VERSION "dbc-export 1 2025.20.8"

NS_ :

BS_:

BU_: ADSP APSB BB BMS CMP CP DAS DI DIF DIR DPB EPASTP EPASTS GTW ICR IDB OCS1P PM PMF PMR PTC RCM RCU TCU UI UIS VCLEFT VCSEC

BO_ 1297 RCM_alertLog: 8 RCM
 SG_ RCM_alertID M : 0|10@1+ (1,0) [0|1023] "" Vector__XXX
 SG_ RCM_a104_eventDriverBrakeApply m104 : 46|2@1+ (1,0) [0|2] "" Vector__XXX
 SG_ RCM_a104_eventAccelPedalPos m104 : 56|8@1+ (0.4,0) [0|101.6] "%" Vector__XXX
 SG_ RCM_a105_eventArmStatus m105 : 11|1@1+ (1,0) [0|1] "" Vector__XXX
 SG_ RCM_a105_eventFactoryMode m105 : 12|1@1+ (1,0) [0|1] "" Vector__XXX
 SG_ RCM_a105_eventDiagEnabled m105 : 13|1@1+ (1,0) [0|1] "" Vector__XXX
 SG_ RCM_a105_eventDriveOrientation m105 : 14|1@1+ (1,0) [0|1] "" Vector__XXX
 SG_ RCM_a105_imuLongAOffCompPosLife m105 : 16|1@1+ (1,0) [0|1] "" Vector__XXX
 SG_ RCM_a105_imuLongAOffCompNegLife m105 : 17|1@1+ (1,0) [0|1] "" Vector__XXX
 SG_ RCM_a105_imuLongAOffCompPosFLDC m105 : 18|1@1+ (1,0) [0|1] "" Vector__XXX
 SG_ RCM_a105_imuLongAOffCompNegFLDC m105 : 19|1@1+ (1,0) [0|1] "" Vector__XXX
 SG_ RCM_a105_imuLongAOffCompPosSLDC m105 : 20|1@1+ (1,0) [0|1] "" Vector__XXX
 SG_ RCM_a105_imuLongAOffCompNegSLDC m105 : 21|1@1+ (1,0) [0|1] "" Vector__XXX
 SG_ RCM_a105_eventIDFsignal m105 : 25|1@1+ (1,0) [0|1] "" Vector__XXX
 SG_ RCM_a105_eventFrontLeftSeatbelt m105 : 26|1@1+ (1,0) [0|1] "" Vector__XXX
 SG_ RCM_a105_eventFrontRightSeatbelt m105 : 27|1@1+ (1,0) [0|1] "" Vector__XXX
 SG_ RCM_a105_eventVehicleSpeed m105 : 28|12@1+ (0.08,-40) [-40|287.6] "kph" Vector__XXX
 SG_ RCM_a105_eventSteeringAngle m105 : 45|14@0+ (0.1,-819.2) [-819.2|819.1] "deg" Vector__XXX
 SG_ RCM_a105_eventDriverBrakeApply m105 : 46|2@1+ (1,0) [0|2] "" Vector__XXX
 SG_ RCM_a105_eventAccelPedalPos m105 : 56|8@1+ (0.4,0) [0|101.6] "%" Vector__XXX
 SG_ RCM_a106_eventArmStatus m106 : 11|1@1+ (1,0) [0|1] "" Vector__XXX
 SG_ RCM_a106_eventFactoryMode m106 : 12|1@1+ (1,0) [0|1] "" Vector__XXX
 SG_ RCM_a106_eventDiagEnabled m106 : 13|1@1+ (1,0) [0|1] "" Vector__XXX
 SG_ RCM_a106_eventDriveOrientation m106 : 14|1@1+ (1,0) [0|1] "" Vector__XXX
 SG_ RCM_a106_imuLatAcOffCompPosLife m106 : 16|1@1+ (1,0) [0|1] "" Vector__XXX
 SG_ RCM_a106_imuLatAcOffCompNegLife m106 : 17|1@1+ (1,0) [0|1] "" Vector__XXX
 SG_ RCM_a106_imuLatAcOffCompPosFLDC m106 : 18|1@1+ (1,0) [0|1] "" Vector__XXX
 SG_ RCM_a106_imuLatAcOffCompNegFLDC m106 : 19|1@1+ (1,0) [0|1] "" Vector__XXX
 SG_ RCM_a106_imuLatAcOffCompPosSLDC m106 : 20|1@1+ (1,0) [0|1] "" Vector__XXX
 SG_ RCM_a106_imuLatAcOffCompNegSLDC m106 : 21|1@1+ (1,0) [0|1] "" Vector__XXX
 SG_ RCM_a106_eventIDFsignal m106 : 25|1@1+ (1,0) [0|1] "" Vector__XXX
 SG_ RCM_a106_eventFrontLeftSeatbelt m106 : 26|1@1+ (1,0) [0|1] "" Vector__XXX
 SG_ RCM_a106_eventFrontRightSeatbelt m106 : 27|1@1+ (1,0) [0|1] "" Vector__XXX
 SG_ RCM_a106_eventVehicleSpeed m106 : 28|12@1+ (0.08,-40) [-40|287.6] "kph" Vector__XXX
 SG_ RCM_a106_eventSteeringAngle m106 : 45|14@0+ (0.1,-819.2) [-819.2|819.1] "deg" Vector__XXX
 SG_ RCM_a106_eventDriverBrakeApply m106 : 46|2@1+ (1,0) [0|2] "" Vector__XXX
 SG_ RCM_a106_eventAccelPedalPos m106 : 56|8@1+ (0.4,0) [0|101.6] "%" Vector__XXX
 SG_ RCM_a107_eventArmStatus m107 : 11|1@1+ (1,0) [0|1] "" Vector__XXX
 SG_ RCM_a107_eventFactoryMode m107 : 12|1@1+ (1,0) [0|1] "" Vector__XXX
 SG_ RCM_a107_eventDiagEnabled m107 : 13|1@1+ (1,0) [0|1] "" Vector__XXX
 SG_ RCM_a107_eventDriveOrientation m107 : 14|1@1+ (1,0) [0|1] "" Vector__XXX
 SG_ RCM_a107_imuVertAOffCompPosLife m107 : 16|1@1+ (1,0) [0|1] "" Vector__XXX
 SG_ RCM_a107_imuVertAOffCompNegLife m107 : 17|1@1+ (1,0) [0|1] "" Vector__XXX
 SG_ RCM_a107_imuVertAOffCompPosFLDC m107 : 18|1@1+ (1,0) [0|1] "" Vector__XXX
 SG_ RCM_a107_imuVertAOffCompNegFLDC m107 : 19|1@1+ (1,0) [0|1] "" Vector__XXX
 SG_ RCM_a107_imuVertAOffCompPosSLDC m107 : 20|1@1+ (1,0) [0|1] "" Vector__XXX
 SG_ RCM_a107_imuVertAOffCompNegSLDC m107 : 21|1@1+ (1,0) [0|1] "" Vector__XXX
 SG_ RCM_a107_eventIDFsignal m107 : 25|1@1+ (1,0) [0|1] "" Vector__XXX
 SG_ RCM_a107_eventFrontLeftSeatbelt m107 : 26|1@1+ (1,0) [0|1] "" Vector__XXX
 SG_ RCM_a107_eventFrontRightSeatbelt m107 : 27|1@1+ (1,0) [0|1] "" Vector__XXX
 SG_ RCM_a107_eventVehicleSpeed m107 : 28|12@1+ (0.08,-40) [-40|287.6] "kph" Vector__XXX
 SG_ RCM_a107_eventSteeringAngle m107 : 45|14@0+ (0.1,-819.2) [-819.2|819.1] "deg" Vector__XXX
 SG_ RCM_a107_eventDriverBrakeApply m107 : 46|2@1+ (1,0) [0|2] "" Vector__XXX
 SG_ RCM_a107_eventAccelPedalPos m107 : 56|8@1+ (0.4,0) [0|101.6] "%" Vector__XXX
 SG_ RCM_a108_eventArmStatus m108 : 11|1@1+ (1,0) [0|1] "" Vector__XXX
 SG_ RCM_a108_eventFactoryMode m108 : 12|1@1+ (1,0) [0|1] "" Vector__XXX
 SG_ RCM_a108_eventDiagEnabled m108 : 13|1@1+ (1,0) [0|1] "" Vector__XXX
 SG_ RCM_a108_eventDriveOrientation m108 : 14|1@1+ (1,0) [0|1] "" Vector__XXX
 SG_ RCM_a108_crashAlgoWakeupSig m108 : 16|1@1+ (1,0) [0|1] "" Vector__XXX
 SG_ RCM_a108_eventIDFsignal m108 : 25|1@1+ (1,0) [0|1] "" Vector__XXX
 SG_ RCM_a108_eventFrontLeftSeatbelt m108 : 26|1@1+ (1,0) [0|1] "" Vector__XXX
 SG_ RCM_a108_eventFrontRightSeatbelt m108 : 27|1@1+ (1,0) [0|1] "" Vector__XXX
 SG_ RCM_a108_eventVehicleSpeed m108 : 28|12@1+ (0.08,-40) [-40|287.6] "kph" Vector__XXX
 SG_ RCM_a108_eventSteeringAngle m108 : 45|14@0+ (0.1,-819.2) [-819.2|819.1] "deg" Vector__XXX
 SG_ RCM_a108_eventDriverBrakeApply m108 : 46|2@1+ (1,0) [0|2] "" Vector__XXX
 SG_ RCM_a108_eventAccelPedalPos m108 : 56|8@1+ (0.4,0) [0|101.6] "%" Vector__XXX
 SG_ RCM_a109_eventArmStatus m109 : 11|1@1+ (1,0) [0|1] "" Vector__XXX
 SG_ RCM_a109_eventFactoryMode m109 : 12|1@1+ (1,0) [0|1] "" Vector__XXX
 SG_ RCM_a109_eventDiagEnabled m109 : 13|1@1+ (1,0) [0|1] "" Vector__XXX
 SG_ RCM_a109_eventDriveOrientation m109 : 14|1@1+ (1,0) [0|1] "" Vector__XXX
 SG_ RCM_a109_immunityThrsholdCrossed m109 : 16|1@1+ (1,0) [0|1] "" Vector__XXX
 SG_ RCM_a109_eventIDFsignal m109 : 25|1@1+ (1,0) [0|1] "" Vector__XXX
 SG_ RCM_a109_eventFrontLeftSeatbelt m109 : 26|1@1+ (1,0) [0|1] "" Vector__XXX
 SG_ RCM_a109_eventFrontRightSeatbelt m109 : 27|1@1+ (1,0) [0|1] "" Vector__XXX
 SG_ RCM_a109_eventVehicleSpeed m109 : 28|12@1+ (0.08,-40) [-40|287.6] "kph" Vector__XXX
 SG_ RCM_a109_eventSteeringAngle m109 : 45|14@0+ (0.1,-819.2) [-819.2|819.1] "deg" Vector__XXX
 SG_ RCM_a109_eventDriverBrakeApply m109 : 46|2@1+ (1,0) [0|2] "" Vector__XXX
 SG_ RCM_a109_eventAccelPedalPos m109 : 56|8@1+ (0.4,0) [0|101.6] "%" Vector__XXX
 SG_ RCM_a110_eventArmStatus m110 : 11|1@1+ (1,0) [0|1] "" Vector__XXX
 SG_ RCM_a110_eventFactoryMode m110 : 12|1@1+ (1,0) [0|1] "" Vector__XXX
 SG_ RCM_a110_eventDiagEnabled m110 : 13|1@1+ (1,0) [0|1] "" Vector__XXX
 SG_ RCM_a110_eventDriveOrientation m110 : 14|1@1+ (1,0) [0|1] "" Vector__XXX
 SG_ RCM_a110_inFactoryMode m110 : 16|1@1+ (1,0) [0|1] "" Vector__XXX
 SG_ RCM_a110_eventIDFsignal m110 : 25|1@1+ (1,0) [0|1] "" Vector__XXX
 SG_ RCM_a110_eventFrontLeftSeatbelt m110 : 26|1@1+ (1,0) [0|1] "" Vector__XXX
 SG_ RCM_a110_eventFrontRightSeatbelt m110 : 27|1@1+ (1,0) [0|1] "" Vector__XXX
 SG_ RCM_a110_eventVehicleSpeed m110 : 28|12@1+ (0.08,-40) [-40|287.6] "kph" Vector__XXX
 SG_ RCM_a110_eventSteeringAngle m110 : 45|14@0+ (0.1,-819.2) [-819.2|819.1] "deg" Vector__XXX
 SG_ RCM_a110_eventDriverBrakeApply m110 : 46|2@1+ (1,0) [0|2] "" Vector__XXX
 SG_ RCM_a110_eventAccelPedalPos m110 : 56|8@1+ (0.4,0) [0|101.6] "%" Vector__XXX
 SG_ RCM_a112_eventArmStatus m112 : 11|1@1+ (1,0) [0|1] "" Vector__XXX
 SG_ RCM_a112_eventFactoryMode m112 : 12|1@1+ (1,0) [0|1] "" Vector__XXX
 SG_ RCM_a112_eventDiagEnabled m112 : 13|1@1+ (1,0) [0|1] "" Vector__XXX
 SG_ RCM_a112_eventDriveOrientation m112 : 14|1@1+ (1,0) [0|1] "" Vector__XXX
 SG_ RCM_a112_imuYawR8SnsrMonitTmp m112 : 16|1@1+ (1,0) [0|1] "" Vector__XXX
 SG_ RCM_a112_imuYawR8SnsrMonitPerm m112 : 17|1@1+ (1,0) [0|1] "" Vector__XXX
 SG_ RCM_a112_imuYawR8ChnlMonitTmp m112 : 19|1@1+ (1,0) [0|1] "" Vector__XXX
 SG_ RCM_a112_imuYawR8ChnlMonitPerm m112 : 20|1@1+ (1,0) [0|1] "" Vector__XXX
 SG_ RCM_a112_eventIDFsignal m112 : 25|1@1+ (1,0) [0|1] "" Vector__XXX
 SG_ RCM_a112_eventFrontLeftSeatbelt m112 : 26|1@1+ (1,0) [0|1] "" Vector__XXX
 SG_ RCM_a112_eventFrontRightSeatbelt m112 : 27|1@1+ (1,0) [0|1] "" Vector__XXX
 SG_ RCM_a112_eventVehicleSpeed m112 : 28|12@1+ (0.08,-40) [-40|287.6] "kph" Vector__XXX
 SG_ RCM_a112_eventSteeringAngle m112 : 45|14@0+ (0.1,-819.2) [-819.2|819.1] "deg" Vector__XXX
 SG_ RCM_a112_eventDriverBrakeApply m112 : 46|2@1+ (1,0) [0|2] "" Vector__XXX
 SG_ RCM_a112_eventAccelPedalPos m112 : 56|8@1+ (0.4,0) [0|101.6] "%" Vector__XXX
 SG_ RCM_a113_eventArmStatus m113 : 11|1@1+ (1,0) [0|1] "" Vector__XXX
 SG_ RCM_a113_eventFactoryMode m113 : 12|1@1+ (1,0) [0|1] "" Vector__XXX
 SG_ RCM_a113_eventDiagEnabled m113 : 13|1@1+ (1,0) [0|1] "" Vector__XXX
 SG_ RCM_a113_eventDriveOrientation m113 : 14|1@1+ (1,0) [0|1] "" Vector__XXX
 SG_ RCM_a113_imuPitchR8SnsrMonitTmp m113 : 16|1@1+ (1,0) [0|1] "" Vector__XXX
 SG_ RCM_a113_imuPitchR8SnsrMonitPerm m113 : 17|1@1+ (1,0) [0|1] "" Vector__XXX
 SG_ RCM_a113_imuPitchR8ChnlMonitTmp m113 : 18|1@1+ (1,0) [0|1] "" Vector__XXX
 SG_ RCM_a113_imuPitchR8ChnlMonitPerm m113 : 19|1@1+ (1,0) [0|1] "" Vector__XXX
 SG_ RCM_a113_eventIDFsignal m113 : 25|1@1+ (1,0) [0|1] "" Vector__XXX
 SG_ RCM_a113_eventFrontLeftSeatbelt m113 : 26|1@1+ (1,0) [0|1] "" Vector__XXX
 SG_ RCM_a113_eventFrontRightSeatbelt m113 : 27|1@1+ (1,0) [0|1] "" Vector__XXX
 SG_ RCM_a113_eventVehicleSpeed m113 : 28|12@1+ (0.08,-40) [-40|287.6] "kph" Vector__XXX
 SG_ RCM_a113_eventSteeringAngle m113 : 45|14@0+ (0.1,-819.2) [-819.2|819.1] "deg" Vector__XXX
 SG_ RCM_a113_eventDriverBrakeApply m113 : 46|2@1+ (1,0) [0|2] "" Vector__XXX
 SG_ RCM_a113_eventAccelPedalPos m113 : 56|8@1+ (0.4,0) [0|101.6] "%" Vector__XXX
 SG_ RCM_a114_eventArmStatus m114 : 11|1@1+ (1,0) [0|1] "" Vector__XXX
 SG_ RCM_a114_eventFactoryMode m114 : 12|1@1+ (1,0) [0|1] "" Vector__XXX
 SG_ RCM_a114_eventDiagEnabled m114 : 13|1@1+ (1,0) [0|1] "" Vector__XXX
 SG_ RCM_a114_eventDriveOrientation m114 : 14|1@1+ (1,0) [0|1] "" Vector__XXX
 SG_ RCM_a114_imuRollR8SnsrMonitTmp m114 : 16|1@1+ (1,0) [0|1] "" Vector__XXX
 SG_ RCM_a114_imuRollR8SnsrMonitPerm m114 : 17|1@1+ (1,0) [0|1] "" Vector__XXX
 SG_ RCM_a114_imuRollR8ChnlMonitTmp m114 : 18|1@1+ (1,0) [0|1] "" Vector__XXX
 SG_ RCM_a114_imuRollR8ChnlMonitPerm m114 : 19|1@1+ (1,0) [0|1] "" Vector__XXX
 SG_ RCM_a114_eventIDFsignal m114 : 25|1@1+ (1,0) [0|1] "" Vector__XXX
 SG_ RCM_a114_eventFrontLeftSeatbelt m114 : 26|1@1+ (1,0) [0|1] "" Vector__XXX
 SG_ RCM_a114_eventFrontRightSeatbelt m114 : 27|1@1+ (1,0) [0|1] "" Vector__XXX
 SG_ RCM_a114_eventVehicleSpeed m114 : 28|12@1+ (0.08,-40) [-40|287.6] "kph" Vector__XXX
 SG_ RCM_a114_eventSteeringAngle m114 : 45|14@0+ (0.1,-819.2) [-819.2|819.1] "deg" Vector__XXX
 SG_ RCM_a114_eventDriverBrakeApply m114 : 46|2@1+ (1,0) [0|2] "" Vector__XXX
 SG_ RCM_a114_eventAccelPedalPos m114 : 56|8@1+ (0.4,0) [0|101.6] "%" Vector__XXX
 SG_ RCM_a115_eventArmStatus m115 : 11|1@1+ (1,0) [0|1] "" Vector__XXX
 SG_ RCM_a115_eventFactoryMode m115 : 12|1@1+ (1,0) [0|1] "" Vector__XXX
 SG_ RCM_a115_eventDiagEnabled m115 : 13|1@1+ (1,0) [0|1] "" Vector__XXX
 SG_ RCM_a115_eventDriveOrientation m115 : 14|1@1+ (1,0) [0|1] "" Vector__XXX
 SG_ RCM_a115_imuLinAccChnlMonitTmp m115 : 16|1@1+ (1,0) [0|1] "" Vector__XXX
 SG_ RCM_a115_imuLinAccChnlMonitPerm m115 : 17|1@1+ (1,0) [0|1] "" Vector__XXX
 SG_ RCM_a115_eventIDFsignal m115 : 25|1@1+ (1,0) [0|1] "" Vector__XXX
 SG_ RCM_a115_eventFrontLeftSeatbelt m115 : 26|1@1+ (1,0) [0|1] "" Vector__XXX
 SG_ RCM_a115_eventFrontRightSeatbelt m115 : 27|1@1+ (1,0) [0|1] "" Vector__XXX
 SG_ RCM_a115_eventVehicleSpeed m115 : 28|12@1+ (0.08,-40) [-40|287.6] "kph" Vector__XXX
 SG_ RCM_a115_eventSteeringAngle m115 : 45|14@0+ (0.1,-819.2) [-819.2|819.1] "deg" Vector__XXX
 SG_ RCM_a115_eventDriverBrakeApply m115 : 46|2@1+ (1,0) [0|2] "" Vector__XXX
 SG_ RCM_a115_eventAccelPedalPos m115 : 56|8@1+ (0.4,0) [0|101.6] "%" Vector__XXX
 SG_ RCM_a116_eventArmStatus m116 : 11|1@1+ (1,0) [0|1] "" Vector__XXX
 SG_ RCM_a116_eventFactoryMode m116 : 12|1@1+ (1,0) [0|1] "" Vector__XXX
 SG_ RCM_a116_eventDiagEnabled m116 : 13|1@1+ (1,0) [0|1] "" Vector__XXX
 SG_ RCM_a116_eventDriveOrientation m116 : 14|1@1+ (1,0) [0|1] "" Vector__XXX
 SG_ RCM_a116_imuLatAccChnlMonitTmp m116 : 16|1@1+ (1,0) [0|1] "" Vector__XXX
 SG_ RCM_a116_imuLatAccChnlMonitPerm m116 : 17|1@1+ (1,0) [0|1] "" Vector__XXX
 SG_ RCM_a116_eventIDFsignal m116 : 25|1@1+ (1,0) [0|1] "" Vector__XXX
 SG_ RCM_a116_eventFrontLeftSeatbelt m116 : 26|1@1+ (1,0) [0|1] "" Vector__XXX
 SG_ RCM_a116_eventFrontRightSeatbelt m116 : 27|1@1+ (1,0) [0|1] "" Vector__XXX
 SG_ RCM_a116_eventVehicleSpeed m116 : 28|12@1+ (0.08,-40) [-40|287.6] "kph" Vector__XXX
 SG_ RCM_a116_eventSteeringAngle m116 : 45|14@0+ (0.1,-819.2) [-819.2|819.1] "deg" Vector__XXX
 SG_ RCM_a116_eventDriverBrakeApply m116 : 46|2@1+ (1,0) [0|2] "" Vector__XXX
 SG_ RCM_a116_eventAccelPedalPos m116 : 56|8@1+ (0.4,0) [0|101.6] "%" Vector__XXX
 SG_ RCM_a117_eventArmStatus m117 : 11|1@1+ (1,0) [0|1] "" Vector__XXX
 SG_ RCM_a117_eventFactoryMode m117 : 12|1@1+ (1,0) [0|1] "" Vector__XXX
 SG_ RCM_a117_eventDiagEnabled m117 : 13|1@1+ (1,0) [0|1] "" Vector__XXX
 SG_ RCM_a117_eventDriveOrientation m117 : 14|1@1+ (1,0) [0|1] "" Vector__XXX
 SG_ RCM_a117_imuZaccelChnlMonitTmp m117 : 16|1@1+ (1,0) [0|1] "" Vector__XXX
 SG_ RCM_a117_imuZaccelChnlMonitPerm m117 : 17|1@1+ (1,0) [0|1] "" Vector__XXX
 SG_ RCM_a117_eventIDFsignal m117 : 25|1@1+ (1,0) [0|1] "" Vector__XXX
 SG_ RCM_a117_eventFrontLeftSeatbelt m117 : 26|1@1+ (1,0) [0|1] "" Vector__XXX
 SG_ RCM_a117_eventFrontRightSeatbelt m117 : 27|1@1+ (1,0) [0|1] "" Vector__XXX
 SG_ RCM_a117_eventVehicleSpeed m117 : 28|12@1+ (0.08,-40) [-40|287.6] "kph" Vector__XXX
 SG_ RCM_a117_eventSteeringAngle m117 : 45|14@0+ (0.1,-819.2) [-819.2|819.1] "deg" Vector__XXX
 SG_ RCM_a117_eventDriverBrakeApply m117 : 46|2@1+ (1,0) [0|2] "" Vector__XXX
 SG_ RCM_a117_eventAccelPedalPos m117 : 56|8@1+ (0.4,0) [0|101.6] "%" Vector__XXX
 SG_ RCM_a118_eventArmStatus m118 : 11|1@1+ (1,0) [0|1] "" Vector__XXX
 SG_ RCM_a118_eventFactoryMode m118 : 12|1@1+ (1,0) [0|1] "" Vector__XXX
 SG_ RCM_a118_eventDiagEnabled m118 : 13|1@1+ (1,0) [0|1] "" Vector__XXX
 SG_ RCM_a118_eventDriveOrientation m118 : 14|1@1+ (1,0) [0|1] "" Vector__XXX
 SG_ RCM_a118_imuInPlaneSnsrMonitTmp m118 : 16|1@1+ (1,0) [0|1] "" Vector__XXX
 SG_ RCM_a118_imuInPlaneSnsrMonitPerm m118 : 17|1@1+ (1,0) [0|1] "" Vector__XXX
 SG_ RCM_a118_eventIDFsignal m118 : 25|1@1+ (1,0) [0|1] "" Vector__XXX
 SG_ RCM_a118_eventFrontLeftSeatbelt m118 : 26|1@1+ (1,0) [0|1] "" Vector__XXX
 SG_ RCM_a118_eventFrontRightSeatbelt m118 : 27|1@1+ (1,0) [0|1] "" Vector__XXX
 SG_ RCM_a118_eventVehicleSpeed m118 : 28|12@1+ (0.08,-40) [-40|287.6] "kph" Vector__XXX
 SG_ RCM_a118_eventSteeringAngle m118 : 45|14@0+ (0.1,-819.2) [-819.2|819.1] "deg" Vector__XXX
 SG_ RCM_a118_eventDriverBrakeApply m118 : 46|2@1+ (1,0) [0|2] "" Vector__XXX
 SG_ RCM_a118_eventAccelPedalPos m118 : 56|8@1+ (0.4,0) [0|101.6] "%" Vector__XXX

BO_ 881 RCM_alertMatrix: 8 RCM
 SG_ RCM_matrixIndex M : 0|4@1+ (1,0) [0|15] "" Vector__XXX
 SG_ RCM_a000_crashDetected m0 : 4|1@1+ (1,0) [0|1] "" Vector__XXX
 SG_ RCM_a001_nearDeploy m0 : 5|1@1+ (1,0) [0|1] "" Vector__XXX
 SG_ RCM_a002_airbagsNotArmed m0 : 6|1@1+ (1,0) [0|1] "" Vector__XXX
 SG_ RCM_a003_warningIndicator m0 : 7|1@1+ (1,0) [0|1] "" Vector__XXX
 SG_ RCM_a004_internalFault m0 : 8|1@1+ (1,0) [0|1] "" Vector__XXX
 SG_ RCM_a005_crcError m0 : 9|1@1+ (1,0) [0|1] "" Vector__XXX
 SG_ RCM_a006_batteryVoltageRange m0 : 10|1@1+ (1,0) [0|1] "" Vector__XXX
 SG_ RCM_a007_powerSupplyExternal m0 : 11|1@1+ (1,0) [0|1] "" Vector__XXX
 SG_ RCM_a008_powerSupplyInternal m0 : 12|1@1+ (1,0) [0|1] "" Vector__XXX
 SG_ RCM_a009_reprogramLimit m0 : 13|1@1+ (1,0) [0|1] "" Vector__XXX
 SG_ RCM_a010_scmDisabled m0 : 14|1@1+ (1,0) [0|1] "" Vector__XXX
 SG_ RCM_a011_eepromDataLocked m0 : 15|1@1+ (1,0) [0|1] "" Vector__XXX
 SG_ RCM_a012_vinStorage m0 : 16|1@1+ (1,0) [0|1] "" Vector__XXX
 SG_ RCM_a013_driverOrientation m0 : 17|1@1+ (1,0) [0|1] "" Vector__XXX
 SG_ RCM_a014_driverABStage1 m0 : 18|1@1+ (1,0) [0|1] "" Vector__XXX
 SG_ RCM_a015_driverABStage2 m0 : 19|1@1+ (1,0) [0|1] "" Vector__XXX
 SG_ RCM_a016_passABStage1 m0 : 20|1@1+ (1,0) [0|1] "" Vector__XXX
 SG_ RCM_a017_passABStage2 m0 : 21|1@1+ (1,0) [0|1] "" Vector__XXX
 SG_ RCM_a018_passengerActiveVent m0 : 22|1@1+ (1,0) [0|1] "" Vector__XXX
 SG_ RCM_a019_pretenShldrFrontLeft m0 : 23|1@1+ (1,0) [0|1] "" Vector__XXX
 SG_ RCM_a020_pretenShldFrontRight m0 : 24|1@1+ (1,0) [0|1] "" Vector__XXX
 SG_ RCM_a021_pretenLapFrontLeft m0 : 25|1@1+ (1,0) [0|1] "" Vector__XXX
 SG_ RCM_a022_pretenLapFrontRight m0 : 26|1@1+ (1,0) [0|1] "" Vector__XXX
 SG_ RCM_a023_loadLimiterLeftSide m0 : 27|1@1+ (1,0) [0|1] "" Vector__XXX
 SG_ RCM_a024_loadLimiterRightSide m0 : 28|1@1+ (1,0) [0|1] "" Vector__XXX
 SG_ RCM_a025_kneeABDriver m0 : 29|1@1+ (1,0) [0|1] "" Vector__XXX
 SG_ RCM_a026_kneeABFrontPassenger m0 : 30|1@1+ (1,0) [0|1] "" Vector__XXX
 SG_ RCM_a027_sideAB1stRowLeft m0 : 31|1@1+ (1,0) [0|1] "" Vector__XXX
 SG_ RCM_a028_sideAB1stRowRight m0 : 32|1@1+ (1,0) [0|1] "" Vector__XXX
 SG_ RCM_a029_driverABActiveVent m0 : 33|1@1+ (1,0) [0|1] "" Vector__XXX
 SG_ RCM_a030_farSideInboardAirbag m0 : 34|1@1+ (1,0) [0|1] "" Vector__XXX
 SG_ RCM_a031_frontCenterAirbag m0 : 35|1@1+ (1,0) [0|1] "" Vector__XXX
 SG_ RCM_a032_curtainABLeft m0 : 36|1@1+ (1,0) [0|1] "" Vector__XXX
 SG_ RCM_a033_curtainABRight m0 : 37|1@1+ (1,0) [0|1] "" Vector__XXX
 SG_ RCM_a034_preten2ndRowLeft m0 : 38|1@1+ (1,0) [0|1] "" Vector__XXX
 SG_ RCM_a035_preten2ndRowRight m0 : 39|1@1+ (1,0) [0|1] "" Vector__XXX
 SG_ RCM_a036_curAB2ndRowLeft m0 : 40|1@1+ (1,0) [0|1] "" Vector__XXX
 SG_ RCM_a037_curAB2ndRowRight m0 : 41|1@1+ (1,0) [0|1] "" Vector__XXX
 SG_ RCM_a038_unusedA m0 : 42|1@1+ (1,0) [0|1] "" Vector__XXX
 SG_ RCM_a039_unusedB m0 : 43|1@1+ (1,0) [0|1] "" Vector__XXX
 SG_ RCM_a040_hoodActuatorRight m0 : 44|1@1+ (1,0) [0|1] "" Vector__XXX
 SG_ RCM_a041_hoodActuatorLeft m0 : 45|1@1+ (1,0) [0|1] "" Vector__XXX
 SG_ RCM_a042_ens1Line m0 : 46|1@1+ (1,0) [0|1] "" Vector__XXX
 SG_ RCM_a043_ens2Line m0 : 47|1@1+ (1,0) [0|1] "" Vector__XXX
 SG_ RCM_a044_upFrontSensorLeft m0 : 48|1@1+ (1,0) [0|1] "" Vector__XXX
 SG_ RCM_a045_upFrontSensorRight m0 : 49|1@1+ (1,0) [0|1] "" Vector__XXX
 SG_ RCM_a046_sideAccelBPillarLeft m0 : 50|1@1+ (1,0) [0|1] "" Vector__XXX
 SG_ RCM_a047_sideAccelBPillarRight m0 : 51|1@1+ (1,0) [0|1] "" Vector__XXX
 SG_ RCM_a048_sideAccelCPillarLeft m0 : 52|1@1+ (1,0) [0|1] "" Vector__XXX
 SG_ RCM_a049_sideAccelCPillarRight m0 : 53|1@1+ (1,0) [0|1] "" Vector__XXX
 SG_ RCM_a050_upFrontSensorCenter m0 : 54|1@1+ (1,0) [0|1] "" Vector__XXX
 SG_ RCM_a051_pressureFrontLftDoor m0 : 55|1@1+ (1,0) [0|1] "" Vector__XXX
 SG_ RCM_a052_pressureFrontRtDoor m0 : 56|1@1+ (1,0) [0|1] "" Vector__XXX
 SG_ RCM_a053_pressurePedProLeft m0 : 57|1@1+ (1,0) [0|1] "" Vector__XXX
 SG_ RCM_a054_pressurePedProRight m0 : 58|1@1+ (1,0) [0|1] "" Vector__XXX
 SG_ RCM_a055_inertialMeasurement m0 : 59|1@1+ (1,0) [0|1] "" Vector__XXX
 SG_ RCM_a056_passengerFrontOCS m0 : 60|1@1+ (1,0) [0|1] "" Vector__XXX
 SG_ RCM_a057_driverOCS m0 : 61|1@1+ (1,0) [0|1] "" Vector__XXX
 SG_ RCM_a058_buckle1stRowLeft m0 : 62|1@1+ (1,0) [0|1] "" Vector__XXX
 SG_ RCM_a059_buckle1stRowRight m0 : 63|1@1+ (1,0) [0|1] "" Vector__XXX
 SG_ RCM_a060_stpsLeft m1 : 4|1@1+ (1,0) [0|1] "" Vector__XXX
 SG_ RCM_a061_stpsRight m1 : 5|1@1+ (1,0) [0|1] "" Vector__XXX
 SG_ RCM_a062_alrSwitch m1 : 6|1@1+ (1,0) [0|1] "" Vector__XXX
 SG_ RCM_a063_sbsw2ndRowRight m1 : 7|1@1+ (1,0) [0|1] "" Vector__XXX
 SG_ RCM_a064_hardwareCodingPin1 m1 : 8|1@1+ (1,0) [0|1] "" Vector__XXX
 SG_ RCM_a065_driverOrientConfigPin m1 : 9|1@1+ (1,0) [0|1] "" Vector__XXX
 SG_ RCM_a066_seatBackSw2ndRowLeft m1 : 10|1@1+ (1,0) [0|1] "" Vector__XXX
 SG_ RCM_a067_comCANInitFailure m1 : 11|1@1+ (1,0) [0|1] "" Vector__XXX
 SG_ RCM_a068_comChassisBusOff m1 : 12|1@1+ (1,0) [0|1] "" Vector__XXX
 SG_ RCM_a069_comCHCANPH7 m1 : 13|1@1+ (1,0) [0|1] "" Vector__XXX
 SG_ RCM_a070_comCHCANPH8 m1 : 14|1@1+ (1,0) [0|1] "" Vector__XXX
 SG_ RCM_a071_comCHCANPH9 m1 : 15|1@1+ (1,0) [0|1] "" Vector__XXX
 SG_ RCM_a072_comUnused m1 : 16|1@1+ (1,0) [0|1] "" Vector__XXX
 SG_ RCM_a073_comCHCANPH4 m1 : 17|1@1+ (1,0) [0|1] "" Vector__XXX
 SG_ RCM_a074_comCHCANPH5 m1 : 18|1@1+ (1,0) [0|1] "" Vector__XXX
 SG_ RCM_a075_comCHCANPH6 m1 : 19|1@1+ (1,0) [0|1] "" Vector__XXX
 SG_ RCM_a076_comEPBLStatus m1 : 20|1@1+ (1,0) [0|1] "" Vector__XXX
 SG_ RCM_a077_comEPBRStatus m1 : 21|1@1+ (1,0) [0|1] "" Vector__XXX
 SG_ RCM_a078_comOCS1PStatus m1 : 22|1@1+ (1,0) [0|1] "" Vector__XXX
 SG_ RCM_a079_comOCS1DStatus m1 : 23|1@1+ (1,0) [0|1] "" Vector__XXX
 SG_ RCM_a080_comGTWACS m1 : 24|1@1+ (1,0) [0|1] "" Vector__XXX
 SG_ RCM_a081_comVCFRONTLVPwr m1 : 25|1@1+ (1,0) [0|1] "" Vector__XXX
 SG_ RCM_a082_comUIodo m1 : 26|1@1+ (1,0) [0|1] "" Vector__XXX
 SG_ RCM_a083_comGTWCarState m1 : 27|1@1+ (1,0) [0|1] "" Vector__XXX
 SG_ RCM_a084_comTPMSStatus m1 : 28|1@1+ (1,0) [0|1] "" Vector__XXX
 SG_ RCM_a085_comGTWCarConfig m1 : 29|1@1+ (1,0) [0|1] "" Vector__XXX
 SG_ RCM_a086_comVINMIA m1 : 30|1@1+ (1,0) [0|1] "" Vector__XXX
 SG_ RCM_a087_comCANSilent m1 : 31|1@1+ (1,0) [0|1] "" Vector__XXX
 SG_ RCM_a088_comCHCANPH2 m1 : 32|1@1+ (1,0) [0|1] "" Vector__XXX
 SG_ RCM_a089_comCHCANPH3 m1 : 33|1@1+ (1,0) [0|1] "" Vector__XXX
 SG_ RCM_a090_comPartyBusOff m1 : 34|1@1+ (1,0) [0|1] "" Vector__XXX
 SG_ RCM_a091_comEPAS3PsysStatus m1 : 35|1@1+ (1,0) [0|1] "" Vector__XXX
 SG_ RCM_a092_comDASISF m1 : 36|1@1+ (1,0) [0|1] "" Vector__XXX
 SG_ RCM_a093_comVCLEFTStatus m1 : 37|1@1+ (1,0) [0|1] "" Vector__XXX
 SG_ RCM_a094_comVCRIGHTStatus m1 : 38|1@1+ (1,0) [0|1] "" Vector__XXX
 SG_ RCM_a095_comESPstatus m1 : 39|1@1+ (1,0) [0|1] "" Vector__XXX
 SG_ RCM_a096_comESPwheelSpeeds m1 : 40|1@1+ (1,0) [0|1] "" Vector__XXX
 SG_ RCM_a097_comDIspeed m1 : 41|1@1+ (1,0) [0|1] "" Vector__XXX
 SG_ RCM_a098_comDIchassisControl m1 : 42|1@1+ (1,0) [0|1] "" Vector__XXX
 SG_ RCM_a099_comDItorque m1 : 43|1@1+ (1,0) [0|1] "" Vector__XXX
 SG_ RCM_a100_comDIsystemStatus m1 : 44|1@1+ (1,0) [0|1] "" Vector__XXX
 SG_ RCM_a101_idfSystem m1 : 45|1@1+ (1,0) [0|1] "" Vector__XXX
 SG_ RCM_a102_imuYawR8OffstCompLim m1 : 46|1@1+ (1,0) [0|1] "" Vector__XXX
 SG_ RCM_a103_imuPtchR8OffstCompLim m1 : 47|1@1+ (1,0) [0|1] "" Vector__XXX
 SG_ RCM_a104_imuRollR8OffstCompLim m1 : 48|1@1+ (1,0) [0|1] "" Vector__XXX
 SG_ RCM_a105_imuLongAccOffstCompLim m1 : 49|1@1+ (1,0) [0|1] "" Vector__XXX
 SG_ RCM_a106_imuLatAccOffstCompLim m1 : 50|1@1+ (1,0) [0|1] "" Vector__XXX
 SG_ RCM_a107_imuVertAccOffstCompLim m1 : 51|1@1+ (1,0) [0|1] "" Vector__XXX
 SG_ RCM_a108_crashAlgoWakeup m1 : 52|1@1+ (1,0) [0|1] "" Vector__XXX
 SG_ RCM_a109_abuseImmunity m1 : 53|1@1+ (1,0) [0|1] "" Vector__XXX
 SG_ RCM_a110_factoryMode m1 : 54|1@1+ (1,0) [0|1] "" Vector__XXX
 SG_ RCM_a111_diagnosticsEnabled m1 : 55|1@1+ (1,0) [0|1] "" Vector__XXX
 SG_ RCM_a112_imuYawRate m1 : 56|1@1+ (1,0) [0|1] "" Vector__XXX
 SG_ RCM_a113_imuPitchRate m1 : 57|1@1+ (1,0) [0|1] "" Vector__XXX
 SG_ RCM_a114_imuRollRate m1 : 58|1@1+ (1,0) [0|1] "" Vector__XXX
 SG_ RCM_a115_imuLinearAcceleration m1 : 59|1@1+ (1,0) [0|1] "" Vector__XXX
 SG_ RCM_a116_imuLateralAcceleration m1 : 60|1@1+ (1,0) [0|1] "" Vector__XXX
 SG_ RCM_a117_imuVerticalAcceleration m1 : 61|1@1+ (1,0) [0|1] "" Vector__XXX
 SG_ RCM_a118_imuInPlaneAcceleration m1 : 62|1@1+ (1,0) [0|1] "" Vector__XXX

BO_ 1471 RCU_alertLog: 8 RCU
 SG_ RCU_alertID M : 0|6@1+ (1,0) [0|63] "" Vector__XXX
 SG_ RCU_alertState : 15|1@1+ (1,0) [0|1] "" Vector__XXX
 SG_ RCU_a010_sensorPowerSupply m10 : 16|1@1+ (1,0) [0|1] "" Vector__XXX
 SG_ RCU_a010_sensorHardware m10 : 17|1@1+ (1,0) [0|1] "" Vector__XXX
 SG_ RCU_a010_sensorSignal m10 : 18|1@1+ (1,0) [0|1] "" Vector__XXX
 SG_ RCU_a023_validityOnChassisBus m23 : 16|1@1+ (1,0) [0|1] "" Vector__XXX
 SG_ RCU_a023_validityOnPartyBus m23 : 17|1@1+ (1,0) [0|1] "" Vector__XXX
 SG_ RCU_a024_validityOnChassisBus m24 : 16|1@1+ (1,0) [0|1] "" Vector__XXX
 SG_ RCU_a024_validityOnPartyBus m24 : 17|1@1+ (1,0) [0|1] "" Vector__XXX
 SG_ RCU_a025_validityOnChassisBus m25 : 16|1@1+ (1,0) [0|1] "" Vector__XXX
 SG_ RCU_a025_validityOnPartyBus m25 : 17|1@1+ (1,0) [0|1] "" Vector__XXX
 SG_ RCU_a035_validityOnChassisBus m35 : 16|1@1+ (1,0) [0|1] "" Vector__XXX
 SG_ RCU_a035_validityOnPartyBus m35 : 17|1@1+ (1,0) [0|1] "" Vector__XXX
 SG_ RCU_a036_validityOnChassisBus m36 : 16|1@1+ (1,0) [0|1] "" Vector__XXX
 SG_ RCU_a036_validityOnPartyBus m36 : 17|1@1+ (1,0) [0|1] "" Vector__XXX

BO_ 998 RCU_alertMatrix: 8 RCU
 SG_ RCU_matrixIndex M : 0|4@1+ (1,0) [0|15] "" Vector__XXX
 SG_ RCU_a001_valveDriverFault m0 : 4|1@1+ (1,0) [0|1] "" Vector__XXX
 SG_ RCU_a002_solenoidValveFault m0 : 5|1@1+ (1,0) [0|1] "" Vector__XXX
 SG_ RCU_a003_pumpMotorFault m0 : 6|1@1+ (1,0) [0|1] "" Vector__XXX
 SG_ RCU_a004_supplyOvervoltage m0 : 7|1@1+ (1,0) [0|1] "" Vector__XXX
 SG_ RCU_a005_supplyUndervoltage m0 : 8|1@1+ (1,0) [0|1] "" Vector__XXX
 SG_ RCU_a006_wakeLineOpen m0 : 9|1@1+ (1,0) [0|1] "" Vector__XXX
 SG_ RCU_a007_pressureSensorFault m0 : 10|1@1+ (1,0) [0|1] "" Vector__XXX
 SG_ RCU_a008_pressureNotCalibrated m0 : 11|1@1+ (1,0) [0|1] "" Vector__XXX
 SG_ RCU_a009_brakeFluidLow m0 : 12|1@1+ (1,0) [0|1] "" Vector__XXX
 SG_ RCU_a010_pedalSensorFault m0 : 13|1@1+ (1,0) [0|1] "" Vector__XXX
 SG_ RCU_a011_idbPedalTravelMismatch m0 : 14|1@1+ (1,0) [0|1] "" Vector__XXX
 SG_ RCU_a012_pedalSensorNotCal m0 : 15|1@1+ (1,0) [0|1] "" Vector__XXX
 SG_ RCU_a013_mcuGenericFault m0 : 16|1@1+ (1,0) [0|1] "" Vector__XXX
 SG_ RCU_a014_asicTempHigh m0 : 17|1@1+ (1,0) [0|1] "" Vector__XXX
 SG_ RCU_a015_fluidLeakDetected m0 : 18|1@1+ (1,0) [0|1] "" Vector__XXX
 SG_ RCU_a016_partyBusOff m0 : 19|1@1+ (1,0) [0|1] "" Vector__XXX
 SG_ RCU_a017_chassisBusOff m0 : 20|1@1+ (1,0) [0|1] "" Vector__XXX
 SG_ RCU_a018_DItorquePathFaulted m0 : 21|1@1+ (1,0) [0|1] "" Vector__XXX
 SG_ RCU_a019_DItorquePathActive m0 : 22|1@1+ (1,0) [0|1] "" Vector__XXX
 SG_ RCU_a020_BBstatusDLC m0 : 23|1@1+ (1,0) [0|1] "" Vector__XXX
 SG_ RCU_a021_BBstatusChecksum m0 : 24|1@1+ (1,0) [0|1] "" Vector__XXX
 SG_ RCU_a022_BBstatusCounter m0 : 25|1@1+ (1,0) [0|1] "" Vector__XXX
 SG_ RCU_a023_IDBstatusDLC m0 : 26|1@1+ (1,0) [0|1] "" Vector__XXX
 SG_ RCU_a024_IDBstatusChecksum m0 : 27|1@1+ (1,0) [0|1] "" Vector__XXX
 SG_ RCU_a025_IDBstatusCounter m0 : 28|1@1+ (1,0) [0|1] "" Vector__XXX
 SG_ RCU_a026_DIchassisControlDLC m0 : 29|1@1+ (1,0) [0|1] "" Vector__XXX
 SG_ RCU_a027_DIchassisCtrlChecksum m0 : 30|1@1+ (1,0) [0|1] "" Vector__XXX
 SG_ RCU_a028_DIchassisControlCounter m0 : 31|1@1+ (1,0) [0|1] "" Vector__XXX
 SG_ RCU_a029_PMstate2DLC m0 : 32|1@1+ (1,0) [0|1] "" Vector__XXX
 SG_ RCU_a030_PMstate2Checksum m0 : 33|1@1+ (1,0) [0|1] "" Vector__XXX
 SG_ RCU_a031_PMstate2Counter m0 : 34|1@1+ (1,0) [0|1] "" Vector__XXX
 SG_ RCU_a032_VCFRONTLVPowerStateDLC m0 : 35|1@1+ (1,0) [0|1] "" Vector__XXX
 SG_ RCU_a033_VCFRONTLVPowerStateChec m0 : 36|1@1+ (1,0) [0|1] "" Vector__XXX
 SG_ RCU_a034_VCFRONTLVPowerStateCoun m0 : 37|1@1+ (1,0) [0|1] "" Vector__XXX
 SG_ RCU_a035_IDBpcpInvalid m0 : 38|1@1+ (1,0) [0|1] "" Vector__XXX
 SG_ RCU_a036_IDBpspInvalid m0 : 39|1@1+ (1,0) [0|1] "" Vector__XXX
 SG_ RCU_a037_IDBinputRodStrokeInvali m0 : 40|1@1+ (1,0) [0|1] "" Vector__XXX
 SG_ RCU_a038_DIsystemStatusDLC m0 : 41|1@1+ (1,0) [0|1] "" Vector__XXX
 SG_ RCU_a039_DIaccelPosInvalid m0 : 42|1@1+ (1,0) [0|1] "" Vector__XXX
 SG_ RCU_a040_DIgearInvalid m0 : 43|1@1+ (1,0) [0|1] "" Vector__XXX
 SG_ RCU_a041_DIsystemStatusCounter m0 : 44|1@1+ (1,0) [0|1] "" Vector__XXX
 SG_ RCU_a042_DIsystemStatusChecksum m0 : 45|1@1+ (1,0) [0|1] "" Vector__XXX
 SG_ RCU_a043_VCFRONTiBoosterLvStateI m0 : 46|1@1+ (1,0) [0|1] "" Vector__XXX
 SG_ RCU_a044_VCFRONTsensorsMIA m0 : 47|1@1+ (1,0) [0|1] "" Vector__XXX
 SG_ RCU_a045_VCFRONTtempInvalid m0 : 48|1@1+ (1,0) [0|1] "" Vector__XXX
 SG_ RCU_a046_brakeFluidLevelSNA m0 : 49|1@1+ (1,0) [0|1] "" Vector__XXX
 SG_ RCU_a047_ESPwheelSpeedsDLC m0 : 50|1@1+ (1,0) [0|1] "" Vector__XXX
 SG_ RCU_a048_ESPFrLWSSLInvalid m0 : 51|1@1+ (1,0) [0|1] "" Vector__XXX
 SG_ RCU_a049_ESPFrRWSSLInvalid m0 : 52|1@1+ (1,0) [0|1] "" Vector__XXX
 SG_ RCU_a050_ESPReLWSSLInvalid m0 : 53|1@1+ (1,0) [0|1] "" Vector__XXX
 SG_ RCU_a051_ESPReRWSSLInvalid m0 : 54|1@1+ (1,0) [0|1] "" Vector__XXX
 SG_ RCU_a052_ESPwheelSpeedsCounter m0 : 55|1@1+ (1,0) [0|1] "" Vector__XXX
 SG_ RCU_a053_ESPwheelSpeedsChecksum m0 : 56|1@1+ (1,0) [0|1] "" Vector__XXX
 SG_ RCU_a054_IDBcircuitPressFaulted m0 : 57|1@1+ (1,0) [0|1] "" Vector__XXX
 SG_ RCU_a055_IDBsimulatorPressFaulte m0 : 58|1@1+ (1,0) [0|1] "" Vector__XXX
 SG_ RCU_a056_redundantControllerIsMa m0 : 59|1@1+ (1,0) [0|1] "" Vector__XXX
 SG_ RCU_a057_PMebrCmdStateInvalid m0 : 60|1@1+ (1,0) [0|1] "" Vector__XXX
 SG_ RCU_a058_DIbrakeTorqueCommandAnd m0 : 61|1@1+ (1,0) [0|1] "" Vector__XXX

BO_ 831 RCU_info: 8 RCU
 SG_ RCU_infoIndex M : 0|8@1+ (1,0) [0|255] "" Vector__XXX
 SG_ RCU_infoPcbaID m11 : 16|8@1+ (1,0) [0|255] "" Vector__XXX
 SG_ RCU_infoAssemblyID m11 : 24|8@1+ (1,0) [0|255] "" Vector__XXX
 SG_ RCU_infoUsageID m11 : 32|16@1+ (1,0) [0|65535] "" Vector__XXX
 SG_ RCU_infoSubUsageID m11 : 48|16@1+ (1,0) [0|65535] "" Vector__XXX

BO_ 1410 TCU_alertLog: 8 TCU
 SG_ TCU_alertID M : 0|3@1+ (1,0) [0|7] "" Vector__XXX
 SG_ TCU_alertState : 15|1@1+ (1,0) [0|1] "" Vector__XXX
 SG_ TCU_w001_FailCode m1 : 16|32@1+ (1,0) [0|4294967295] "" Vector__XXX
 SG_ TCU_w002_RejCause m2 : 16|32@1+ (1,0) [0|4294967295] "" Vector__XXX
 SG_ TCU_w003_CallFailCode m3 : 16|32@1+ (1,0) [0|4294967295] "" Vector__XXX
 SG_ TCU_w004_MSDFailCode m4 : 16|32@1+ (1,0) [0|4294967295] "" Vector__XXX
 SG_ TCU_w006_Count m6 : 16|32@1+ (1,0) [0|4294967295] "" Vector__XXX

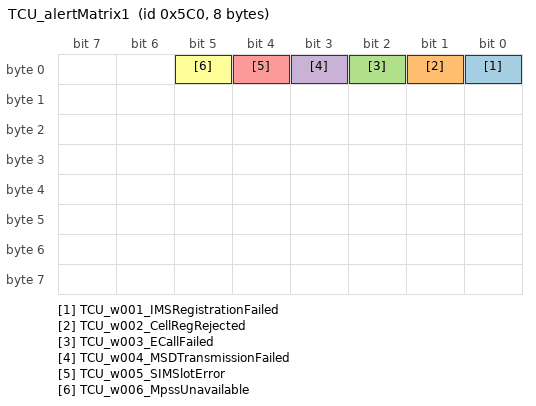
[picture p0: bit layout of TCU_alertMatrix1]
BO_ 1472 TCU_alertMatrix1: 8 TCU
 SG_ TCU_w001_IMSRegistrationFailed : 0|1@1+ (1,0) [0|1] "" Vector__XXX
 SG_ TCU_w002_CellRegRejected : 1|1@1+ (1,0) [0|1] "" Vector__XXX
 SG_ TCU_w003_ECallFailed : 2|1@1+ (1,0) [0|1] "" Vector__XXX
 SG_ TCU_w004_MSDTransmissionFailed : 3|1@1+ (1,0) [0|1] "" Vector__XXX
 SG_ TCU_w005_SIMSlotError : 4|1@1+ (1,0) [0|1] "" Vector__XXX
 SG_ TCU_w006_MpssUnavailable : 5|1@1+ (1,0) [0|1] "" Vector__XXX

BO_ 1409 TCU_log: 8 TCU
 SG_ TCU_logMux M : 0|32@1+ (1,0) [0|4294967295] "" Vector__XXX
 SG_ TCU_cpuTemp m0 : 32|32@1+ (1,0) [0|4294967295] "C" Vector__XXX
 SG_ TCU_cpuUsage m1 : 32|32@1+ (1,0) [0|4294967295] "%" Vector__XXX
 SG_ TCU_mdmCoreTemperature m2 : 32|32@1+ (1,0) [0|4294967295] "C" Vector__XXX
 SG_ TCU_availableMemory m3 : 32|32@1+ (1,0) [0|4294967295] "KB" Vector__XXX
 SG_ TCU_pwm m4 : 32|32@1+ (1,0) [0|4294967295] "" Vector__XXX
 SG_ TCU_pwmcap m5 : 32|32@1+ (1,0) [0|4294967295] "" Vector__XXX
 SG_ TCU_totalResumes m6 : 32|32@1+ (1,0) [0|4294967295] "" Vector__XXX
 SG_ TCU_mdmUplinkQueueSize m7 : 32|32@1+ (1,0) [0|4294967295] "bytes" Vector__XXX
 SG_ TCU_mdmRSRP m8 : 32|32@1- (1,0) [-2147483648|2147483647] "dBm" Vector__XXX
 SG_ TCU_mdmSINR m9 : 32|32@1- (1,0) [-2147483648|2147483647] "dBm" Vector__XXX
 SG_ TCU_mdmUplinkAllowedRate m10 : 32|32@1+ (1,0) [0|4294967295] "Kbps" Vector__XXX
 SG_ TCU_mdmUplinkAvgRage m11 : 32|32@1+ (1,0) [0|4294967295] "" Vector__XXX
 SG_ TCU_mdmServiceState m12 : 32|32@1+ (1,0) [0|4294967295] "" Vector__XXX
 SG_ TCU_mdmIMSStatus m13 : 32|32@1+ (1,0) [0|4294967295] "" Vector__XXX
 SG_ TCU_mdmSIMStatus m14 : 32|32@1+ (1,0) [0|4294967295] "" Vector__XXX
 SG_ TCU_mdmBusyActive m15 : 32|32@1+ (1,0) [0|4294967294] "" Vector__XXX

BO_ 1408 TCU_status: 8 TCU
 SG_ TCU_statusMux M : 0|32@1+ (1,0) [0|4294967295] "" Vector__XXX
 SG_ TCU_wakeUpReason m0 : 32|32@1+ (1,0) [0|4294967294] "" Vector__XXX
 SG_ TCU_tcuCmdId m1 : 32|1@1+ (1,0) [0|1] "" Vector__XXX
 SG_ TCU_goingToSleep m2 : 32|32@1+ (1,0) [0|4294967294] "" Vector__XXX

BO_ 1056 UIS_log: 8 UIS
 SG_ UIS_logMux M : 0|32@1+ (1,0) [0|4294967295] "" Vector__XXX
 SG_ UIS_zramWriteTicks m0 : 32|32@1+ (1,0) [0|4294967295] "" Vector__XXX
 SG_ UIS_zramWriteIO m1 : 32|32@1+ (1,0) [0|4294967295] "" Vector__XXX
 SG_ UIS_zramReadTicks m2 : 32|32@1+ (1,0) [0|4294967295] "" Vector__XXX
 SG_ UIS_zramReadIO m3 : 32|32@1+ (1,0) [0|4294967295] "" Vector__XXX
 SG_ UIS_zramOriginalSize m4 : 32|32@1+ (1,0) [0|4294967295] "" Vector__XXX
 SG_ UIS_zramNotifyFree m5 : 32|32@1+ (1,0) [0|4294967295] "" Vector__XXX
 SG_ UIS_zramInvalidIO m6 : 32|32@1+ (1,0) [0|4294967295] "" Vector__XXX
 SG_ UIS_zramFailedWrites m7 : 32|32@1+ (1,0) [0|4294967295] "" Vector__XXX
 SG_ UIS_zramFailedReads m8 : 32|32@1+ (1,0) [0|4294967295] "" Vector__XXX
 SG_ UIS_zramCompressionRatio m9 : 32|32@1+ (1,0) [0|4294967295] "" Vector__XXX
 SG_ UIS_zramCompressedSize m10 : 32|32@1+ (1,0) [0|4294967295] "" Vector__XXX
 SG_ UIS_wifiTemperature m11 : 32|32@1+ (1,0) [0|4294967295] "" Vector__XXX
 SG_ UIS_wifiStackState m12 : 32|32@1+ (1,0) [0|4294967295] "" Vector__XXX
 SG_ UIS_wifiStackReady m13 : 32|32@1+ (1,0) [0|4294967295] "" Vector__XXX
 SG_ UIS_wifiBars m14 : 32|32@1+ (1,0) [0|4294967295] "" Vector__XXX
 SG_ UIS_wifiAutoJoinLowRSSI m15 : 32|32@1+ (1,0) [0|1] "" Vector__XXX
 SG_ UIS_webbrowserMemUsage m16 : 32|32@1+ (1,0) [0|4294967295] "" Vector__XXX
 SG_ UIS_webbrowserCPUUsage m17 : 32|32@1+ (1,0) [0|4294967295] "" Vector__XXX
 SG_ UIS_vmtouchMemUsage m18 : 32|32@1+ (1,0) [0|4294967295] "" Vector__XXX
 SG_ UIS_vmtouchCPUUsage m19 : 32|32@1+ (1,0) [0|4294967295] "" Vector__XXX
 SG_ UIS_videodMemUsage m20 : 32|32@1+ (1,0) [0|4294967295] "" Vector__XXX
 SG_ UIS_videodCPUUsage m21 : 32|32@1+ (1,0) [0|4294967295] "" Vector__XXX
 SG_ UIS_vehicleMemUsage m22 : 32|32@1+ (1,0) [0|4294967295] "" Vector__XXX
 SG_ UIS_vehicleCPUUsage m23 : 32|32@1+ (1,0) [0|4294967295] "" Vector__XXX
 SG_ UIS_valhallaserverMemUsage m24 : 32|32@1+ (1,0) [0|4294967295] "" Vector__XXX
 SG_ UIS_valhallaserverCPUUsage m25 : 32|32@1+ (1,0) [0|4294967295] "" Vector__XXX
 SG_ UIS_valetMode m26 : 32|32@1+ (1,0) [0|1] "" Vector__XXX
 SG_ UIS_uiQtCarUptime m27 : 32|32@1+ (1,0) [0|4294967295] "" Vector__XXX
 SG_ UIS_uiQtCarSwapUsage m28 : 32|32@1+ (1,0) [0|4294967295] "" Vector__XXX
 SG_ UIS_uiMeanFPS m29 : 32|32@1+ (1,0) [0|4294967295] "" Vector__XXX
 SG_ UIS_uiMaxFrametime m30 : 32|32@1+ (1,0) [0|4294967295] "" Vector__XXX
 SG_ UIS_uiFramesOver200Ms m31 : 32|32@1+ (1,0) [0|4294967295] "" Vector__XXX
 SG_ UIS_uiFramesOver100Ms m32 : 32|32@1+ (1,0) [0|4294967295] "" Vector__XXX
 SG_ UIS_tunerVoltageUBatt m33 : 32|32@1+ (1,0) [0|4294967295] "" Vector__XXX
 SG_ UIS_tunerVoltageOperation m34 : 32|32@1+ (1,0) [0|4294967295] "" Vector__XXX
 SG_ UIS_tunerVoltageMQS m35 : 32|32@1+ (1,0) [0|4294967295] "" Vector__XXX
 SG_ UIS_tunerVoltageAntenna2 m36 : 32|32@1+ (1,0) [0|4294967295] "" Vector__XXX
 SG_ UIS_tunerVoltageAntenna1 m37 : 32|32@1+ (1,0) [0|4294967295] "" Vector__XXX
 SG_ UIS_tunerVoltage3V3 m38 : 32|32@1+ (1,0) [0|4294967295] "" Vector__XXX
 SG_ UIS_tunerVoltage1V8 m39 : 32|32@1+ (1,0) [0|4294967295] "" Vector__XXX
 SG_ UIS_tunerTemperatureFahrenheit m40 : 32|32@1+ (1,0) [0|4294967295] "" Vector__XXX
 SG_ UIS_tunerTemperatureCelsius m41 : 32|32@1+ (1,0) [0|4294967295] "" Vector__XXX
 SG_ UIS_tunerCurrentAntenna2 m42 : 32|32@1+ (1,0) [0|4294967295] "" Vector__XXX
 SG_ UIS_tunerCurrentAntenna1 m43 : 32|32@1+ (1,0) [0|4294967295] "" Vector__XXX
 SG_ UIS_touchEventsAggCount m44 : 32|32@1+ (1,0) [0|4294967295] "" Vector__XXX
 SG_ UIS_tmserverMemUsage m45 : 32|32@1+ (1,0) [0|4294967295] "" Vector__XXX
 SG_ UIS_tmserverCPUUsage m46 : 32|32@1+ (1,0) [0|4294967295] "" Vector__XXX
 SG_ UIS_testDriveMode m47 : 32|32@1+ (1,0) [0|4294967295] "" Vector__XXX
 SG_ UIS_teslachromiumMemUsage m48 : 32|32@1+ (1,0) [0|4294967295] "" Vector__XXX
 SG_ UIS_teslachromiumCPUUsage m49 : 32|32@1+ (1,0) [0|4294967295] "" Vector__XXX
 SG_ UIS_teslacefzygotMemUsage m50 : 32|32@1+ (1,0) [0|4294967295] "" Vector__XXX
 SG_ UIS_teslacefzygotCPUUsage m51 : 32|32@1+ (1,0) [0|4294967295] "" Vector__XXX
 SG_ UIS_teslacefgpuMemUsage m52 : 32|32@1+ (1,0) [0|4294967295] "" Vector__XXX
 SG_ UIS_teslacefgpuCPUUsage m53 : 32|32@1+ (1,0) [0|4294967295] "" Vector__XXX
 SG_ UIS_teslaMediaCacheSize m54 : 32|32@1+ (1,0) [0|4294967295] "" Vector__XXX
 SG_ UIS_teslaMediaCacheCost m55 : 32|32@1+ (1,0) [0|4294967295] "" Vector__XXX
 SG_ UIS_tegraModemManState m56 : 32|32@1+ (1,0) [0|4294967295] "" Vector__XXX
 SG_ UIS_systemWakeTime m57 : 32|32@1+ (1,0) [0|4294967295] "" Vector__XXX
 SG_ UIS_systemUptime m58 : 32|32@1+ (1,0) [0|4294967295] "" Vector__XXX
 SG_ UIS_systemMemSwapUsage m59 : 32|32@1+ (1,0) [0|4294967295] "" Vector__XXX
 SG_ UIS_suspensionGeofence m60 : 32|32@1+ (1,0) [0|1] "" Vector__XXX
 SG_ UIS_superchargePaymentNeeded m61 : 32|32@1+ (1,0) [0|4294967295] "" Vector__XXX
 SG_ UIS_sudokuMemUsage m62 : 32|32@1+ (1,0) [0|4294967295] "" Vector__XXX
 SG_ UIS_sudokuCPUUsage m63 : 32|32@1+ (1,0) [0|4294967295] "" Vector__XXX
 SG_ UIS_spotifyserverMemUsage m64 : 32|32@1+ (1,0) [0|4294967295] "" Vector__XXX
 SG_ UIS_spotifyserverCPUUsage m65 : 32|32@1+ (1,0) [0|4294967295] "" Vector__XXX
 SG_ UIS_speechrecoMemUsage m66 : 32|32@1+ (1,0) [0|4294967295] "" Vector__XXX
 SG_ UIS_speechrecoCPUUsage m67 : 32|32@1+ (1,0) [0|4294967295] "" Vector__XXX
 SG_ UIS_solitaireMemUsage m68 : 32|32@1+ (1,0) [0|4294967295] "" Vector__XXX
 SG_ UIS_solitaireCPUUsage m69 : 32|32@1+ (1,0) [0|4294967295] "" Vector__XXX
 SG_ UIS_sleepType m70 : 32|32@1+ (1,0) [0|4294967295] "" Vector__XXX
 SG_ UIS_sleepTime m71 : 32|32@1+ (1,0) [0|4294967295] "" Vector__XXX
 SG_ UIS_sleepState m72 : 32|32@1+ (1,0) [0|4294967295] "" Vector__XXX
 SG_ UIS_sleepCount m73 : 32|32@1+ (1,0) [0|4294967295] "" Vector__XXX
 SG_ UIS_slackerLoginResult m74 : 32|32@1+ (1,0) [0|4294967295] "" Vector__XXX
 SG_ UIS_settingsAutoTurnSignal m75 : 32|32@1+ (1,0) [0|4294967295] "" Vector__XXX
 SG_ UIS_serviceModePlus m76 : 32|32@1+ (1,0) [0|4294967295] "" Vector__XXX
 SG_ UIS_serviceMode m77 : 32|32@1+ (1,0) [0|4294967295] "" Vector__XXX
 SG_ UIS_serverMemUsage m78 : 32|32@1+ (1,0) [0|4294967295] "" Vector__XXX
 SG_ UIS_serverCPUUsage m79 : 32|32@1+ (1,0) [0|4294967295] "" Vector__XXX
 SG_ UIS_sentryState m80 : 32|32@1+ (1,0) [0|4294967295] "" Vector__XXX
 SG_ UIS_sentryNeedsNap m81 : 32|32@1+ (1,0) [0|4294967295] "" Vector__XXX
 SG_ UIS_sentryIncidentCount m82 : 32|32@1+ (1,0) [0|4294967295] "" Vector__XXX
 SG_ UIS_scheduledChargingMode m83 : 32|32@1+ (1,0) [0|4294967295] "" Vector__XXX
 SG_ UIS_scheduleChargeStartTime m84 : 32|32@1+ (1,0) [0|4294967295] "" Vector__XXX
 SG_ UIS_scheduleChargeEndTime m85 : 32|32@1+ (1,0) [0|4294967295] "" Vector__XXX
 SG_ UIS_remoteRequestType m86 : 32|32@1+ (1,0) [0|4294967295] "" Vector__XXX
 SG_ UIS_releasenotesMemUsage m87 : 32|32@1+ (1,0) [0|4294967295] "" Vector__XXX
 SG_ UIS_releasenotesCPUUsage m88 : 32|32@1+ (1,0) [0|4294967295] "" Vector__XXX
 SG_ UIS_rearDisplayUserPresent m89 : 32|32@1+ (1,0) [0|1] "" Vector__XXX
 SG_ UIS_rearDisplayState m90 : 32|32@1+ (1,0) [0|4294967295] "" Vector__XXX
 SG_ UIS_radioserveMemUsage m91 : 32|32@1+ (1,0) [0|4294967295] "" Vector__XXX
 SG_ UIS_radioserveCPUUsage m92 : 32|32@1+ (1,0) [0|4294967295] "" Vector__XXX
 SG_ UIS_qtcarMemUsage m93 : 32|32@1+ (1,0) [0|4294967295] "" Vector__XXX
 SG_ UIS_qtcarCPUUsage m94 : 32|32@1+ (1,0) [0|4294967295] "" Vector__XXX
 SG_ UIS_psiMemSome m95 : 32|32@1+ (1,0) [0|4294967295] "" Vector__XXX
 SG_ UIS_psiMemFull m96 : 32|32@1+ (1,0) [0|4294967295] "" Vector__XXX
 SG_ UIS_psiIOSome m97 : 32|32@1+ (1,0) [0|4294967295] "" Vector__XXX
 SG_ UIS_psiIOFull m98 : 32|32@1+ (1,0) [0|4294967295] "" Vector__XXX
 SG_ UIS_psiCpuSome m99 : 32|32@1+ (1,0) [0|4294967295] "" Vector__XXX
 SG_ UIS_powerManagerState m100 : 32|5@1+ (1,0) [0|31] "" Vector__XXX
 SG_ UIS_polytopiax8664MemUsage m101 : 32|32@1+ (1,0) [0|4294967295] "" Vector__XXX
 SG_ UIS_polytopiax8664CPUUsage m102 : 32|32@1+ (1,0) [0|4294967295] "" Vector__XXX
 SG_ UIS_odincefMemUsage m103 : 32|32@1+ (1,0) [0|4294967295] "" Vector__XXX
 SG_ UIS_odincefCPUUsage m104 : 32|32@1+ (1,0) [0|4294967295] "" Vector__XXX
 SG_ UIS_odinStatusCmdResult m105 : 32|32@1+ (1,0) [0|4294967295] "" Vector__XXX
 SG_ UIS_odinStatusCmdDurationMs m106 : 32|32@1+ (1,0) [0|4294967295] "" Vector__XXX
 SG_ UIS_odinProcessState m107 : 32|32@1+ (1,0) [0|4294967295] "" Vector__XXX
 SG_ UIS_odinOrchestratorStartCount m108 : 32|32@1+ (1,0) [0|4294967295] "" Vector__XXX
 SG_ UIS_odinOrchestratorFailCount m109 : 32|32@1+ (1,0) [0|4294967295] "" Vector__XXX
 SG_ UIS_odinNetworkStartCount m110 : 32|32@1+ (1,0) [0|4294967295] "" Vector__XXX
 SG_ UIS_odinNetworkFailCount m111 : 32|32@1+ (1,0) [0|4294967295] "" Vector__XXX
 SG_ UIS_odinMemUsage m112 : 32|32@1+ (1,0) [0|4294967295] "" Vector__XXX
 SG_ UIS_odinListTasksCmdResult m113 : 32|32@1+ (1,0) [0|4294967295] "" Vector__XXX
 SG_ UIS_odinListTasksCmdDurationMs m114 : 32|32@1+ (1,0) [0|4294967295] "" Vector__XXX
 SG_ UIS_odinHrlUploadLimits m115 : 32|32@1+ (1,0) [0|4294967295] "" Vector__XXX
 SG_ UIS_odinHrlLogUploadState m116 : 32|32@1+ (1,0) [0|4294967295] "" Vector__XXX
 SG_ UIS_odinHermesConnectionState m117 : 32|32@1+ (1,0) [0|4294967295] "" Vector__XXX
 SG_ UIS_odinGatewayConnectionState m118 : 32|32@1+ (1,0) [0|4294967295] "" Vector__XXX
 SG_ UIS_odinFileSystemState m119 : 32|32@1+ (1,0) [0|4294967295] "" Vector__XXX
 SG_ UIS_odinEcuLogUploadState m120 : 32|32@1+ (1,0) [0|4294967295] "" Vector__XXX
 SG_ UIS_odinEcuLogForceTriggerUpload m121 : 32|32@1+ (1,0) [0|4294967295] "" Vector__XXX
 SG_ UIS_odinCPUUsage m122 : 32|32@1+ (1,0) [0|4294967295] "" Vector__XXX
 SG_ UIS_odinAuthFailCount m123 : 32|32@1+ (1,0) [0|4294967295] "" Vector__XXX
 SG_ UIS_odinAuthCount m124 : 32|32@1+ (1,0) [0|4294967295] "" Vector__XXX
 SG_ UIS_nvmeTemperature m125 : 32|32@1+ (1,0) [0|4294967295] "" Vector__XXX
 SG_ UIS_nvmePercentLifetimeUsed m126 : 32|32@1+ (1,0) [0|4294967295] "" Vector__XXX
 SG_ UIS_nvmeDataUnitsWritten100mb m127 : 32|32@1+ (1,0) [0|4294967295] "" Vector__XXX
 SG_ UIS_numUncorrMemErrorsECC m128 : 32|32@1+ (1,0) [0|4294967295] "" Vector__XXX
 SG_ UIS_numCorrMemErrorsECC m129 : 32|32@1+ (1,0) [0|4294967295] "" Vector__XXX
 SG_ UIS_nuanceserverMemUsage m130 : 32|32@1+ (1,0) [0|4294967295] "" Vector__XXX
 SG_ UIS_nuanceserverCPUUsage m131 : 32|32@1+ (1,0) [0|4294967295] "" Vector__XXX
 SG_ UIS_navAudioVolume m132 : 32|32@1+ (1,0) [0|4294967295] "" Vector__XXX
 SG_ UIS_muteNavVolume m133 : 32|32@1+ (1,0) [0|4294967295] "" Vector__XXX
 SG_ UIS_mounterdState m134 : 32|32@1+ (1,0) [0|4294967295] "" Vector__XXX
 SG_ UIS_mounterdMountCountTotal m135 : 32|32@1+ (1,0) [0|4294967295] "" Vector__XXX
 SG_ UIS_mounterdFrontHubDisconnected m136 : 32|32@1+ (1,0) [0|4294967295] "" Vector__XXX
 SG_ UIS_mounterdFrontHubConnected m137 : 32|32@1+ (1,0) [0|4294967295] "" Vector__XXX
 SG_ UIS_mounterdFilesystemCountFat32 m138 : 32|32@1+ (1,0) [0|4294967295] "" Vector__XXX
 SG_ UIS_mounterdFilesystemCountExt4 m139 : 32|32@1+ (1,0) [0|4294967295] "" Vector__XXX
 SG_ UIS_mounterdFilesystemCountExt3 m140 : 32|32@1+ (1,0) [0|4294967295] "" Vector__XXX
 SG_ UIS_mounterdFilesystemCountExfat m141 : 32|32@1+ (1,0) [0|4294967295] "" Vector__XXX
 SG_ UIS_mounterdEncryptionCapacityGB m142 : 32|32@1+ (1,0) [0|4294967295] "" Vector__XXX
 SG_ UIS_mounterdDeviceCount m143 : 32|32@1+ (1,0) [0|4294967295] "" Vector__XXX
 SG_ UIS_mounterdDashcamCapacityGB m144 : 32|32@1+ (1,0) [0|4294967295] "" Vector__XXX
 SG_ UIS_modemECallppAvail m145 : 32|32@1+ (1,0) [0|1] "" Vector__XXX
 SG_ UIS_modemBusyActive m146 : 32|32@1+ (1,0) [0|1] "" Vector__XXX
 SG_ UIS_mirrorGeofenceActive m147 : 32|32@1+ (1,0) [0|1] "" Vector__XXX
 SG_ UIS_mediaserveMemUsage m148 : 32|32@1+ (1,0) [0|4294967295] "" Vector__XXX
 SG_ UIS_mediaserveCPUUsage m149 : 32|32@1+ (1,0) [0|4294967295] "" Vector__XXX
 SG_ UIS_mediaPlaybackStatus m150 : 32|32@1+ (1,0) [0|4294967295] "" Vector__XXX
 SG_ UIS_mediaNeedAuthToken m151 : 32|32@1+ (1,0) [0|1] "" Vector__XXX
 SG_ UIS_mediaImageCacheSize m152 : 32|32@1+ (1,0) [0|4294967295] "" Vector__XXX
 SG_ UIS_mediaImageCacheCost m153 : 32|32@1+ (1,0) [0|4294967295] "" Vector__XXX
 SG_ UIS_limex8664MemUsage m154 : 32|32@1+ (1,0) [0|4294967295] "" Vector__XXX
 SG_ UIS_limex8664CPUUsage m155 : 32|32@1+ (1,0) [0|4294967295] "" Vector__XXX
 SG_ UIS_inSuperchargerGeofence m156 : 32|32@1+ (1,0) [0|1] "" Vector__XXX
 SG_ UIS_igpuTemperature m157 : 32|32@1+ (1,0) [0|4294967295] "" Vector__XXX
 SG_ UIS_homelinkState m158 : 32|32@1+ (1,0) [0|4294967295] "" Vector__XXX
 SG_ UIS_hermesdynamicMemUsage m159 : 32|32@1+ (1,0) [0|4294967295] "" Vector__XXX
 SG_ UIS_hermesdynamicCPUUsage m160 : 32|32@1+ (1,0) [0|4294967295] "" Vector__XXX
 SG_ UIS_hermesclientMemUsage m161 : 32|32@1+ (1,0) [0|4294967295] "" Vector__XXX
 SG_ UIS_hermesclientCPUUsage m162 : 32|32@1+ (1,0) [0|4294967295] "" Vector__XXX
 SG_ UIS_headsetPairResult m163 : 32|32@1+ (1,0) [0|4294967295] "" Vector__XXX
 SG_ UIS_headsetConnectionState m164 : 32|32@1+ (1,0) [0|4294967295] "" Vector__XXX
 SG_ UIS_gtwSocUartTxStatTimeouts m165 : 32|32@1+ (1,0) [0|4294967295] "" Vector__XXX
 SG_ UIS_gtwSocUartTxStatPackets m166 : 32|32@1+ (1,0) [0|4294967295] "" Vector__XXX
 SG_ UIS_gtwSocUartTxStatNacks m167 : 32|32@1+ (1,0) [0|4294967295] "" Vector__XXX
 SG_ UIS_gtwSocUartTxStatBadTooBig m168 : 32|32@1+ (1,0) [0|4294967295] "" Vector__XXX
 SG_ UIS_gtwSocUartTxStatAnsMismatch m169 : 32|32@1+ (1,0) [0|4294967295] "" Vector__XXX
 SG_ UIS_gtwSocUartRxStatValidPackets m170 : 32|32@1+ (1,0) [0|4294967295] "" Vector__XXX
 SG_ UIS_gtwSocUartRxStatUnhandled m171 : 32|32@1+ (1,0) [0|4294967295] "" Vector__XXX
 SG_ UIS_gtwSocUartRxStatMsgErr m172 : 32|32@1+ (1,0) [0|4294967295] "" Vector__XXX
 SG_ UIS_gtwSocUartRxStatHeartbeats m173 : 32|32@1+ (1,0) [0|4294967295] "" Vector__XXX
 SG_ UIS_gtwSocUartRxStatHandleErr m174 : 32|32@1+ (1,0) [0|4294967295] "" Vector__XXX
 SG_ UIS_gtwSocUartRxStatBadTooSmall m175 : 32|32@1+ (1,0) [0|4294967295] "" Vector__XXX
 SG_ UIS_gtwSocUartRxStatBadTooBig m176 : 32|32@1+ (1,0) [0|4294967295] "" Vector__XXX
 SG_ UIS_gtwSocUartRxStatBadChecksum m177 : 32|32@1+ (1,0) [0|4294967295] "" Vector__XXX
 SG_ UIS_gpsmanagerMemUsage m178 : 32|32@1+ (1,0) [0|4294967295] "" Vector__XXX
 SG_ UIS_gpsmanagerCPUUsage m179 : 32|32@1+ (1,0) [0|4294967295] "" Vector__XXX
 SG_ UIS_godot_TIME_PROCESS m180 : 32|32@1+ (1,0) [0|4294967295] "" Vector__XXX
 SG_ UIS_godot_TIME_FPS m181 : 32|32@1+ (1,0) [0|4294967295] "" Vector__XXX
 SG_ UIS_godot_MEMORY_STATIC m182 : 32|32@1+ (1,0) [0|4294967295] "" Vector__XXX
 SG_ UIS_godot_MEMORY_DYNAMIC m183 : 32|32@1+ (1,0) [0|4294967295] "" Vector__XXX
 SG_ UIS_godotMemUsage m184 : 32|32@1+ (1,0) [0|4294967295] "" Vector__XXX
 SG_ UIS_godotCPUUsage m185 : 32|32@1+ (1,0) [0|4294967295] "" Vector__XXX
 SG_ UIS_firmwareReleaseScope m186 : 32|32@1+ (1,0) [0|4294967295] "" Vector__XXX
 SG_ UIS_featureSuperchargingEnabled m187 : 32|32@1+ (1,0) [0|4294967295] "" Vector__XXX
 SG_ UIS_estimatedOccupancyCount m188 : 32|32@1+ (1,0) [0|4294967295] "" Vector__XXX
 SG_ UIS_embeddedGameState m189 : 32|32@1+ (1,0) [0|4294967295] "" Vector__XXX
 SG_ UIS_embeddedGameName m190 : 32|32@1+ (1,0) [0|4294967295] "" Vector__XXX
 SG_ UIS_dumTclipUploadState m191 : 32|32@1+ (1,0) [0|4294967295] "" Vector__XXX
 SG_ UIS_dumTclipUploadActive m192 : 32|32@1+ (1,0) [0|4294967295] "" Vector__XXX
 SG_ UIS_dumTclipTransferCount m193 : 32|32@1+ (1,0) [0|4294967295] "" Vector__XXX
 SG_ UIS_dumTclipSuccessfulUploadCoun m194 : 32|32@1+ (1,0) [0|4294967295] "" Vector__XXX
 SG_ UIS_dumTclipClipCount m195 : 32|32@1+ (1,0) [0|4294967295] "" Vector__XXX
 SG_ UIS_dmRearTouchDeviceExists m196 : 32|32@1+ (1,0) [0|4294967295] "" Vector__XXX
 SG_ UIS_dmRearPowerState m197 : 32|32@1+ (1,0) [0|1] "" Vector__XXX
 SG_ UIS_dmRearLinkCheckOk m198 : 32|32@1+ (1,0) [0|1] "" Vector__XXX
 SG_ UIS_dmRearEnabled m199 : 32|32@1+ (1,0) [0|4294967295] "" Vector__XXX
 SG_ UIS_dmRearConnected m200 : 32|32@1+ (1,0) [0|4294967295] "" Vector__XXX
 SG_ UIS_dmRearBacklightPowerLevel m201 : 32|32@1+ (1,0) [0|4294967295] "" Vector__XXX
 SG_ UIS_dmRearBacklightNits m202 : 32|32@1+ (1,0) [0|4294967295] "" Vector__XXX
 SG_ UIS_dmRearBacklightFault m203 : 32|32@1+ (1,0) [0|4294967295] "" Vector__XXX
 SG_ UIS_dmRearBacklightDutyCycle m204 : 32|32@1+ (1,0) [0|4294967295] "" Vector__XXX
 SG_ UIS_dmRearBacklightDevExists m205 : 32|32@1+ (1,0) [0|1] "" Vector__XXX
 SG_ UIS_dmRearAsilStatusMsb m206 : 32|32@1+ (1,0) [0|4294967295] "" Vector__XXX
 SG_ UIS_dmRearAsilStatusLsb m207 : 32|32@1+ (1,0) [0|4294967295] "" Vector__XXX
 SG_ UIS_dmIcuTouchIrqCount m208 : 32|32@1+ (1,0) [0|4294967295] "" Vector__XXX
 SG_ UIS_dmIcuPowerState m209 : 32|32@1+ (1,0) [0|1] "" Vector__XXX
 SG_ UIS_dmIcuLinkCheckOk m210 : 32|32@1+ (1,0) [0|1] "" Vector__XXX
 SG_ UIS_dmIcuEnabled m211 : 32|32@1+ (1,0) [0|4294967295] "" Vector__XXX
 SG_ UIS_dmIcuConnected m212 : 32|32@1+ (1,0) [0|4294967295] "" Vector__XXX
 SG_ UIS_dmIcuBacklightPowerLevel m213 : 32|32@1+ (1,0) [0|4294967295] "" Vector__XXX
 SG_ UIS_dmIcuBacklightNits m214 : 32|32@1+ (1,0) [0|4294967295] "" Vector__XXX
 SG_ UIS_dmIcuBacklightFault m215 : 32|32@1+ (1,0) [0|4294967295] "" Vector__XXX
 SG_ UIS_dmIcuBacklightDutyCycle m216 : 32|32@1+ (1,0) [0|4294967295] "" Vector__XXX
 SG_ UIS_dmIcuBacklightDevExists m217 : 32|32@1+ (1,0) [0|1] "" Vector__XXX
 SG_ UIS_dmIcuAsilShortFlag m218 : 32|32@1+ (1,0) [0|4294967295] "" Vector__XXX
 SG_ UIS_dmIcuAsilResumeFlag m219 : 32|32@1+ (1,0) [0|4294967295] "" Vector__XXX
 SG_ UIS_dmIcuAsilOpenFlag m220 : 32|32@1+ (1,0) [0|4294967295] "" Vector__XXX
 SG_ UIS_dmIcuAsilFirmwareStatus m221 : 32|32@1+ (1,0) [0|4294967295] "" Vector__XXX
 SG_ UIS_dmGatewayLinkWedged m222 : 32|32@1+ (1,0) [0|4294967295] "" Vector__XXX
 SG_ UIS_dmCenterTouchIrqCount m223 : 32|32@1+ (1,0) [0|4294967295] "" Vector__XXX
 SG_ UIS_dmCenterTouchDeviceExists m224 : 32|32@1+ (1,0) [0|4294967295] "" Vector__XXX
 SG_ UIS_dmCenterSOsdVideoCrcData m225 : 32|32@1+ (1,0) [0|4294967295] "" Vector__XXX
 SG_ UIS_dmCenterSOsdExactCrcCheck m226 : 32|32@1+ (1,0) [0|4294967295] "" Vector__XXX
 SG_ UIS_dmCenterPowerState m227 : 32|32@1+ (1,0) [0|1] "" Vector__XXX
 SG_ UIS_dmCenterOsdDisplayedState m228 : 32|32@1+ (1,0) [0|1] "" Vector__XXX
 SG_ UIS_dmCenterOsdDayNightState m229 : 32|32@1+ (1,0) [0|4294967295] "" Vector__XXX
 SG_ UIS_dmCenterModeSettingStatus m230 : 32|32@1+ (1,0) [0|4294967295] "" Vector__XXX
 SG_ UIS_dmCenterMOsdVideoCrcData m231 : 32|32@1+ (1,0) [0|4294967295] "" Vector__XXX
 SG_ UIS_dmCenterMOsdExactCrcCheck m232 : 32|32@1+ (1,0) [0|4294967295] "" Vector__XXX
 SG_ UIS_dmCenterLinkCheckOk m233 : 32|32@1+ (1,0) [0|1] "" Vector__XXX
 SG_ UIS_dmCenterEnabled m234 : 32|32@1+ (1,0) [0|4294967295] "" Vector__XXX
 SG_ UIS_dmCenterConnected m235 : 32|32@1+ (1,0) [0|4294967295] "" Vector__XXX
 SG_ UIS_dmCenterBacklightPowerLevel m236 : 32|32@1+ (1,0) [0|4294967295] "" Vector__XXX
 SG_ UIS_dmCenterBacklightNits m237 : 32|32@1+ (1,0) [0|4294967295] "" Vector__XXX
 SG_ UIS_dmCenterBacklightFault m238 : 32|32@1+ (1,0) [0|4294967295] "" Vector__XXX
 SG_ UIS_dmCenterBacklightDutyCycle m239 : 32|32@1+ (1,0) [0|4294967295] "" Vector__XXX
 SG_ UIS_dmCenterBacklightDevExists m240 : 32|32@1+ (1,0) [0|1] "" Vector__XXX
 SG_ UIS_dmCenterAsilShortFlag m241 : 32|32@1+ (1,0) [0|4294967295] "" Vector__XXX
 SG_ UIS_dmCenterAsilResumeFlag m242 : 32|32@1+ (1,0) [0|4294967295] "" Vector__XXX
 SG_ UIS_dmCenterAsilOpenFlag m243 : 32|32@1+ (1,0) [0|4294967295] "" Vector__XXX
 SG_ UIS_dmCenterAsilFirmwareStatus m244 : 32|32@1+ (1,0) [0|4294967295] "" Vector__XXX
 SG_ UIS_dgpuTemperature m245 : 32|32@1+ (1,0) [0|4294967295] "" Vector__XXX
 SG_ UIS_developerMode m246 : 32|32@1+ (1,0) [0|4294967295] "" Vector__XXX
 SG_ UIS_dashcamviewerMemUsage m247 : 32|32@1+ (1,0) [0|4294967295] "" Vector__XXX
 SG_ UIS_dashcamviewerCPUUsage m248 : 32|32@1+ (1,0) [0|4294967295] "" Vector__XXX
 SG_ UIS_dashcamTransferTimeMs m249 : 32|32@1+ (1,0) [0|4294967295] "" Vector__XXX
 SG_ UIS_dashcamTransferSizeMB m250 : 32|32@1+ (1,0) [0|4294967295] "" Vector__XXX
 SG_ UIS_dashcamTransferRateMBps m251 : 32|32@1+ (1,0) [0|4294967295] "" Vector__XXX
 SG_ UIS_dashcamTransferFileCount m252 : 32|32@1+ (1,0) [0|4294967295] "" Vector__XXX
 SG_ UIS_dashcamTransferCount m253 : 32|32@1+ (1,0) [0|4294967295] "" Vector__XXX
 SG_ UIS_dashcamStorageState m254 : 32|32@1+ (1,0) [0|4294967295] "" Vector__XXX
 SG_ UIS_dashcamStorageSentryMB m255 : 32|32@1+ (1,0) [0|4294967295] "" Vector__XXX
 SG_ UIS_dashcamStorageSavedMB m256 : 32|32@1+ (1,0) [0|4294967295] "" Vector__XXX
 SG_ UIS_dashcamStorageRecentMB m257 : 32|32@1+ (1,0) [0|4294967295] "" Vector__XXX
 SG_ UIS_dashcamStorageAvailableMB m258 : 32|32@1+ (1,0) [0|4294967295] "" Vector__XXX
 SG_ UIS_dashcamState m259 : 32|32@1+ (1,0) [0|4294967295] "" Vector__XXX
 SG_ UIS_dashcamSavedToSentryCount m260 : 32|32@1+ (1,0) [0|4294967295] "" Vector__XXX
 SG_ UIS_dashcamSavedToSavedCount m261 : 32|32@1+ (1,0) [0|4294967295] "" Vector__XXX
 SG_ UIS_dashcamSavedToOnboardCount m262 : 32|32@1+ (1,0) [0|4294967295] "" Vector__XXX
 SG_ UIS_dashcamOnboardTransferCount m263 : 32|32@1+ (1,0) [0|4294967295] "" Vector__XXX
 SG_ UIS_dashcamOnboardSavePressCount m264 : 32|32@1+ (1,0) [0|4294967295] "" Vector__XXX
 SG_ UIS_dashcamOnboardMB m265 : 32|32@1+ (1,0) [0|4294967295] "" Vector__XXX
 SG_ UIS_dashcamOnboardAvailableMB m266 : 32|32@1+ (1,0) [0|4294967295] "" Vector__XXX
 SG_ UIS_cpuTemperature m267 : 32|32@1+ (1,0) [0|4294967295] "" Vector__XXX
 SG_ UIS_compositorRenderMinRenderTim m268 : 32|32@1+ (1,0) [0|4294967295] "" Vector__XXX
 SG_ UIS_compositorRenderMinFrameTime m269 : 32|32@1+ (1,0) [0|4294967295] "" Vector__XXX
 SG_ UIS_compositorRenderMaxRenderTim m270 : 32|32@1+ (1,0) [0|4294967295] "" Vector__XXX
 SG_ UIS_compositorRenderMaxFrameTime m271 : 32|32@1+ (1,0) [0|4294967295] "" Vector__XXX
 SG_ UIS_compositorRenderGpuPercentag m272 : 32|32@1+ (1,0) [0|4294967295] "" Vector__XXX
 SG_ UIS_compositorRenderFrameRate m273 : 32|32@1+ (1,0) [0|4294967295] "" Vector__XXX
 SG_ UIS_compositorRenderFrameCount m274 : 32|32@1+ (1,0) [0|4294967295] "" Vector__XXX
 SG_ UIS_compositorRenderAvgRenderTim m275 : 32|32@1+ (1,0) [0|4294967295] "" Vector__XXX
 SG_ UIS_compositorFrameMonitorState m276 : 32|32@1+ (1,0) [0|4294967295] "" Vector__XXX
 SG_ UIS_cobaltlinuxMemUsage m277 : 32|32@1+ (1,0) [0|4294967295] "" Vector__XXX
 SG_ UIS_cobaltlinuxCPUUsage m278 : 32|32@1+ (1,0) [0|4294967295] "" Vector__XXX
 SG_ UIS_clusterMemUsage m279 : 32|32@1+ (1,0) [0|4294967295] "" Vector__XXX
 SG_ UIS_clusterMeanFPS m280 : 32|32@1+ (1,0) [0|4294967295] "" Vector__XXX
 SG_ UIS_clusterMaxFrametime m281 : 32|32@1+ (1,0) [0|4294967295] "" Vector__XXX
 SG_ UIS_clusterFramesOver200Ms m282 : 32|32@1+ (1,0) [0|4294967295] "" Vector__XXX
 SG_ UIS_clusterFramesOver100Ms m283 : 32|32@1+ (1,0) [0|4294967295] "" Vector__XXX
 SG_ UIS_clusterDisplayState m284 : 32|32@1+ (1,0) [0|4294967295] "" Vector__XXX
 SG_ UIS_clusterCPUUsage m285 : 32|32@1+ (1,0) [0|4294967295] "" Vector__XXX
 SG_ UIS_chromiumadapterMemUsage m286 : 32|32@1+ (1,0) [0|4294967295] "" Vector__XXX
 SG_ UIS_chromiumadapterCPUUsage m287 : 32|32@1+ (1,0) [0|4294967295] "" Vector__XXX
 SG_ UIS_chargeOnSolarNoChargeReason m288 : 32|32@1+ (1,0) [0|4294967295] "" Vector__XXX
 SG_ UIS_ceruleanx8664MemUsage m289 : 32|32@1+ (1,0) [0|4294967295] "" Vector__XXX
 SG_ UIS_ceruleanx8664CPUUsage m290 : 32|32@1+ (1,0) [0|4294967295] "" Vector__XXX
 SG_ UIS_centerDisplayState m291 : 32|32@1+ (1,0) [0|4294967295] "" Vector__XXX
 SG_ UIS_centerDisplayEvent m292 : 32|32@1+ (1,0) [0|4294967295] "" Vector__XXX
 SG_ UIS_centerDispAsilB_msb m293 : 32|32@1+ (1,0) [0|4294967295] "" Vector__XXX
 SG_ UIS_centerDispAsilB_lsb m294 : 32|32@1+ (1,0) [0|4294967295] "" Vector__XXX
 SG_ UIS_centerDispAsilA_msb m295 : 32|32@1+ (1,0) [0|4294967295] "" Vector__XXX
 SG_ UIS_centerDispAsilA_lsb m296 : 32|32@1+ (1,0) [0|4294967295] "" Vector__XXX
 SG_ UIS_cellularLinkManagerState m297 : 32|32@1+ (1,0) [0|4294967295] "" Vector__XXX
 SG_ UIS_carAssistState m298 : 32|32@1+ (1,0) [0|4294967295] "" Vector__XXX
 SG_ UIS_carAssistSessionCount m299 : 32|32@1+ (1,0) [0|4294967295] "" Vector__XXX
 SG_ UIS_carAssistErrorCode m300 : 32|32@1+ (1,0) [0|4294967295] "" Vector__XXX
 SG_ UIS_cameraRRepeaterStreamMissing m301 : 32|32@1+ (1,0) [0|1] "" Vector__XXX
 SG_ UIS_cameraRRepeaterStream m302 : 32|32@1+ (1,0) [0|4294967295] "" Vector__XXX
 SG_ UIS_cameraRRepeaterPopup m303 : 32|32@1+ (1,0) [0|1] "" Vector__XXX
 SG_ UIS_cameraRRepeaterPipeline m304 : 32|32@1+ (1,0) [0|4294967295] "" Vector__XXX
 SG_ UIS_cameraRRepeaterMaxFrametime m305 : 32|32@1+ (1,0) [0|4294967295] "" Vector__XXX
 SG_ UIS_cameraRRepeaterLateFrames m306 : 32|32@1+ (1,0) [0|4294967295] "" Vector__XXX
 SG_ UIS_cameraRRepeaterFramerate m307 : 32|32@1+ (1,0) [0|4294967295] "" Vector__XXX
 SG_ UIS_cameraLRepeaterStreamMissing m308 : 32|32@1+ (1,0) [0|1] "" Vector__XXX
 SG_ UIS_cameraLRepeaterStream m309 : 32|32@1+ (1,0) [0|4294967295] "" Vector__XXX
 SG_ UIS_cameraLRepeaterPopup m310 : 32|32@1+ (1,0) [0|1] "" Vector__XXX
 SG_ UIS_cameraLRepeaterPipeline m311 : 32|32@1+ (1,0) [0|4294967295] "" Vector__XXX
 SG_ UIS_cameraLRepeaterMaxFrametime m312 : 32|32@1+ (1,0) [0|4294967295] "" Vector__XXX
 SG_ UIS_cameraLRepeaterLateFrames m313 : 32|32@1+ (1,0) [0|4294967295] "" Vector__XXX
 SG_ UIS_cameraLRepeaterFramerate m314 : 32|32@1+ (1,0) [0|4294967295] "" Vector__XXX
 SG_ UIS_cameraFrontStreamMissing m315 : 32|32@1+ (1,0) [0|4294967295] "" Vector__XXX
 SG_ UIS_cameraFrontStream m316 : 32|32@1+ (1,0) [0|4294967295] "" Vector__XXX
 SG_ UIS_cameraFrontPopup m317 : 32|32@1+ (1,0) [0|4294967295] "" Vector__XXX
 SG_ UIS_cameraFrontPipeline m318 : 32|32@1+ (1,0) [0|4294967295] "" Vector__XXX
 SG_ UIS_cameraBackupStreamQuality m319 : 32|32@1+ (1,0) [0|4294967295] "" Vector__XXX
 SG_ UIS_cameraBackupStreamMissing m320 : 32|32@1+ (1,0) [0|1] "" Vector__XXX
 SG_ UIS_cameraBackupStream m321 : 32|32@1+ (1,0) [0|4294967295] "" Vector__XXX
 SG_ UIS_cameraBackupPopup m322 : 32|32@1+ (1,0) [0|1] "" Vector__XXX
 SG_ UIS_cameraBackupPipeline m323 : 32|32@1+ (1,0) [0|4294967295] "" Vector__XXX
 SG_ UIS_cameraBackupMaxFrametime m324 : 32|32@1+ (1,0) [0|4294967295] "" Vector__XXX
 SG_ UIS_cameraBackupLateFrames m325 : 32|32@1+ (1,0) [0|4294967295] "" Vector__XXX
 SG_ UIS_cameraBackupFramerate m326 : 32|32@1+ (1,0) [0|4294967295] "" Vector__XXX
 SG_ UIS_camBackupDecodeMinFrametime m327 : 32|32@1+ (1,0) [0|4294967295] "" Vector__XXX
 SG_ UIS_camBackupDecodeMaxFrametime m328 : 32|32@1+ (1,0) [0|4294967295] "" Vector__XXX
 SG_ UIS_camBackupDecodeFramecount m329 : 32|32@1+ (1,0) [0|4294967295] "" Vector__XXX
 SG_ UIS_camBackupDecodeAvgFrametime m330 : 32|32@1+ (1,0) [0|4294967295] "" Vector__XXX
 SG_ UIS_bootCount m331 : 32|32@1+ (1,0) [0|4294967295] "" Vector__XXX
 SG_ UIS_boardTemperature m332 : 32|32@1+ (1,0) [0|4294967295] "" Vector__XXX
 SG_ UIS_bluetoothStackState m333 : 32|32@1+ (1,0) [0|4294967295] "" Vector__XXX
 SG_ UIS_bluetoothStackRearState m334 : 32|32@1+ (1,0) [0|4294967295] "" Vector__XXX
 SG_ UIS_bluetoothPairResult m335 : 32|32@1+ (1,0) [0|4294967295] "" Vector__XXX
 SG_ UIS_bluetoothMemUsage m336 : 32|32@1+ (1,0) [0|4294967295] "" Vector__XXX
 SG_ UIS_bluetoothConnectionState m337 : 32|32@1+ (1,0) [0|4294967295] "" Vector__XXX
 SG_ UIS_bluetoothCPUUsage m338 : 32|32@1+ (1,0) [0|4294967295] "" Vector__XXX
 SG_ UIS_bluetoothAutoConnectionState m339 : 32|32@1+ (1,0) [0|4294967295] "" Vector__XXX
 SG_ UIS_bifrostOdinEngineUp m340 : 32|32@1+ (1,0) [0|4294967295] "" Vector__XXX
 SG_ UIS_bifrostOdinEngineRequests m341 : 32|32@1+ (1,0) [0|4294967295] "" Vector__XXX
 SG_ UIS_bifrostMemUsage m342 : 32|32@1+ (1,0) [0|4294967295] "" Vector__XXX
 SG_ UIS_bifrostCPUUsage m343 : 32|32@1+ (1,0) [0|4294967295] "" Vector__XXX
 SG_ UIS_backlightUserRequest m344 : 32|32@1+ (1,0) [0|4294967295] "" Vector__XXX
 SG_ UIS_audioVolumeLevel m345 : 32|32@1+ (1,0) [0|4294967295] "" Vector__XXX
 SG_ UIS_audioType m346 : 32|32@1+ (1,0) [0|4294967295] "" Vector__XXX
 SG_ UIS_audioState m347 : 32|32@1+ (1,0) [0|4294967295] "" Vector__XXX
 SG_ UIS_audioSource m348 : 32|32@1+ (1,0) [0|4294967295] "" Vector__XXX
 SG_ UIS_audioPWSGain m349 : 32|32@1+ (1,0) [0|4294967295] "" Vector__XXX
 SG_ UIS_audioMediaPlaying m350 : 32|32@1+ (1,0) [0|4294967295] "" Vector__XXX
 SG_ UIS_audioMediaBrowsing m351 : 32|32@1+ (1,0) [0|4294967295] "" Vector__XXX
 SG_ UIS_audioA2BRediscoveryCount m352 : 32|32@1+ (1,0) [0|4294967295] "" Vector__XXX
 SG_ UIS_amdSocPkgPower m353 : 32|32@1+ (1,0) [0|4294967295] "" Vector__XXX
 SG_ UIS_activeAppView m354 : 32|32@1+ (1,0) [0|4294967295] "" Vector__XXX

BO_TX_BU_ 881 : RCM;
BO_TX_BU_ 1471 : RCU;
BO_TX_BU_ 998 : RCU;
BO_TX_BU_ 831 : RCU;
BO_TX_BU_ 1410 : TCU;
BO_TX_BU_ 1472 : TCU;
BO_TX_BU_ 1409 : TCU;
BO_TX_BU_ 1408 : TCU;
BO_TX_BU_ 1056 : UIS;
CM_ SG_ 1297 RCM_a104_eventDriverBrakeApply "Restraint control module: a104 event driver brake apply; raw 3 = signal not available (SNA)";
CM_ SG_ 1297 RCM_a104_eventAccelPedalPos "Restraint control module: a104 event accel pedal pos; raw 255 = signal not available (SNA)";
CM_ SG_ 1297 RCM_a105_eventArmStatus "Restraint control module: a105 event arm status";
CM_ SG_ 1297 RCM_a105_eventFactoryMode "Restraint control module: a105 event factory mode";
CM_ SG_ 1297 RCM_a105_eventDiagEnabled "Restraint control module: a105 event diag enabled";
CM_ SG_ 1297 RCM_a105_eventDriveOrientation "Restraint control module: a105 event drive orientation";
CM_ SG_ 1297 RCM_a105_imuLongAOffCompPosLife "Restraint control module: a105 imu long a off comp pos life";
CM_ SG_ 1297 RCM_a105_imuLongAOffCompNegLife "Restraint control module: a105 imu long a off comp neg life";
CM_ SG_ 1297 RCM_a105_imuLongAOffCompPosFLDC "Restraint control module: a105 imu long a off comp pos FLDC";
CM_ SG_ 1297 RCM_a105_imuLongAOffCompNegFLDC "Restraint control module: a105 imu long a off comp neg FLDC";
CM_ SG_ 1297 RCM_a105_imuLongAOffCompPosSLDC "Restraint control module: a105 imu long a off comp pos SLDC";
CM_ SG_ 1297 RCM_a105_imuLongAOffCompNegSLDC "Restraint control module: a105 imu long a off comp neg SLDC";
CM_ SG_ 1297 RCM_a105_eventIDFsignal "Restraint control module: a105 event ID fsignal";
CM_ SG_ 1297 RCM_a105_eventFrontLeftSeatbelt "Restraint control module: a105 event front left seatbelt";
CM_ SG_ 1297 RCM_a105_eventFrontRightSeatbelt "Restraint control module: a105 event front right seatbelt";
CM_ SG_ 1297 RCM_a105_eventVehicleSpeed "Restraint control module: a105 event vehicle speed";
CM_ SG_ 1297 RCM_a105_eventSteeringAngle "Restraint control module: a105 event steering angle";
CM_ SG_ 1297 RCM_a105_eventDriverBrakeApply "Restraint control module: a105 event driver brake apply; raw 3 = signal not available (SNA)";
CM_ SG_ 1297 RCM_a105_eventAccelPedalPos "Restraint control module: a105 event accel pedal pos; raw 255 = signal not available (SNA)";
CM_ SG_ 1297 RCM_a106_eventArmStatus "Restraint control module: a106 event arm status";
CM_ SG_ 1297 RCM_a106_eventFactoryMode "Restraint control module: a106 event factory mode";
CM_ SG_ 1297 RCM_a106_eventDiagEnabled "Restraint control module: a106 event diag enabled";
CM_ SG_ 1297 RCM_a106_eventDriveOrientation "Restraint control module: a106 event drive orientation";
CM_ SG_ 1297 RCM_a106_imuLatAcOffCompPosLife "Restraint control module: a106 imu lat ac off comp pos life";
CM_ SG_ 1297 RCM_a106_imuLatAcOffCompNegLife "Restraint control module: a106 imu lat ac off comp neg life";
CM_ SG_ 1297 RCM_a106_imuLatAcOffCompPosFLDC "Restraint control module: a106 imu lat ac off comp pos FLDC";
CM_ SG_ 1297 RCM_a106_imuLatAcOffCompNegFLDC "Restraint control module: a106 imu lat ac off comp neg FLDC";
CM_ SG_ 1297 RCM_a106_imuLatAcOffCompPosSLDC "Restraint control module: a106 imu lat ac off comp pos SLDC";
CM_ SG_ 1297 RCM_a106_imuLatAcOffCompNegSLDC "Restraint control module: a106 imu lat ac off comp neg SLDC";
CM_ SG_ 1297 RCM_a106_eventIDFsignal "Restraint control module: a106 event ID fsignal";
CM_ SG_ 1297 RCM_a106_eventFrontLeftSeatbelt "Restraint control module: a106 event front left seatbelt";
CM_ SG_ 1297 RCM_a106_eventFrontRightSeatbelt "Restraint control module: a106 event front right seatbelt";
CM_ SG_ 1297 RCM_a106_eventVehicleSpeed "Restraint control module: a106 event vehicle speed";
CM_ SG_ 1297 RCM_a106_eventSteeringAngle "Restraint control module: a106 event steering angle";
CM_ SG_ 1297 RCM_a106_eventDriverBrakeApply "Restraint control module: a106 event driver brake apply; raw 3 = signal not available (SNA)";
CM_ SG_ 1297 RCM_a106_eventAccelPedalPos "Restraint control module: a106 event accel pedal pos; raw 255 = signal not available (SNA)";
CM_ SG_ 1297 RCM_a107_eventArmStatus "Restraint control module: a107 event arm status";
CM_ SG_ 1297 RCM_a107_eventFactoryMode "Restraint control module: a107 event factory mode";
CM_ SG_ 1297 RCM_a107_eventDiagEnabled "Restraint control module: a107 event diag enabled";
CM_ SG_ 1297 RCM_a107_eventDriveOrientation "Restraint control module: a107 event drive orientation";
CM_ SG_ 1297 RCM_a107_imuVertAOffCompPosLife "Restraint control module: a107 imu vert a off comp pos life";
CM_ SG_ 1297 RCM_a107_imuVertAOffCompNegLife "Restraint control module: a107 imu vert a off comp neg life";
CM_ SG_ 1297 RCM_a107_imuVertAOffCompPosFLDC "Restraint control module: a107 imu vert a off comp pos FLDC";
CM_ SG_ 1297 RCM_a107_imuVertAOffCompNegFLDC "Restraint control module: a107 imu vert a off comp neg FLDC";
CM_ SG_ 1297 RCM_a107_imuVertAOffCompPosSLDC "Restraint control module: a107 imu vert a off comp pos SLDC";
CM_ SG_ 1297 RCM_a107_imuVertAOffCompNegSLDC "Restraint control module: a107 imu vert a off comp neg SLDC";
CM_ SG_ 1297 RCM_a107_eventIDFsignal "Restraint control module: a107 event ID fsignal";
CM_ SG_ 1297 RCM_a107_eventFrontLeftSeatbelt "Restraint control module: a107 event front left seatbelt";
CM_ SG_ 1297 RCM_a107_eventFrontRightSeatbelt "Restraint control module: a107 event front right seatbelt";
CM_ SG_ 1297 RCM_a107_eventVehicleSpeed "Restraint control module: a107 event vehicle speed";
CM_ SG_ 1297 RCM_a107_eventSteeringAngle "Restraint control module: a107 event steering angle";
CM_ SG_ 1297 RCM_a107_eventDriverBrakeApply "Restraint control module: a107 event driver brake apply; raw 3 = signal not available (SNA)";
CM_ SG_ 1297 RCM_a107_eventAccelPedalPos "Restraint control module: a107 event accel pedal pos; raw 255 = signal not available (SNA)";
CM_ SG_ 1297 RCM_a108_eventArmStatus "Restraint control module: a108 event arm status";
CM_ SG_ 1297 RCM_a108_eventFactoryMode "Restraint control module: a108 event factory mode";
CM_ SG_ 1297 RCM_a108_eventDiagEnabled "Restraint control module: a108 event diag enabled";
CM_ SG_ 1297 RCM_a108_eventDriveOrientation "Restraint control module: a108 event drive orientation";
CM_ SG_ 1297 RCM_a108_crashAlgoWakeupSig "Restraint control module: a108 crash algo wakeup sig";
CM_ SG_ 1297 RCM_a108_eventIDFsignal "Restraint control module: a108 event ID fsignal";
CM_ SG_ 1297 RCM_a108_eventFrontLeftSeatbelt "Restraint control module: a108 event front left seatbelt";
CM_ SG_ 1297 RCM_a108_eventFrontRightSeatbelt "Restraint control module: a108 event front right seatbelt";
CM_ SG_ 1297 RCM_a108_eventVehicleSpeed "Restraint control module: a108 event vehicle speed";
CM_ SG_ 1297 RCM_a108_eventSteeringAngle "Restraint control module: a108 event steering angle";
CM_ SG_ 1297 RCM_a108_eventDriverBrakeApply "Restraint control module: a108 event driver brake apply; raw 3 = signal not available (SNA)";
CM_ SG_ 1297 RCM_a108_eventAccelPedalPos "Restraint control module: a108 event accel pedal pos; raw 255 = signal not available (SNA)";
CM_ SG_ 1297 RCM_a109_eventArmStatus "Restraint control module: a109 event arm status";
CM_ SG_ 1297 RCM_a109_eventFactoryMode "Restraint control module: a109 event factory mode";
CM_ SG_ 1297 RCM_a109_eventDiagEnabled "Restraint control module: a109 event diag enabled";
CM_ SG_ 1297 RCM_a109_eventDriveOrientation "Restraint control module: a109 event drive orientation";
CM_ SG_ 1297 RCM_a109_immunityThrsholdCrossed "Restraint control module: a109 immunity thrshold crossed";
CM_ SG_ 1297 RCM_a109_eventIDFsignal "Restraint control module: a109 event ID fsignal";
CM_ SG_ 1297 RCM_a109_eventFrontLeftSeatbelt "Restraint control module: a109 event front left seatbelt";
CM_ SG_ 1297 RCM_a109_eventFrontRightSeatbelt "Restraint control module: a109 event front right seatbelt";
CM_ SG_ 1297 RCM_a109_eventVehicleSpeed "Restraint control module: a109 event vehicle speed";
CM_ SG_ 1297 RCM_a109_eventSteeringAngle "Restraint control module: a109 event steering angle";
CM_ SG_ 1297 RCM_a109_eventDriverBrakeApply "Restraint control module: a109 event driver brake apply; raw 3 = signal not available (SNA)";
CM_ SG_ 1297 RCM_a109_eventAccelPedalPos "Restraint control module: a109 event accel pedal pos; raw 255 = signal not available (SNA)";
CM_ SG_ 1297 RCM_a110_eventArmStatus "Restraint control module: a110 event arm status";
CM_ SG_ 1297 RCM_a110_eventFactoryMode "Restraint control module: a110 event factory mode";
CM_ SG_ 1297 RCM_a110_eventDiagEnabled "Restraint control module: a110 event diag enabled";
CM_ SG_ 1297 RCM_a110_eventDriveOrientation "Restraint control module: a110 event drive orientation";
CM_ SG_ 1297 RCM_a110_inFactoryMode "Restraint control module: a110 in factory mode";
CM_ SG_ 1297 RCM_a110_eventIDFsignal "Restraint control module: a110 event ID fsignal";
CM_ SG_ 1297 RCM_a110_eventFrontLeftSeatbelt "Restraint control module: a110 event front left seatbelt";
CM_ SG_ 1297 RCM_a110_eventFrontRightSeatbelt "Restraint control module: a110 event front right seatbelt";
CM_ SG_ 1297 RCM_a110_eventVehicleSpeed "Restraint control module: a110 event vehicle speed";
CM_ SG_ 1297 RCM_a110_eventSteeringAngle "Restraint control module: a110 event steering angle";
CM_ SG_ 1297 RCM_a110_eventDriverBrakeApply "Restraint control module: a110 event driver brake apply; raw 3 = signal not available (SNA)";
CM_ SG_ 1297 RCM_a110_eventAccelPedalPos "Restraint control module: a110 event accel pedal pos; raw 255 = signal not available (SNA)";
CM_ SG_ 1297 RCM_a112_eventArmStatus "Restraint control module: a112 event arm status";
CM_ SG_ 1297 RCM_a112_eventFactoryMode "Restraint control module: a112 event factory mode";
CM_ SG_ 1297 RCM_a112_eventDiagEnabled "Restraint control module: a112 event diag enabled";
CM_ SG_ 1297 RCM_a112_eventDriveOrientation "Restraint control module: a112 event drive orientation";
CM_ SG_ 1297 RCM_a112_imuYawR8SnsrMonitTmp "Restraint control module: a112 imu yaw R8 snsr monit tmp";
CM_ SG_ 1297 RCM_a112_imuYawR8SnsrMonitPerm "Restraint control module: a112 imu yaw R8 snsr monit perm";
CM_ SG_ 1297 RCM_a112_imuYawR8ChnlMonitTmp "Restraint control module: a112 imu yaw R8 chnl monit tmp";
CM_ SG_ 1297 RCM_a112_imuYawR8ChnlMonitPerm "Restraint control module: a112 imu yaw R8 chnl monit perm";
CM_ SG_ 1297 RCM_a112_eventIDFsignal "Restraint control module: a112 event ID fsignal";
CM_ SG_ 1297 RCM_a112_eventFrontLeftSeatbelt "Restraint control module: a112 event front left seatbelt";
CM_ SG_ 1297 RCM_a112_eventFrontRightSeatbelt "Restraint control module: a112 event front right seatbelt";
CM_ SG_ 1297 RCM_a112_eventVehicleSpeed "Restraint control module: a112 event vehicle speed";
CM_ SG_ 1297 RCM_a112_eventSteeringAngle "Restraint control module: a112 event steering angle";
CM_ SG_ 1297 RCM_a112_eventDriverBrakeApply "Restraint control module: a112 event driver brake apply; raw 3 = signal not available (SNA)";
CM_ SG_ 1297 RCM_a112_eventAccelPedalPos "Restraint control module: a112 event accel pedal pos; raw 255 = signal not available (SNA)";
CM_ SG_ 1297 RCM_a113_eventArmStatus "Restraint control module: a113 event arm status";
CM_ SG_ 1297 RCM_a113_eventFactoryMode "Restraint control module: a113 event factory mode";
CM_ SG_ 1297 RCM_a113_eventDiagEnabled "Restraint control module: a113 event diag enabled";
CM_ SG_ 1297 RCM_a113_eventDriveOrientation "Restraint control module: a113 event drive orientation";
CM_ SG_ 1297 RCM_a113_imuPitchR8SnsrMonitTmp "Restraint control module: a113 imu pitch R8 snsr monit tmp";
CM_ SG_ 1297 RCM_a113_imuPitchR8SnsrMonitPerm "Restraint control module: a113 imu pitch R8 snsr monit perm";
CM_ SG_ 1297 RCM_a113_imuPitchR8ChnlMonitTmp "Restraint control module: a113 imu pitch R8 chnl monit tmp";
CM_ SG_ 1297 RCM_a113_imuPitchR8ChnlMonitPerm "Restraint control module: a113 imu pitch R8 chnl monit perm";
CM_ SG_ 1297 RCM_a113_eventIDFsignal "Restraint control module: a113 event ID fsignal";
CM_ SG_ 1297 RCM_a113_eventFrontLeftSeatbelt "Restraint control module: a113 event front left seatbelt";
CM_ SG_ 1297 RCM_a113_eventFrontRightSeatbelt "Restraint control module: a113 event front right seatbelt";
CM_ SG_ 1297 RCM_a113_eventVehicleSpeed "Restraint control module: a113 event vehicle speed";
CM_ SG_ 1297 RCM_a113_eventSteeringAngle "Restraint control module: a113 event steering angle";
CM_ SG_ 1297 RCM_a113_eventDriverBrakeApply "Restraint control module: a113 event driver brake apply; raw 3 = signal not available (SNA)";
CM_ SG_ 1297 RCM_a113_eventAccelPedalPos "Restraint control module: a113 event accel pedal pos; raw 255 = signal not available (SNA)";
CM_ SG_ 1297 RCM_a114_eventArmStatus "Restraint control module: a114 event arm status";
CM_ SG_ 1297 RCM_a114_eventFactoryMode "Restraint control module: a114 event factory mode";
CM_ SG_ 1297 RCM_a114_eventDiagEnabled "Restraint control module: a114 event diag enabled";
CM_ SG_ 1297 RCM_a114_eventDriveOrientation "Restraint control module: a114 event drive orientation";
CM_ SG_ 1297 RCM_a114_imuRollR8SnsrMonitTmp "Restraint control module: a114 imu roll R8 snsr monit tmp";
CM_ SG_ 1297 RCM_a114_imuRollR8SnsrMonitPerm "Restraint control module: a114 imu roll R8 snsr monit perm";
CM_ SG_ 1297 RCM_a114_imuRollR8ChnlMonitTmp "Restraint control module: a114 imu roll R8 chnl monit tmp";
CM_ SG_ 1297 RCM_a114_imuRollR8ChnlMonitPerm "Restraint control module: a114 imu roll R8 chnl monit perm";
CM_ SG_ 1297 RCM_a114_eventIDFsignal "Restraint control module: a114 event ID fsignal";
CM_ SG_ 1297 RCM_a114_eventFrontLeftSeatbelt "Restraint control module: a114 event front left seatbelt";
CM_ SG_ 1297 RCM_a114_eventFrontRightSeatbelt "Restraint control module: a114 event front right seatbelt";
CM_ SG_ 1297 RCM_a114_eventVehicleSpeed "Restraint control module: a114 event vehicle speed";
CM_ SG_ 1297 RCM_a114_eventSteeringAngle "Restraint control module: a114 event steering angle";
CM_ SG_ 1297 RCM_a114_eventDriverBrakeApply "Restraint control module: a114 event driver brake apply; raw 3 = signal not available (SNA)";
CM_ SG_ 1297 RCM_a114_eventAccelPedalPos "Restraint control module: a114 event accel pedal pos; raw 255 = signal not available (SNA)";
CM_ SG_ 1297 RCM_a115_eventArmStatus "Restraint control module: a115 event arm status";
CM_ SG_ 1297 RCM_a115_eventFactoryMode "Restraint control module: a115 event factory mode";
CM_ SG_ 1297 RCM_a115_eventDiagEnabled "Restraint control module: a115 event diag enabled";
CM_ SG_ 1297 RCM_a115_eventDriveOrientation "Restraint control module: a115 event drive orientation";
CM_ SG_ 1297 RCM_a115_imuLinAccChnlMonitTmp "Restraint control module: a115 imu lin acc chnl monit tmp";
CM_ SG_ 1297 RCM_a115_imuLinAccChnlMonitPerm "Restraint control module: a115 imu lin acc chnl monit perm";
CM_ SG_ 1297 RCM_a115_eventIDFsignal "Restraint control module: a115 event ID fsignal";
CM_ SG_ 1297 RCM_a115_eventFrontLeftSeatbelt "Restraint control module: a115 event front left seatbelt";
CM_ SG_ 1297 RCM_a115_eventFrontRightSeatbelt "Restraint control module: a115 event front right seatbelt";
CM_ SG_ 1297 RCM_a115_eventVehicleSpeed "Restraint control module: a115 event vehicle speed";
CM_ SG_ 1297 RCM_a115_eventSteeringAngle "Restraint control module: a115 event steering angle";
CM_ SG_ 1297 RCM_a115_eventDriverBrakeApply "Restraint control module: a115 event driver brake apply; raw 3 = signal not available (SNA)";
CM_ SG_ 1297 RCM_a115_eventAccelPedalPos "Restraint control module: a115 event accel pedal pos; raw 255 = signal not available (SNA)";
CM_ SG_ 1297 RCM_a116_eventArmStatus "Restraint control module: a116 event arm status";
CM_ SG_ 1297 RCM_a116_eventFactoryMode "Restraint control module: a116 event factory mode";
CM_ SG_ 1297 RCM_a116_eventDiagEnabled "Restraint control module: a116 event diag enabled";
CM_ SG_ 1297 RCM_a116_eventDriveOrientation "Restraint control module: a116 event drive orientation";
CM_ SG_ 1297 RCM_a116_imuLatAccChnlMonitTmp "Restraint control module: a116 imu lat acc chnl monit tmp";
CM_ SG_ 1297 RCM_a116_imuLatAccChnlMonitPerm "Restraint control module: a116 imu lat acc chnl monit perm";
CM_ SG_ 1297 RCM_a116_eventIDFsignal "Restraint control module: a116 event ID fsignal";
CM_ SG_ 1297 RCM_a116_eventFrontLeftSeatbelt "Restraint control module: a116 event front left seatbelt";
CM_ SG_ 1297 RCM_a116_eventFrontRightSeatbelt "Restraint control module: a116 event front right seatbelt";
CM_ SG_ 1297 RCM_a116_eventVehicleSpeed "Restraint control module: a116 event vehicle speed";
CM_ SG_ 1297 RCM_a116_eventSteeringAngle "Restraint control module: a116 event steering angle";
CM_ SG_ 1297 RCM_a116_eventDriverBrakeApply "Restraint control module: a116 event driver brake apply; raw 3 = signal not available (SNA)";
CM_ SG_ 1297 RCM_a116_eventAccelPedalPos "Restraint control module: a116 event accel pedal pos; raw 255 = signal not available (SNA)";
CM_ SG_ 1297 RCM_a117_eventArmStatus "Restraint control module: a117 event arm status";
CM_ SG_ 1297 RCM_a117_eventFactoryMode "Restraint control module: a117 event factory mode";
CM_ SG_ 1297 RCM_a117_eventDiagEnabled "Restraint control module: a117 event diag enabled";
CM_ SG_ 1297 RCM_a117_eventDriveOrientation "Restraint control module: a117 event drive orientation";
CM_ SG_ 1297 RCM_a117_imuZaccelChnlMonitTmp "Restraint control module: a117 imu zaccel chnl monit tmp";
CM_ SG_ 1297 RCM_a117_imuZaccelChnlMonitPerm "Restraint control module: a117 imu zaccel chnl monit perm";
CM_ SG_ 1297 RCM_a117_eventIDFsignal "Restraint control module: a117 event ID fsignal";
CM_ SG_ 1297 RCM_a117_eventFrontLeftSeatbelt "Restraint control module: a117 event front left seatbelt";
CM_ SG_ 1297 RCM_a117_eventFrontRightSeatbelt "Restraint control module: a117 event front right seatbelt";
CM_ SG_ 1297 RCM_a117_eventVehicleSpeed "Restraint control module: a117 event vehicle speed";
CM_ SG_ 1297 RCM_a117_eventSteeringAngle "Restraint control module: a117 event steering angle";
CM_ SG_ 1297 RCM_a117_eventDriverBrakeApply "Restraint control module: a117 event driver brake apply; raw 3 = signal not available (SNA)";
CM_ SG_ 1297 RCM_a117_eventAccelPedalPos "Restraint control module: a117 event accel pedal pos; raw 255 = signal not available (SNA)";
CM_ SG_ 1297 RCM_a118_eventArmStatus "Restraint control module: a118 event arm status";
CM_ SG_ 1297 RCM_a118_eventFactoryMode "Restraint control module: a118 event factory mode";
CM_ SG_ 1297 RCM_a118_eventDiagEnabled "Restraint control module: a118 event diag enabled";
CM_ SG_ 1297 RCM_a118_eventDriveOrientation "Restraint control module: a118 event drive orientation";
CM_ SG_ 1297 RCM_a118_imuInPlaneSnsrMonitTmp "Restraint control module: a118 imu in plane snsr monit tmp";
CM_ SG_ 1297 RCM_a118_imuInPlaneSnsrMonitPerm "Restraint control module: a118 imu in plane snsr monit perm";
CM_ SG_ 1297 RCM_a118_eventIDFsignal "Restraint control module: a118 event ID fsignal";
CM_ SG_ 1297 RCM_a118_eventFrontLeftSeatbelt "Restraint control module: a118 event front left seatbelt";
CM_ SG_ 1297 RCM_a118_eventFrontRightSeatbelt "Restraint control module: a118 event front right seatbelt";
CM_ SG_ 1297 RCM_a118_eventVehicleSpeed "Restraint control module: a118 event vehicle speed";
CM_ SG_ 1297 RCM_a118_eventSteeringAngle "Restraint control module: a118 event steering angle";
CM_ SG_ 1297 RCM_a118_eventDriverBrakeApply "Restraint control module: a118 event driver brake apply; raw 3 = signal not available (SNA)";
CM_ SG_ 1297 RCM_a118_eventAccelPedalPos "Restraint control module: a118 event accel pedal pos; raw 255 = signal not available (SNA)";
CM_ BO_ 881 "Restraint control module message: alert matrix";
CM_ SG_ 881 RCM_matrixIndex "Restraint control module: matrix index";
CM_ SG_ 881 RCM_a000_crashDetected "Restraint control module: a000 crash detected";
CM_ SG_ 881 RCM_a001_nearDeploy "Restraint control module: a001 near deploy";
CM_ SG_ 881 RCM_a002_airbagsNotArmed "Restraint control module: a002 airbags not armed";
CM_ SG_ 881 RCM_a003_warningIndicator "Restraint control module: a003 warning indicator";
CM_ SG_ 881 RCM_a004_internalFault "Restraint control module: a004 internal fault";
CM_ SG_ 881 RCM_a005_crcError "Restraint control module: a005 crc error";
CM_ SG_ 881 RCM_a006_batteryVoltageRange "Restraint control module: a006 battery voltage range";
CM_ SG_ 881 RCM_a007_powerSupplyExternal "Restraint control module: a007 power supply external";
CM_ SG_ 881 RCM_a008_powerSupplyInternal "Restraint control module: a008 power supply internal";
CM_ SG_ 881 RCM_a009_reprogramLimit "Restraint control module: a009 reprogram limit";
CM_ SG_ 881 RCM_a010_scmDisabled "Restraint control module: a010 scm disabled";
CM_ SG_ 881 RCM_a011_eepromDataLocked "Restraint control module: a011 eeprom data locked";
CM_ SG_ 881 RCM_a012_vinStorage "Restraint control module: a012 vin storage";
CM_ SG_ 881 RCM_a013_driverOrientation "Restraint control module: a013 driver orientation";
CM_ SG_ 881 RCM_a014_driverABStage1 "Restraint control module: a014 driver AB stage1";
CM_ SG_ 881 RCM_a015_driverABStage2 "Restraint control module: a015 driver AB stage2";
CM_ SG_ 881 RCM_a016_passABStage1 "Restraint control module: a016 pass AB stage1";
CM_ SG_ 881 RCM_a017_passABStage2 "Restraint control module: a017 pass AB stage2";
CM_ SG_ 881 RCM_a018_passengerActiveVent "Restraint control module: a018 passenger active vent";
CM_ SG_ 881 RCM_a019_pretenShldrFrontLeft "Restraint control module: a019 preten shldr front left";
CM_ SG_ 881 RCM_a020_pretenShldFrontRight "Restraint control module: a020 preten shld front right";
CM_ SG_ 881 RCM_a021_pretenLapFrontLeft "Restraint control module: a021 preten lap front left";
CM_ SG_ 881 RCM_a022_pretenLapFrontRight "Restraint control module: a022 preten lap front right";
CM_ SG_ 881 RCM_a023_loadLimiterLeftSide "Restraint control module: a023 load limiter left side";
CM_ SG_ 881 RCM_a024_loadLimiterRightSide "Restraint control module: a024 load limiter right side";
CM_ SG_ 881 RCM_a025_kneeABDriver "Restraint control module: a025 knee AB driver";
CM_ SG_ 881 RCM_a026_kneeABFrontPassenger "Restraint control module: a026 knee AB front passenger";
CM_ SG_ 881 RCM_a027_sideAB1stRowLeft "Restraint control module: a027 side ab1st row left";
CM_ SG_ 881 RCM_a028_sideAB1stRowRight "Restraint control module: a028 side ab1st row right";
CM_ SG_ 881 RCM_a029_driverABActiveVent "Restraint control module: a029 driver AB active vent";
CM_ SG_ 881 RCM_a030_farSideInboardAirbag "Restraint control module: a030 far side inboard airbag";
CM_ SG_ 881 RCM_a031_frontCenterAirbag "Restraint control module: a031 front center airbag";
CM_ SG_ 881 RCM_a032_curtainABLeft "Restraint control module: a032 curtain AB left";
CM_ SG_ 881 RCM_a033_curtainABRight "Restraint control module: a033 curtain AB right";
CM_ SG_ 881 RCM_a034_preten2ndRowLeft "Restraint control module: a034 preten2nd row left";
CM_ SG_ 881 RCM_a035_preten2ndRowRight "Restraint control module: a035 preten2nd row right";
CM_ SG_ 881 RCM_a036_curAB2ndRowLeft "Restraint control module: a036 cur ab2nd row left";
CM_ SG_ 881 RCM_a037_curAB2ndRowRight "Restraint control module: a037 cur ab2nd row right";
CM_ SG_ 881 RCM_a038_unusedA "Restraint control module: a038 unused a";
CM_ SG_ 881 RCM_a039_unusedB "Restraint control module: a039 unused b";
CM_ SG_ 881 RCM_a040_hoodActuatorRight "Restraint control module: a040 hood actuator right";
CM_ SG_ 881 RCM_a041_hoodActuatorLeft "Restraint control module: a041 hood actuator left";
CM_ SG_ 881 RCM_a042_ens1Line "Restraint control module: a042 ens1 line";
CM_ SG_ 881 RCM_a043_ens2Line "Restraint control module: a043 ens2 line";
CM_ SG_ 881 RCM_a044_upFrontSensorLeft "Restraint control module: a044 up front sensor left";
CM_ SG_ 881 RCM_a045_upFrontSensorRight "Restraint control module: a045 up front sensor right";
CM_ SG_ 881 RCM_a046_sideAccelBPillarLeft "Restraint control module: a046 side accel b pillar left";
CM_ SG_ 881 RCM_a047_sideAccelBPillarRight "Restraint control module: a047 side accel b pillar right";
CM_ SG_ 881 RCM_a048_sideAccelCPillarLeft "Restraint control module: a048 side accel c pillar left";
CM_ SG_ 881 RCM_a049_sideAccelCPillarRight "Restraint control module: a049 side accel c pillar right";
CM_ SG_ 881 RCM_a050_upFrontSensorCenter "Restraint control module: a050 up front sensor center";
CM_ SG_ 881 RCM_a051_pressureFrontLftDoor "Restraint control module: a051 pressure front lft door";
CM_ SG_ 881 RCM_a052_pressureFrontRtDoor "Restraint control module: a052 pressure front rt door";
CM_ SG_ 881 RCM_a053_pressurePedProLeft "Restraint control module: a053 pressure ped pro left";
CM_ SG_ 881 RCM_a054_pressurePedProRight "Restraint control module: a054 pressure ped pro right";
CM_ SG_ 881 RCM_a055_inertialMeasurement "Restraint control module: a055 inertial measurement";
CM_ SG_ 881 RCM_a056_passengerFrontOCS "Restraint control module: a056 passenger front OCS";
CM_ SG_ 881 RCM_a057_driverOCS "Restraint control module: a057 driver OCS";
CM_ SG_ 881 RCM_a058_buckle1stRowLeft "Restraint control module: a058 buckle1st row left";
CM_ SG_ 881 RCM_a059_buckle1stRowRight "Restraint control module: a059 buckle1st row right";
CM_ SG_ 881 RCM_a060_stpsLeft "Restraint control module: a060 stps left";
CM_ SG_ 881 RCM_a061_stpsRight "Restraint control module: a061 stps right";
CM_ SG_ 881 RCM_a062_alrSwitch "Restraint control module: a062 alr switch";
CM_ SG_ 881 RCM_a063_sbsw2ndRowRight "Restraint control module: a063 sbsw2nd row right";
CM_ SG_ 881 RCM_a064_hardwareCodingPin1 "Restraint control module: a064 hardware coding pin1";
CM_ SG_ 881 RCM_a065_driverOrientConfigPin "Restraint control module: a065 driver orient config pin";
CM_ SG_ 881 RCM_a066_seatBackSw2ndRowLeft "Restraint control module: a066 seat back sw2nd row left";
CM_ SG_ 881 RCM_a067_comCANInitFailure "Restraint control module: a067 com CAN init failure";
CM_ SG_ 881 RCM_a068_comChassisBusOff "Restraint control module: a068 com chassis bus off";
CM_ SG_ 881 RCM_a069_comCHCANPH7 "Restraint control module: a069 com CHCANPH7";
CM_ SG_ 881 RCM_a070_comCHCANPH8 "Restraint control module: a070 com CHCANPH8";
CM_ SG_ 881 RCM_a071_comCHCANPH9 "Restraint control module: a071 com CHCANPH9";
CM_ SG_ 881 RCM_a072_comUnused "Restraint control module: a072 com unused";
CM_ SG_ 881 RCM_a073_comCHCANPH4 "Restraint control module: a073 com CHCANPH4";
CM_ SG_ 881 RCM_a074_comCHCANPH5 "Restraint control module: a074 com CHCANPH5";
CM_ SG_ 881 RCM_a075_comCHCANPH6 "Restraint control module: a075 com CHCANPH6";
CM_ SG_ 881 RCM_a076_comEPBLStatus "Restraint control module: a076 com EPBL status";
CM_ SG_ 881 RCM_a077_comEPBRStatus "Restraint control module: a077 com EPBR status";
CM_ SG_ 881 RCM_a078_comOCS1PStatus "Restraint control module: a078 com OCS1 p status";
CM_ SG_ 881 RCM_a079_comOCS1DStatus "Restraint control module: a079 com OCS1 d status";
CM_ SG_ 881 RCM_a080_comGTWACS "Restraint control module: a080 com GTWACS";
CM_ SG_ 881 RCM_a081_comVCFRONTLVPwr "Restraint control module: a081 com VCFRONTLV pwr";
CM_ SG_ 881 RCM_a082_comUIodo "Restraint control module: a082 com u iodo";
CM_ SG_ 881 RCM_a083_comGTWCarState "Restraint control module: a083 com GTW car state";
CM_ SG_ 881 RCM_a084_comTPMSStatus "Restraint control module: a084 com TPMS status";
CM_ SG_ 881 RCM_a085_comGTWCarConfig "Restraint control module: a085 com GTW car config";
CM_ SG_ 881 RCM_a086_comVINMIA "Restraint control module: a086 com VINMIA";
CM_ SG_ 881 RCM_a087_comCANSilent "Restraint control module: a087 com CAN silent";
CM_ SG_ 881 RCM_a088_comCHCANPH2 "Restraint control module: a088 com CHCANPH2";
CM_ SG_ 881 RCM_a089_comCHCANPH3 "Restraint control module: a089 com CHCANPH3";
CM_ SG_ 881 RCM_a090_comPartyBusOff "Restraint control module: a090 com party bus off";
CM_ SG_ 881 RCM_a091_comEPAS3PsysStatus "Restraint control module: a091 com EPAS3 psys status";
CM_ SG_ 881 RCM_a092_comDASISF "Restraint control module: a092 com DASISF";
CM_ SG_ 881 RCM_a093_comVCLEFTStatus "Restraint control module: a093 com VCLEFT status";
CM_ SG_ 881 RCM_a094_comVCRIGHTStatus "Restraint control module: a094 com VCRIGHT status";
CM_ SG_ 881 RCM_a095_comESPstatus "Restraint control module: a095 com ES pstatus";
CM_ SG_ 881 RCM_a096_comESPwheelSpeeds "Restraint control module: a096 com ES pwheel speeds";
CM_ SG_ 881 RCM_a097_comDIspeed "Restraint control module: a097 com d ispeed";
CM_ SG_ 881 RCM_a098_comDIchassisControl "Restraint control module: a098 com d ichassis control";
CM_ SG_ 881 RCM_a099_comDItorque "Restraint control module: a099 com d itorque";
CM_ SG_ 881 RCM_a100_comDIsystemStatus "Restraint control module: a100 com d isystem status";
CM_ SG_ 881 RCM_a101_idfSystem "Restraint control module: a101 idf system";
CM_ SG_ 881 RCM_a102_imuYawR8OffstCompLim "Restraint control module: a102 imu yaw R8 offst comp lim";
CM_ SG_ 881 RCM_a103_imuPtchR8OffstCompLim "Restraint control module: a103 imu ptch R8 offst comp lim";
CM_ SG_ 881 RCM_a104_imuRollR8OffstCompLim "Restraint control module: a104 imu roll R8 offst comp lim";
CM_ SG_ 881 RCM_a105_imuLongAccOffstCompLim "Restraint control module: a105 imu long acc offst comp lim";
CM_ SG_ 881 RCM_a106_imuLatAccOffstCompLim "Restraint control module: a106 imu lat acc offst comp lim";
CM_ SG_ 881 RCM_a107_imuVertAccOffstCompLim "Restraint control module: a107 imu vert acc offst comp lim";
CM_ SG_ 881 RCM_a108_crashAlgoWakeup "Restraint control module: a108 crash algo wakeup";
CM_ SG_ 881 RCM_a109_abuseImmunity "Restraint control module: a109 abuse immunity";
CM_ SG_ 881 RCM_a110_factoryMode "Restraint control module: a110 factory mode";
CM_ SG_ 881 RCM_a111_diagnosticsEnabled "Restraint control module: a111 diagnostics enabled";
CM_ SG_ 881 RCM_a112_imuYawRate "Restraint control module: a112 imu yaw rate";
CM_ SG_ 881 RCM_a113_imuPitchRate "Restraint control module: a113 imu pitch rate";
CM_ SG_ 881 RCM_a114_imuRollRate "Restraint control module: a114 imu roll rate";
CM_ SG_ 881 RCM_a115_imuLinearAcceleration "Restraint control module: a115 imu linear acceleration";
CM_ SG_ 881 RCM_a116_imuLateralAcceleration "Restraint control module: a116 imu lateral acceleration";
CM_ SG_ 881 RCM_a117_imuVerticalAcceleration "Restraint control module: a117 imu vertical acceleration";
CM_ SG_ 881 RCM_a118_imuInPlaneAcceleration "Restraint control module: a118 imu in plane acceleration";
CM_ BO_ 1471 "RCU ECU message: alert log";
CM_ SG_ 1471 RCU_alertID "RCU ECU: alert ID";
CM_ SG_ 1471 RCU_alertState "RCU ECU: alert state";
CM_ SG_ 1471 RCU_a010_sensorPowerSupply "RCU ECU: a010 sensor power supply";
CM_ SG_ 1471 RCU_a010_sensorHardware "RCU ECU: a010 sensor hardware";
CM_ SG_ 1471 RCU_a010_sensorSignal "RCU ECU: a010 sensor signal";
CM_ SG_ 1471 RCU_a023_validityOnChassisBus "RCU ECU: a023 validity on chassis bus";
CM_ SG_ 1471 RCU_a023_validityOnPartyBus "RCU ECU: a023 validity on party bus";
CM_ SG_ 1471 RCU_a024_validityOnChassisBus "RCU ECU: a024 validity on chassis bus";
CM_ SG_ 1471 RCU_a024_validityOnPartyBus "RCU ECU: a024 validity on party bus";
CM_ SG_ 1471 RCU_a025_validityOnChassisBus "RCU ECU: a025 validity on chassis bus";
CM_ SG_ 1471 RCU_a025_validityOnPartyBus "RCU ECU: a025 validity on party bus";
CM_ SG_ 1471 RCU_a035_validityOnChassisBus "RCU ECU: a035 validity on chassis bus";
CM_ SG_ 1471 RCU_a035_validityOnPartyBus "RCU ECU: a035 validity on party bus";
CM_ SG_ 1471 RCU_a036_validityOnChassisBus "RCU ECU: a036 validity on chassis bus";
CM_ SG_ 1471 RCU_a036_validityOnPartyBus "RCU ECU: a036 validity on party bus";
CM_ BO_ 998 "RCU ECU message: alert matrix";
CM_ SG_ 998 RCU_matrixIndex "RCU ECU: matrix index";
CM_ SG_ 998 RCU_a001_valveDriverFault "RCU ECU: a001 valve driver fault";
CM_ SG_ 998 RCU_a002_solenoidValveFault "RCU ECU: a002 solenoid valve fault";
CM_ SG_ 998 RCU_a003_pumpMotorFault "RCU ECU: a003 pump motor fault";
CM_ SG_ 998 RCU_a004_supplyOvervoltage "RCU ECU: a004 supply overvoltage";
CM_ SG_ 998 RCU_a005_supplyUndervoltage "RCU ECU: a005 supply undervoltage";
CM_ SG_ 998 RCU_a006_wakeLineOpen "RCU ECU: a006 wake line open";
CM_ SG_ 998 RCU_a007_pressureSensorFault "RCU ECU: a007 pressure sensor fault";
CM_ SG_ 998 RCU_a008_pressureNotCalibrated "RCU ECU: a008 pressure not calibrated";
CM_ SG_ 998 RCU_a009_brakeFluidLow "RCU ECU: a009 brake fluid low";
CM_ SG_ 998 RCU_a010_pedalSensorFault "RCU ECU: a010 pedal sensor fault";
CM_ SG_ 998 RCU_a011_idbPedalTravelMismatch "RCU ECU: a011 idb pedal travel mismatch";
CM_ SG_ 998 RCU_a012_pedalSensorNotCal "RCU ECU: a012 pedal sensor not cal";
CM_ SG_ 998 RCU_a013_mcuGenericFault "RCU ECU: a013 mcu generic fault";
CM_ SG_ 998 RCU_a014_asicTempHigh "RCU ECU: a014 asic temp high";
CM_ SG_ 998 RCU_a015_fluidLeakDetected "RCU ECU: a015 fluid leak detected";
CM_ SG_ 998 RCU_a016_partyBusOff "RCU ECU: a016 party bus off";
CM_ SG_ 998 RCU_a017_chassisBusOff "RCU ECU: a017 chassis bus off";
CM_ SG_ 998 RCU_a018_DItorquePathFaulted "RCU ECU: a018 d itorque path faulted";
CM_ SG_ 998 RCU_a019_DItorquePathActive "RCU ECU: a019 d itorque path active";
CM_ SG_ 998 RCU_a020_BBstatusDLC "RCU ECU: a020 b bstatus DLC";
CM_ SG_ 998 RCU_a021_BBstatusChecksum "RCU ECU: a021 b bstatus checksum";
CM_ SG_ 998 RCU_a022_BBstatusCounter "RCU ECU: a022 b bstatus counter";
CM_ SG_ 998 RCU_a023_IDBstatusDLC "RCU ECU: a023 ID bstatus DLC";
CM_ SG_ 998 RCU_a024_IDBstatusChecksum "RCU ECU: a024 ID bstatus checksum";
CM_ SG_ 998 RCU_a025_IDBstatusCounter "RCU ECU: a025 ID bstatus counter";
CM_ SG_ 998 RCU_a026_DIchassisControlDLC "RCU ECU: a026 d ichassis control DLC";
CM_ SG_ 998 RCU_a027_DIchassisCtrlChecksum "RCU ECU: a027 d ichassis ctrl checksum";
CM_ SG_ 998 RCU_a028_DIchassisControlCounter "RCU ECU: a028 d ichassis control counter";
CM_ SG_ 998 RCU_a029_PMstate2DLC "RCU ECU: a029 p mstate2 DLC";
CM_ SG_ 998 RCU_a030_PMstate2Checksum "RCU ECU: a030 p mstate2 checksum";
CM_ SG_ 998 RCU_a031_PMstate2Counter "RCU ECU: a031 p mstate2 counter";
CM_ SG_ 998 RCU_a032_VCFRONTLVPowerStateDLC "RCU ECU: a032 VCFRONTLV power state DLC";
CM_ SG_ 998 RCU_a033_VCFRONTLVPowerStateChec "RCU ECU: a033 VCFRONTLV power state checksum";
CM_ SG_ 998 RCU_a034_VCFRONTLVPowerStateCoun "RCU ECU: a034 VCFRONTLV power state counter";
CM_ SG_ 998 RCU_a035_IDBpcpInvalid "RCU ECU: a035 ID bpcp invalid";
CM_ SG_ 998 RCU_a036_IDBpspInvalid "RCU ECU: a036 ID bpsp invalid";
CM_ SG_ 998 RCU_a037_IDBinputRodStrokeInvali "RCU ECU: a037 ID binput rod stroke invalid";
CM_ SG_ 998 RCU_a038_DIsystemStatusDLC "RCU ECU: a038 d isystem status DLC";
CM_ SG_ 998 RCU_a039_DIaccelPosInvalid "RCU ECU: a039 d iaccel pos invalid";
CM_ SG_ 998 RCU_a040_DIgearInvalid "RCU ECU: a040 d igear invalid";
CM_ SG_ 998 RCU_a041_DIsystemStatusCounter "RCU ECU: a041 d isystem status counter";
CM_ SG_ 998 RCU_a042_DIsystemStatusChecksum "RCU ECU: a042 d isystem status checksum";
CM_ SG_ 998 RCU_a043_VCFRONTiBoosterLvStateI "RCU ECU: a043 VCFRON ti booster lv state invalid";
CM_ SG_ 998 RCU_a044_VCFRONTsensorsMIA "RCU ECU: a044 VCFRON tsensors MIA";
CM_ SG_ 998 RCU_a045_VCFRONTtempInvalid "RCU ECU: a045 VCFRON ttemp invalid";
CM_ SG_ 998 RCU_a046_brakeFluidLevelSNA "RCU ECU: a046 brake fluid level SNA";
CM_ SG_ 998 RCU_a047_ESPwheelSpeedsDLC "RCU ECU: a047 ES pwheel speeds DLC";
CM_ SG_ 998 RCU_a048_ESPFrLWSSLInvalid "RCU ECU: a048 ESP fr LWSSL invalid";
CM_ SG_ 998 RCU_a049_ESPFrRWSSLInvalid "RCU ECU: a049 ESP fr RWSSL invalid";
CM_ SG_ 998 RCU_a050_ESPReLWSSLInvalid "RCU ECU: a050 ESP re LWSSL invalid";
CM_ SG_ 998 RCU_a051_ESPReRWSSLInvalid "RCU ECU: a051 ESP re RWSSL invalid";
CM_ SG_ 998 RCU_a052_ESPwheelSpeedsCounter "RCU ECU: a052 ES pwheel speeds counter";
CM_ SG_ 998 RCU_a053_ESPwheelSpeedsChecksum "RCU ECU: a053 ES pwheel speeds checksum";
CM_ SG_ 998 RCU_a054_IDBcircuitPressFaulted "RCU ECU: a054 ID bcircuit press faulted";
CM_ SG_ 998 RCU_a055_IDBsimulatorPressFaulte "RCU ECU: a055 ID bsimulator press faulted";
CM_ SG_ 998 RCU_a056_redundantControllerIsMa "RCU ECU: a056 redundant controller is master";
CM_ SG_ 998 RCU_a057_PMebrCmdStateInvalid "RCU ECU: a057 p mebr cmd state invalid";
CM_ SG_ 998 RCU_a058_DIbrakeTorqueCommandAnd "RCU ECU: a058 d ibrake torque command and flag mismatch";
CM_ BO_ 831 "RCU ECU message: info";
CM_ SG_ 831 RCU_infoIndex "RCU ECU: info index";
CM_ SG_ 831 RCU_infoPcbaID "RCU ECU: info pcba ID";
CM_ SG_ 831 RCU_infoAssemblyID "RCU ECU: info assembly ID";
CM_ SG_ 831 RCU_infoUsageID "RCU ECU: info usage ID";
CM_ SG_ 831 RCU_infoSubUsageID "RCU ECU: info sub usage ID";
CM_ BO_ 1410 "TCU ECU message: alert log";
CM_ SG_ 1410 TCU_alertID "TCU ECU: alert ID";
CM_ SG_ 1410 TCU_alertState "TCU ECU: alert state";
CM_ SG_ 1410 TCU_w001_FailCode "TCU ECU: w001 fail code";
CM_ SG_ 1410 TCU_w002_RejCause "TCU ECU: w002 rej cause";
CM_ SG_ 1410 TCU_w003_CallFailCode "TCU ECU: w003 call fail code";
CM_ SG_ 1410 TCU_w004_MSDFailCode "TCU ECU: w004 MSD fail code";
CM_ SG_ 1410 TCU_w006_Count "TCU ECU: w006 count";
CM_ BO_ 1472 "TCU ECU message: alert matrix1";
CM_ SG_ 1472 TCU_w001_IMSRegistrationFailed "TCU ECU: w001 IMS registration failed";
CM_ SG_ 1472 TCU_w002_CellRegRejected "TCU ECU: w002 cell reg rejected";
CM_ SG_ 1472 TCU_w003_ECallFailed "TCU ECU: w003 e call failed";
CM_ SG_ 1472 TCU_w004_MSDTransmissionFailed "TCU ECU: w004 MSD transmission failed";
CM_ SG_ 1472 TCU_w005_SIMSlotError "TCU ECU: w005 SIM slot error";
CM_ SG_ 1472 TCU_w006_MpssUnavailable "TCU ECU: w006 mpss unavailable";
CM_ BO_ 1409 "TCU ECU message: log";
CM_ SG_ 1409 TCU_logMux "TCU ECU: log mux";
CM_ SG_ 1409 TCU_cpuTemp "Indicates the current temperature reported by the Central Processing Unit (CPU) in the modem application processor";
CM_ SG_ 1409 TCU_cpuUsage "Indicates the current CPU usage in percentage reported by the modem application processor";
CM_ SG_ 1409 TCU_mdmCoreTemperature "Indicates the current Communication Processor (CP) temperature reported by the modem CP.";
CM_ SG_ 1409 TCU_availableMemory "Indicates the currently available Random Access Memory in the modem application processor";
CM_ SG_ 1409 TCU_pwm "Indicates the active Pulse Width Modulation (PWM) duty cycle applied to the modem fan.";
CM_ SG_ 1409 TCU_pwmcap "Indicates the active Pulse Width Modulation (PWM) duty cycle restriciton applied to the modem fan.";
CM_ SG_ 1409 TCU_totalResumes "Indicates the total amount of times the modem has been resumed";
CM_ SG_ 1409 TCU_mdmUplinkQueueSize "TCU ECU: mdm uplink queue size";
CM_ SG_ 1409 TCU_mdmRSRP "TCU ECU: mdm RSRP";
CM_ SG_ 1409 TCU_mdmSINR "TCU ECU: mdm SINR";
CM_ SG_ 1409 TCU_mdmUplinkAllowedRate "TCU ECU: mdm uplink allowed rate";
CM_ SG_ 1409 TCU_mdmUplinkAvgRage "TCU ECU: mdm uplink avg rage";
CM_ SG_ 1409 TCU_mdmServiceState "TCU ECU: mdm service state";
CM_ SG_ 1409 TCU_mdmIMSStatus "Indicates the current IP Multimedia System (IMS) registration state.";
CM_ SG_ 1409 TCU_mdmSIMStatus "TCU ECU: mdm SIM status";
CM_ SG_ 1409 TCU_mdmBusyActive "Reports whether the modem busy service is active on the modem application processor.; raw 4294967295 = signal not available (SNA)";
CM_ BO_ 1408 "TCU ECU message: status";
CM_ SG_ 1408 TCU_statusMux "TCU ECU: status mux";
CM_ SG_ 1408 TCU_wakeUpReason "TCU ECU: wake up reason; raw 4294967295 = signal not available (SNA)";
CM_ SG_ 1408 TCU_tcuCmdId "TCU ECU: tcu cmd id";
CM_ SG_ 1408 TCU_goingToSleep "TCU ECU: going to sleep; raw 4294967295 = signal not available (SNA)";
CM_ BO_ 1056 "UIS ECU message: log";
CM_ SG_ 1056 UIS_logMux "UIS ECU: log mux";
CM_ SG_ 1056 UIS_zramWriteTicks "UIS ECU: zram write ticks";
CM_ SG_ 1056 UIS_zramWriteIO "UIS ECU: zram write IO";
CM_ SG_ 1056 UIS_zramReadTicks "UIS ECU: zram read ticks";
CM_ SG_ 1056 UIS_zramReadIO "UIS ECU: zram read IO";
CM_ SG_ 1056 UIS_zramOriginalSize "UIS ECU: zram original size";
CM_ SG_ 1056 UIS_zramNotifyFree "UIS ECU: zram notify free";
CM_ SG_ 1056 UIS_zramInvalidIO "UIS ECU: zram invalid IO";
CM_ SG_ 1056 UIS_zramFailedWrites "UIS ECU: zram failed writes";
CM_ SG_ 1056 UIS_zramFailedReads "UIS ECU: zram failed reads";
CM_ SG_ 1056 UIS_zramCompressionRatio "UIS ECU: zram compression ratio";
CM_ SG_ 1056 UIS_zramCompressedSize "UIS ECU: zram compressed size";
CM_ SG_ 1056 UIS_wifiTemperature "Current temperature reported for wifi";
CM_ SG_ 1056 UIS_wifiStackState "WiFi stack state description";
CM_ SG_ 1056 UIS_wifiStackReady "UIS ECU: wifi stack ready";
CM_ SG_ 1056 UIS_wifiBars "WiFi bars for connected network";
CM_ SG_ 1056 UIS_wifiAutoJoinLowRSSI "Indicates an attempt to auto-join a known network with low Received Signal Strength Indicator (RSSI).";
CM_ SG_ 1056 UIS_webbrowserMemUsage "UIS ECU: webbrowser mem usage";
CM_ SG_ 1056 UIS_webbrowserCPUUsage "UIS ECU: webbrowser CPU usage";
CM_ SG_ 1056 UIS_vmtouchMemUsage "UIS ECU: vmtouch mem usage";
CM_ SG_ 1056 UIS_vmtouchCPUUsage "UIS ECU: vmtouch CPU usage";
CM_ SG_ 1056 UIS_videodMemUsage "UIS ECU: videod mem usage";
CM_ SG_ 1056 UIS_videodCPUUsage "UIS ECU: videod CPU usage";
CM_ SG_ 1056 UIS_vehicleMemUsage "UIS ECU: vehicle mem usage";
CM_ SG_ 1056 UIS_vehicleCPUUsage "UIS ECU: vehicle CPU usage";
CM_ SG_ 1056 UIS_valhallaserverMemUsage "UIS ECU: valhallaserver mem usage";
CM_ SG_ 1056 UIS_valhallaserverCPUUsage "UIS ECU: valhallaserver CPU usage";
CM_ SG_ 1056 UIS_valetMode "UI Valet Mode state";
CM_ SG_ 1056 UIS_uiQtCarUptime "Touchscreen UI software uptime";
CM_ SG_ 1056 UIS_uiQtCarSwapUsage "Signal reported by UIS ECU";
CM_ SG_ 1056 UIS_uiMeanFPS "UI mean frames per second over a 60s period";
CM_ SG_ 1056 UIS_uiMaxFrametime "UIS ECU: ui max frametime";
CM_ SG_ 1056 UIS_uiFramesOver200Ms "UIS ECU: ui frames over200 ms";
CM_ SG_ 1056 UIS_uiFramesOver100Ms "UIS ECU: ui frames over100 ms";
CM_ SG_ 1056 UIS_tunerVoltageUBatt "UIS ECU: tuner voltage u batt";
CM_ SG_ 1056 UIS_tunerVoltageOperation "Radio tuner operating voltage (mV)";
CM_ SG_ 1056 UIS_tunerVoltageMQS "UIS ECU: tuner voltage MQS";
CM_ SG_ 1056 UIS_tunerVoltageAntenna2 "Radio tuner voltage (mV) for antenna 2";
CM_ SG_ 1056 UIS_tunerVoltageAntenna1 "Radio tuner voltage (mV) for antenna 1";
CM_ SG_ 1056 UIS_tunerVoltage3V3 "UIS ECU: tuner voltage3 V3";
CM_ SG_ 1056 UIS_tunerVoltage1V8 "UIS ECU: tuner voltage1 V8";
CM_ SG_ 1056 UIS_tunerTemperatureFahrenheit "UIS ECU: tuner temperature fahrenheit";
CM_ SG_ 1056 UIS_tunerTemperatureCelsius "UIS ECU: tuner temperature celsius";
CM_ SG_ 1056 UIS_tunerCurrentAntenna2 "Radio tuner current (mA) for antenna 2";
CM_ SG_ 1056 UIS_tunerCurrentAntenna1 "Radio tuner current (mA) for antenna 1";
CM_ SG_ 1056 UIS_touchEventsAggCount "UIS ECU: touch events agg count";
CM_ SG_ 1056 UIS_tmserverMemUsage "UIS ECU: tmserver mem usage";
CM_ SG_ 1056 UIS_tmserverCPUUsage "UIS ECU: tmserver CPU usage";
CM_ SG_ 1056 UIS_testDriveMode "UIS ECU: test drive mode";
CM_ SG_ 1056 UIS_teslachromiumMemUsage "UIS ECU: teslachromium mem usage";
CM_ SG_ 1056 UIS_teslachromiumCPUUsage "UIS ECU: teslachromium CPU usage";
CM_ SG_ 1056 UIS_teslacefzygotMemUsage "UIS ECU: teslacefzygot mem usage";
CM_ SG_ 1056 UIS_teslacefzygotCPUUsage "UIS ECU: teslacefzygot CPU usage";
CM_ SG_ 1056 UIS_teslacefgpuMemUsage "UIS ECU: teslacefgpu mem usage";
CM_ SG_ 1056 UIS_teslacefgpuCPUUsage "UIS ECU: teslacefgpu CPU usage";
CM_ SG_ 1056 UIS_teslaMediaCacheSize "UIS ECU: tesla media cache size";
CM_ SG_ 1056 UIS_teslaMediaCacheCost "UIS ECU: tesla media cache cost";
CM_ SG_ 1056 UIS_tegraModemManState "Tegra Cellular Modem Manager state";
CM_ SG_ 1056 UIS_systemWakeTime "Length of time since wake or boot if UI has not slept (seconds)";
CM_ SG_ 1056 UIS_systemUptime "Reports the system uptime duration.";
CM_ SG_ 1056 UIS_systemMemSwapUsage "UIS ECU: system mem swap usage";
CM_ SG_ 1056 UIS_suspensionGeofence "Status of suspension geofence add or remove";
CM_ SG_ 1056 UIS_superchargePaymentNeeded "Reports that Supercharging payment is needed.";
CM_ SG_ 1056 UIS_sudokuMemUsage "UIS ECU: sudoku mem usage";
CM_ SG_ 1056 UIS_sudokuCPUUsage "UIS ECU: sudoku CPU usage";
CM_ SG_ 1056 UIS_spotifyserverMemUsage "UIS ECU: spotifyserver mem usage";
CM_ SG_ 1056 UIS_spotifyserverCPUUsage "UIS ECU: spotifyserver CPU usage";
CM_ SG_ 1056 UIS_speechrecoMemUsage "UIS ECU: speechreco mem usage";
CM_ SG_ 1056 UIS_speechrecoCPUUsage "UIS ECU: speechreco CPU usage";
CM_ SG_ 1056 UIS_solitaireMemUsage "UIS ECU: solitaire mem usage";
CM_ SG_ 1056 UIS_solitaireCPUUsage "UIS ECU: solitaire CPU usage";
CM_ SG_ 1056 UIS_sleepType "Reports the system sleep type.";
CM_ SG_ 1056 UIS_sleepTime "Reports the system sleep duration.";
CM_ SG_ 1056 UIS_sleepState "Reports the system sleep state.";
CM_ SG_ 1056 UIS_sleepCount "UIS ECU: sleep count";
CM_ SG_ 1056 UIS_slackerLoginResult "Reports Slacker Media login events";
CM_ SG_ 1056 UIS_settingsAutoTurnSignal "UIS ECU: settings auto turn signal";
CM_ SG_ 1056 UIS_serviceModePlus "Signal reported by UIS ECU";
CM_ SG_ 1056 UIS_serviceMode "Signal reported by UIS ECU";
CM_ SG_ 1056 UIS_serverMemUsage "UIS ECU: server mem usage";
CM_ SG_ 1056 UIS_serverCPUUsage "UIS ECU: server CPU usage";
CM_ SG_ 1056 UIS_sentryState "Sentry Mode state";
CM_ SG_ 1056 UIS_sentryNeedsNap "Sentry Mode sleep indicator, max uptime reached";
CM_ SG_ 1056 UIS_sentryIncidentCount "Sentry Mode incident count, initializes to 0";
CM_ SG_ 1056 UIS_scheduledChargingMode "Scheduled charging mode";
CM_ SG_ 1056 UIS_scheduleChargeStartTime "Reports the scheduled charging start date time in MMDDHHMM format.";
CM_ SG_ 1056 UIS_scheduleChargeEndTime "Reports the scheduled charging end date time in MMDDHHMM format.";
CM_ SG_ 1056 UIS_remoteRequestType "Reports the signed remote request type sent to vehicle, excluding closures and start requests.";
CM_ SG_ 1056 UIS_releasenotesMemUsage "UIS ECU: releasenotes mem usage";
CM_ SG_ 1056 UIS_releasenotesCPUUsage "UIS ECU: releasenotes CPU usage";
CM_ SG_ 1056 UIS_rearDisplayUserPresent "Indicates if a user is present in the rear seat based on seat occupancy and rear display usage";
CM_ SG_ 1056 UIS_rearDisplayState "Reports the rear display state.";
CM_ SG_ 1056 UIS_radioserveMemUsage "UIS ECU: radioserve mem usage";
CM_ SG_ 1056 UIS_radioserveCPUUsage "UIS ECU: radioserve CPU usage";
CM_ SG_ 1056 UIS_qtcarMemUsage "Signal reported by UIS ECU";
CM_ SG_ 1056 UIS_qtcarCPUUsage "Signal reported by UIS ECU";
CM_ SG_ 1056 UIS_psiMemSome "UIS ECU: psi mem some";
CM_ SG_ 1056 UIS_psiMemFull "UIS ECU: psi mem full";
CM_ SG_ 1056 UIS_psiIOSome "UIS ECU: psi IO some";
CM_ SG_ 1056 UIS_psiIOFull "UIS ECU: psi IO full";
CM_ SG_ 1056 UIS_psiCpuSome "UIS ECU: psi cpu some";
CM_ SG_ 1056 UIS_powerManagerState "UI power manager state signal; raw 18 = signal not available (SNA)";
CM_ SG_ 1056 UIS_polytopiax8664MemUsage "polytopiax8664's Resident Memory usage in MB";
CM_ SG_ 1056 UIS_polytopiax8664CPUUsage "polytopiax8664's CPU usage in CPU usage %";
CM_ SG_ 1056 UIS_odincefMemUsage "UIS ECU: odincef mem usage";
CM_ SG_ 1056 UIS_odincefCPUUsage "UIS ECU: odincef CPU usage";
CM_ SG_ 1056 UIS_odinStatusCmdResult "Signal reported by UIS ECU";
CM_ SG_ 1056 UIS_odinStatusCmdDurationMs "Signal reported by UIS ECU";
CM_ SG_ 1056 UIS_odinProcessState "Signal reported by UIS ECU";
CM_ SG_ 1056 UIS_odinOrchestratorStartCount "Signal reported by UIS ECU";
CM_ SG_ 1056 UIS_odinOrchestratorFailCount "Signal reported by UIS ECU";
CM_ SG_ 1056 UIS_odinNetworkStartCount "Signal reported by UIS ECU";
CM_ SG_ 1056 UIS_odinNetworkFailCount "Signal reported by UIS ECU";
CM_ SG_ 1056 UIS_odinMemUsage "Signal reported by UIS ECU";
CM_ SG_ 1056 UIS_odinListTasksCmdResult "Signal reported by UIS ECU";
CM_ SG_ 1056 UIS_odinListTasksCmdDurationMs "Signal reported by UIS ECU";
CM_ SG_ 1056 UIS_odinHrlUploadLimits "Signal reported by UIS ECU";
CM_ SG_ 1056 UIS_odinHrlLogUploadState "Signal reported by UIS ECU";
CM_ SG_ 1056 UIS_odinHermesConnectionState "Signal reported by UIS ECU";
CM_ SG_ 1056 UIS_odinGatewayConnectionState "Signal reported by UIS ECU";
CM_ SG_ 1056 UIS_odinFileSystemState "Signal reported by UIS ECU";
CM_ SG_ 1056 UIS_odinEcuLogUploadState "Signal reported by UIS ECU";
CM_ SG_ 1056 UIS_odinEcuLogForceTriggerUpload "Signal reported by UIS ECU";
CM_ SG_ 1056 UIS_odinCPUUsage "Signal reported by UIS ECU";
CM_ SG_ 1056 UIS_odinAuthFailCount "Signal reported by UIS ECU";
CM_ SG_ 1056 UIS_odinAuthCount "Signal reported by UIS ECU";
CM_ SG_ 1056 UIS_nvmeTemperature "UIS ECU: nvme temperature";
CM_ SG_ 1056 UIS_nvmePercentLifetimeUsed "UIS ECU: nvme percent lifetime used";
CM_ SG_ 1056 UIS_nvmeDataUnitsWritten100mb "UIS ECU: nvme data units written100mb";
CM_ SG_ 1056 UIS_numUncorrMemErrorsECC "UIS ECU: num uncorr mem errors ECC";
CM_ SG_ 1056 UIS_numCorrMemErrorsECC "UIS ECU: num corr mem errors ECC";
CM_ SG_ 1056 UIS_nuanceserverMemUsage "UIS ECU: nuanceserver mem usage";
CM_ SG_ 1056 UIS_nuanceserverCPUUsage "UIS ECU: nuanceserver CPU usage";
CM_ SG_ 1056 UIS_navAudioVolume "Navigation audio volume level";
CM_ SG_ 1056 UIS_muteNavVolume "Mute state of the navigation audio";
CM_ SG_ 1056 UIS_mounterdState "UIS ECU: mounterd state";
CM_ SG_ 1056 UIS_mounterdMountCountTotal "UIS ECU: mounterd mount count total";
CM_ SG_ 1056 UIS_mounterdFrontHubDisconnected "UIS ECU: mounterd front hub disconnected";
CM_ SG_ 1056 UIS_mounterdFrontHubConnected "UIS ECU: mounterd front hub connected";
CM_ SG_ 1056 UIS_mounterdFilesystemCountFat32 "UIS ECU: mounterd filesystem count fat32";
CM_ SG_ 1056 UIS_mounterdFilesystemCountExt4 "UIS ECU: mounterd filesystem count ext4";
CM_ SG_ 1056 UIS_mounterdFilesystemCountExt3 "UIS ECU: mounterd filesystem count ext3";
CM_ SG_ 1056 UIS_mounterdFilesystemCountExfat "UIS ECU: mounterd filesystem count exfat";
CM_ SG_ 1056 UIS_mounterdEncryptionCapacityGB "UIS ECU: mounterd encryption capacity GB";
CM_ SG_ 1056 UIS_mounterdDeviceCount "UIS ECU: mounterd device count";
CM_ SG_ 1056 UIS_mounterdDashcamCapacityGB "UIS ECU: mounterd dashcam capacity GB";
CM_ SG_ 1056 UIS_modemECallppAvail "Reports whether eCall++ is enabled and is running on Telematics Control Unit (TCU).";
CM_ SG_ 1056 UIS_modemBusyActive "Reports whether the modem busy logic is requested to be active on the modem application processor.";
CM_ SG_ 1056 UIS_mirrorGeofenceActive "Folding mirror geofence active status";
CM_ SG_ 1056 UIS_mediaserveMemUsage "UIS ECU: mediaserve mem usage";
CM_ SG_ 1056 UIS_mediaserveCPUUsage "UIS ECU: mediaserve CPU usage";
CM_ SG_ 1056 UIS_mediaPlaybackStatus "Media Current Playback Status";
CM_ SG_ 1056 UIS_mediaNeedAuthToken "Indicates whether the media system needs a new authentication token.";
CM_ SG_ 1056 UIS_mediaImageCacheSize "UIS ECU: media image cache size";
CM_ SG_ 1056 UIS_mediaImageCacheCost "UIS ECU: media image cache cost";
CM_ SG_ 1056 UIS_limex8664MemUsage "UIS ECU: limex8664 mem usage";
CM_ SG_ 1056 UIS_limex8664CPUUsage "UIS ECU: limex8664 CPU usage";
CM_ SG_ 1056 UIS_inSuperchargerGeofence "Vehicle inside Supercharger Geofence";
CM_ SG_ 1056 UIS_igpuTemperature "UIS ECU: igpu temperature";
CM_ SG_ 1056 UIS_homelinkState "State of Homelink sate machine";
CM_ SG_ 1056 UIS_hermesdynamicMemUsage "UIS ECU: hermesdynamic mem usage";
CM_ SG_ 1056 UIS_hermesdynamicCPUUsage "UIS ECU: hermesdynamic CPU usage";
CM_ SG_ 1056 UIS_hermesclientMemUsage "UIS ECU: hermesclient mem usage";
CM_ SG_ 1056 UIS_hermesclientCPUUsage "UIS ECU: hermesclient CPU usage";
CM_ SG_ 1056 UIS_headsetPairResult "Bluetooth headset pairing result";
CM_ SG_ 1056 UIS_headsetConnectionState "Bluetooth headset connection state";
CM_ SG_ 1056 UIS_gtwSocUartTxStatTimeouts "UIS ECU: gtw soc uart tx stat timeouts";
CM_ SG_ 1056 UIS_gtwSocUartTxStatPackets "UIS ECU: gtw soc uart tx stat packets";
CM_ SG_ 1056 UIS_gtwSocUartTxStatNacks "UIS ECU: gtw soc uart tx stat nacks";
CM_ SG_ 1056 UIS_gtwSocUartTxStatBadTooBig "UIS ECU: gtw soc uart tx stat bad too big";
CM_ SG_ 1056 UIS_gtwSocUartTxStatAnsMismatch "UIS ECU: gtw soc uart tx stat ans mismatch";
CM_ SG_ 1056 UIS_gtwSocUartRxStatValidPackets "UIS ECU: gtw soc uart rx stat valid packets";
CM_ SG_ 1056 UIS_gtwSocUartRxStatUnhandled "UIS ECU: gtw soc uart rx stat unhandled";
CM_ SG_ 1056 UIS_gtwSocUartRxStatMsgErr "UIS ECU: gtw soc uart rx stat msg err";
CM_ SG_ 1056 UIS_gtwSocUartRxStatHeartbeats "UIS ECU: gtw soc uart rx stat heartbeats";
CM_ SG_ 1056 UIS_gtwSocUartRxStatHandleErr "UIS ECU: gtw soc uart rx stat handle err";
CM_ SG_ 1056 UIS_gtwSocUartRxStatBadTooSmall "UIS ECU: gtw soc uart rx stat bad too small";
CM_ SG_ 1056 UIS_gtwSocUartRxStatBadTooBig "UIS ECU: gtw soc uart rx stat bad too big";
CM_ SG_ 1056 UIS_gtwSocUartRxStatBadChecksum "UIS ECU: gtw soc uart rx stat bad checksum";
CM_ SG_ 1056 UIS_gpsmanagerMemUsage "gpsManager's Resident Memory usage in MB";
CM_ SG_ 1056 UIS_gpsmanagerCPUUsage "gpsManager's CPU usage in CPU usage %";
CM_ SG_ 1056 UIS_godot_TIME_PROCESS "UIS ECU: godot TIME PROCESS";
CM_ SG_ 1056 UIS_godot_TIME_FPS "UIS ECU: godot TIME FPS";
CM_ SG_ 1056 UIS_godot_MEMORY_STATIC "UIS ECU: godot MEMORY STATIC";
CM_ SG_ 1056 UIS_godot_MEMORY_DYNAMIC "UIS ECU: godot MEMORY DYNAMIC";
CM_ SG_ 1056 UIS_godotMemUsage "UIS ECU: godot mem usage";
CM_ SG_ 1056 UIS_godotCPUUsage "UIS ECU: godot CPU usage";
CM_ SG_ 1056 UIS_firmwareReleaseScope "UIS ECU: firmware release scope";
CM_ SG_ 1056 UIS_featureSuperchargingEnabled "Reports the Supercharging enabled feature status.";
CM_ SG_ 1056 UIS_estimatedOccupancyCount "UIS ECU: estimated occupancy count";
CM_ SG_ 1056 UIS_embeddedGameState "UIS ECU: embedded game state";
CM_ SG_ 1056 UIS_embeddedGameName "UIS ECU: embedded game name";
CM_ SG_ 1056 UIS_dumTclipUploadState "UIS ECU: dum tclip upload state";
CM_ SG_ 1056 UIS_dumTclipUploadActive "UIS ECU: dum tclip upload active";
CM_ SG_ 1056 UIS_dumTclipTransferCount "UIS ECU: dum tclip transfer count";
CM_ SG_ 1056 UIS_dumTclipSuccessfulUploadCoun "UIS ECU: dum tclip successful upload count";
CM_ SG_ 1056 UIS_dumTclipClipCount "UIS ECU: dum tclip clip count";
CM_ SG_ 1056 UIS_dmRearTouchDeviceExists "Reports status of rear display power state.";
CM_ SG_ 1056 UIS_dmRearPowerState "Logs rear display power state status";
CM_ SG_ 1056 UIS_dmRearLinkCheckOk "Logs whether rear display-hardware-init was successful";
CM_ SG_ 1056 UIS_dmRearEnabled "Rear display is enabled";
CM_ SG_ 1056 UIS_dmRearConnected "Rear display is connected";
CM_ SG_ 1056 UIS_dmRearBacklightPowerLevel "UIS ECU: dm rear backlight power level";
CM_ SG_ 1056 UIS_dmRearBacklightNits "UIS ECU: dm rear backlight nits";
CM_ SG_ 1056 UIS_dmRearBacklightFault "UIS ECU: dm rear backlight fault";
CM_ SG_ 1056 UIS_dmRearBacklightDutyCycle "Logs rear backlight duty cycle status";
CM_ SG_ 1056 UIS_dmRearBacklightDevExists "Logs whether rear backlight device exists and was successfully detected";
CM_ SG_ 1056 UIS_dmRearAsilStatusMsb "UIS ECU: dm rear asil status msb";
CM_ SG_ 1056 UIS_dmRearAsilStatusLsb "UIS ECU: dm rear asil status lsb";
CM_ SG_ 1056 UIS_dmIcuTouchIrqCount "UIS ECU: dm icu touch irq count";
CM_ SG_ 1056 UIS_dmIcuPowerState "Logs cluster display power state status";
CM_ SG_ 1056 UIS_dmIcuLinkCheckOk "Logs whether cluster display-hardware-init was successful";
CM_ SG_ 1056 UIS_dmIcuEnabled "Cluster display is enabled";
CM_ SG_ 1056 UIS_dmIcuConnected "Cluster display is connected";
CM_ SG_ 1056 UIS_dmIcuBacklightPowerLevel "UIS ECU: dm icu backlight power level";
CM_ SG_ 1056 UIS_dmIcuBacklightNits "UIS ECU: dm icu backlight nits";
CM_ SG_ 1056 UIS_dmIcuBacklightFault "UIS ECU: dm icu backlight fault";
CM_ SG_ 1056 UIS_dmIcuBacklightDutyCycle "Logs cluster backlight duty cycle status";
CM_ SG_ 1056 UIS_dmIcuBacklightDevExists "Logs whether cluster backlight device exists and was successfully detected";
CM_ SG_ 1056 UIS_dmIcuAsilShortFlag "UIS ECU: dm icu asil short flag";
CM_ SG_ 1056 UIS_dmIcuAsilResumeFlag "UIS ECU: dm icu asil resume flag";
CM_ SG_ 1056 UIS_dmIcuAsilOpenFlag "UIS ECU: dm icu asil open flag";
CM_ SG_ 1056 UIS_dmIcuAsilFirmwareStatus "UIS ECU: dm icu asil firmware status";
CM_ SG_ 1056 UIS_dmGatewayLinkWedged "Indicates whether the center display gateway link is stuck.";
CM_ SG_ 1056 UIS_dmCenterTouchIrqCount "UIS ECU: dm center touch irq count";
CM_ SG_ 1056 UIS_dmCenterTouchDeviceExists "Detects whether the center display touch input device is present.";
CM_ SG_ 1056 UIS_dmCenterSOsdVideoCrcData "UIS ECU: dm center s osd video crc data";
CM_ SG_ 1056 UIS_dmCenterSOsdExactCrcCheck "UIS ECU: dm center s osd exact crc check";
CM_ SG_ 1056 UIS_dmCenterPowerState "Logs center display power state status";
CM_ SG_ 1056 UIS_dmCenterOsdDisplayedState "Reports the center display On-Screen Display (OSD) shown state.";
CM_ SG_ 1056 UIS_dmCenterOsdDayNightState "UIS ECU: dm center osd day night state";
CM_ SG_ 1056 UIS_dmCenterModeSettingStatus "UIS ECU: dm center mode setting status";
CM_ SG_ 1056 UIS_dmCenterMOsdVideoCrcData "UIS ECU: dm center m osd video crc data";
CM_ SG_ 1056 UIS_dmCenterMOsdExactCrcCheck "UIS ECU: dm center m osd exact crc check";
CM_ SG_ 1056 UIS_dmCenterLinkCheckOk "Logs whether center display-hardware-init was successful";
CM_ SG_ 1056 UIS_dmCenterEnabled "Center display is enabled";
CM_ SG_ 1056 UIS_dmCenterConnected "Center display is connected";
CM_ SG_ 1056 UIS_dmCenterBacklightPowerLevel "Logs backlight power level for center display";
CM_ SG_ 1056 UIS_dmCenterBacklightNits "UIS ECU: dm center backlight nits";
CM_ SG_ 1056 UIS_dmCenterBacklightFault "UIS ECU: dm center backlight fault";
CM_ SG_ 1056 UIS_dmCenterBacklightDutyCycle "Logs center backlight duty cycle status";
CM_ SG_ 1056 UIS_dmCenterBacklightDevExists "Logs whether center backlight device exists and was successfully detected";
CM_ SG_ 1056 UIS_dmCenterAsilShortFlag "UIS ECU: dm center asil short flag";
CM_ SG_ 1056 UIS_dmCenterAsilResumeFlag "UIS ECU: dm center asil resume flag";
CM_ SG_ 1056 UIS_dmCenterAsilOpenFlag "UIS ECU: dm center asil open flag";
CM_ SG_ 1056 UIS_dmCenterAsilFirmwareStatus "UIS ECU: dm center asil firmware status";
CM_ SG_ 1056 UIS_dgpuTemperature "Current temperature reported for dgpu";
CM_ SG_ 1056 UIS_developerMode "UIS ECU: developer mode";
CM_ SG_ 1056 UIS_dashcamviewerMemUsage "dashcamViewer's Resident Memory usage in MB";
CM_ SG_ 1056 UIS_dashcamviewerCPUUsage "dashcamViewer's CPU usage in CPU usage %";
CM_ SG_ 1056 UIS_dashcamTransferTimeMs "UIS ECU: dashcam transfer time ms";
CM_ SG_ 1056 UIS_dashcamTransferSizeMB "UIS ECU: dashcam transfer size MB";
CM_ SG_ 1056 UIS_dashcamTransferRateMBps "UIS ECU: dashcam transfer rate m bps";
CM_ SG_ 1056 UIS_dashcamTransferFileCount "UIS ECU: dashcam transfer file count";
CM_ SG_ 1056 UIS_dashcamTransferCount "UIS ECU: dashcam transfer count";
CM_ SG_ 1056 UIS_dashcamStorageState "Internal state of the dashcam storage";
CM_ SG_ 1056 UIS_dashcamStorageSentryMB "Dashcam USB storage used by Sentry Clips in MB";
CM_ SG_ 1056 UIS_dashcamStorageSavedMB "Dashcam USB storage used by Saved Clips in MB";
CM_ SG_ 1056 UIS_dashcamStorageRecentMB "Dashcam USB storage used by Recent Clips in MB";
CM_ SG_ 1056 UIS_dashcamStorageAvailableMB "Dashcam USB storage that is Available in MB";
CM_ SG_ 1056 UIS_dashcamState "Internal state for the dashcam state machine";
CM_ SG_ 1056 UIS_dashcamSavedToSentryCount "UIS ECU: dashcam saved to sentry count";
CM_ SG_ 1056 UIS_dashcamSavedToSavedCount "UIS ECU: dashcam saved to saved count";
CM_ SG_ 1056 UIS_dashcamSavedToOnboardCount "UIS ECU: dashcam saved to onboard count";
CM_ SG_ 1056 UIS_dashcamOnboardTransferCount "UIS ECU: dashcam onboard transfer count";
CM_ SG_ 1056 UIS_dashcamOnboardSavePressCount "UIS ECU: dashcam onboard save press count";
CM_ SG_ 1056 UIS_dashcamOnboardMB "UIS ECU: dashcam onboard MB";
CM_ SG_ 1056 UIS_dashcamOnboardAvailableMB "UIS ECU: dashcam onboard available MB";
CM_ SG_ 1056 UIS_cpuTemperature "Current temperature reported for cpu";
CM_ SG_ 1056 UIS_compositorRenderMinRenderTim "UIS ECU: compositor render min render time";
CM_ SG_ 1056 UIS_compositorRenderMinFrameTime "UIS ECU: compositor render min frame time";
CM_ SG_ 1056 UIS_compositorRenderMaxRenderTim "UIS ECU: compositor render max render time";
CM_ SG_ 1056 UIS_compositorRenderMaxFrameTime "UIS ECU: compositor render max frame time";
CM_ SG_ 1056 UIS_compositorRenderGpuPercentag "UIS ECU: compositor render gpu percentage";
CM_ SG_ 1056 UIS_compositorRenderFrameRate "UIS ECU: compositor render frame rate";
CM_ SG_ 1056 UIS_compositorRenderFrameCount "UIS ECU: compositor render frame count";
CM_ SG_ 1056 UIS_compositorRenderAvgRenderTim "UIS ECU: compositor render avg render time";
CM_ SG_ 1056 UIS_compositorFrameMonitorState "UIS ECU: compositor frame monitor state";
CM_ SG_ 1056 UIS_cobaltlinuxMemUsage "UIS ECU: cobaltlinux mem usage";
CM_ SG_ 1056 UIS_cobaltlinuxCPUUsage "UIS ECU: cobaltlinux CPU usage";
CM_ SG_ 1056 UIS_clusterMemUsage "cluster's Resident Memory usage in MB";
CM_ SG_ 1056 UIS_clusterMeanFPS "UIS ECU: cluster mean FPS";
CM_ SG_ 1056 UIS_clusterMaxFrametime "UIS ECU: cluster max frametime";
CM_ SG_ 1056 UIS_clusterFramesOver200Ms "UIS ECU: cluster frames over200 ms";
CM_ SG_ 1056 UIS_clusterFramesOver100Ms "UIS ECU: cluster frames over100 ms";
CM_ SG_ 1056 UIS_clusterDisplayState "Reports the instrument cluster display state.";
CM_ SG_ 1056 UIS_clusterCPUUsage "cluster's CPU usage in CPU usage %";
CM_ SG_ 1056 UIS_chromiumadapterMemUsage "UIS ECU: chromiumadapter mem usage";
CM_ SG_ 1056 UIS_chromiumadapterCPUUsage "UIS ECU: chromiumadapter CPU usage";
CM_ SG_ 1056 UIS_chargeOnSolarNoChargeReason "Reason car is not charging on solar";
CM_ SG_ 1056 UIS_ceruleanx8664MemUsage "UIS ECU: ceruleanx8664 mem usage";
CM_ SG_ 1056 UIS_ceruleanx8664CPUUsage "UIS ECU: ceruleanx8664 CPU usage";
CM_ SG_ 1056 UIS_centerDisplayState "Reports the center display state.";
CM_ SG_ 1056 UIS_centerDisplayEvent "Reports the events that cause center display state transitions.";
CM_ SG_ 1056 UIS_centerDispAsilB_msb "UIS ECU: center disp asil b msb";
CM_ SG_ 1056 UIS_centerDispAsilB_lsb "UIS ECU: center disp asil b lsb";
CM_ SG_ 1056 UIS_centerDispAsilA_msb "UIS ECU: center disp asil a msb";
CM_ SG_ 1056 UIS_centerDispAsilA_lsb "UIS ECU: center disp asil a lsb";
CM_ SG_ 1056 UIS_cellularLinkManagerState "CellLink Manager state";
CM_ SG_ 1056 UIS_carAssistState "Car Assist State";
CM_ SG_ 1056 UIS_carAssistSessionCount "Car Assist Session Count";
CM_ SG_ 1056 UIS_carAssistErrorCode "Car Assist Error Code";
CM_ SG_ 1056 UIS_cameraRRepeaterStreamMissing "Signal representing if left repeater camera stream is active within videod";
CM_ SG_ 1056 UIS_cameraRRepeaterStream "UIS ECU: camera r repeater stream";
CM_ SG_ 1056 UIS_cameraRRepeaterPopup "Right repeater camera popup state";
CM_ SG_ 1056 UIS_cameraRRepeaterPipeline "Right repeater videod pipeline state";
CM_ SG_ 1056 UIS_cameraRRepeaterMaxFrametime "UIS ECU: camera r repeater max frametime";
CM_ SG_ 1056 UIS_cameraRRepeaterLateFrames "UIS ECU: camera r repeater late frames";
CM_ SG_ 1056 UIS_cameraRRepeaterFramerate "UIS ECU: camera r repeater framerate";
CM_ SG_ 1056 UIS_cameraLRepeaterStreamMissing "Signal representing if left repeater camera stream is active within videod";
CM_ SG_ 1056 UIS_cameraLRepeaterStream "UIS ECU: camera l repeater stream";
CM_ SG_ 1056 UIS_cameraLRepeaterPopup "Left repeater camera popup state";
CM_ SG_ 1056 UIS_cameraLRepeaterPipeline "Left repeater videod pipeline state";
CM_ SG_ 1056 UIS_cameraLRepeaterMaxFrametime "UIS ECU: camera l repeater max frametime";
CM_ SG_ 1056 UIS_cameraLRepeaterLateFrames "UIS ECU: camera l repeater late frames";
CM_ SG_ 1056 UIS_cameraLRepeaterFramerate "UIS ECU: camera l repeater framerate";
CM_ SG_ 1056 UIS_cameraFrontStreamMissing "UIS ECU: camera front stream missing";
CM_ SG_ 1056 UIS_cameraFrontStream "UIS ECU: camera front stream";
CM_ SG_ 1056 UIS_cameraFrontPopup "UIS ECU: camera front popup";
CM_ SG_ 1056 UIS_cameraFrontPipeline "UIS ECU: camera front pipeline";
CM_ SG_ 1056 UIS_cameraBackupStreamQuality "UIS ECU: camera backup stream quality";
CM_ SG_ 1056 UIS_cameraBackupStreamMissing "Signal representing if backup camera stream is active within videod";
CM_ SG_ 1056 UIS_cameraBackupStream "UIS ECU: camera backup stream";
CM_ SG_ 1056 UIS_cameraBackupPopup "Reports the backup camera popup state.";
CM_ SG_ 1056 UIS_cameraBackupPipeline "Reports the backup camera video pipeline state.";
CM_ SG_ 1056 UIS_cameraBackupMaxFrametime "UIS ECU: camera backup max frametime";
CM_ SG_ 1056 UIS_cameraBackupLateFrames "UIS ECU: camera backup late frames";
CM_ SG_ 1056 UIS_cameraBackupFramerate "Reports the backup camera framerate.";
CM_ SG_ 1056 UIS_camBackupDecodeMinFrametime "UIS ECU: cam backup decode min frametime";
CM_ SG_ 1056 UIS_camBackupDecodeMaxFrametime "UIS ECU: cam backup decode max frametime";
CM_ SG_ 1056 UIS_camBackupDecodeFramecount "UIS ECU: cam backup decode framecount";
CM_ SG_ 1056 UIS_camBackupDecodeAvgFrametime "UIS ECU: cam backup decode avg frametime";
CM_ SG_ 1056 UIS_bootCount "UIS ECU: boot count";
CM_ SG_ 1056 UIS_boardTemperature "Current temperature reported for board";
CM_ SG_ 1056 UIS_bluetoothStackState "Bluetooth stack state";
CM_ SG_ 1056 UIS_bluetoothStackRearState "Bluetooth rear stack state";
CM_ SG_ 1056 UIS_bluetoothPairResult "Bluetooth pairing result";
CM_ SG_ 1056 UIS_bluetoothMemUsage "Reports the Bluetooth process resident memory usage in megabytes.";
CM_ SG_ 1056 UIS_bluetoothConnectionState "Reports the Bluetooth connection state.";
CM_ SG_ 1056 UIS_bluetoothCPUUsage "Reports the Bluetooth process Central Processing Unit (CPU) usage percentage.";
CM_ SG_ 1056 UIS_bluetoothAutoConnectionState "Reports the Bluetooth auto-connection state.";
CM_ SG_ 1056 UIS_bifrostOdinEngineUp "Signal reported by UIS ECU";
CM_ SG_ 1056 UIS_bifrostOdinEngineRequests "Signal reported by UIS ECU";
CM_ SG_ 1056 UIS_bifrostMemUsage "UIS ECU: bifrost mem usage";
CM_ SG_ 1056 UIS_bifrostCPUUsage "UIS ECU: bifrost CPU usage";
CM_ SG_ 1056 UIS_backlightUserRequest "Reports the Graphical User Interface (GUI) backlight user request value.";
CM_ SG_ 1056 UIS_audioVolumeLevel "User facing volume level";
CM_ SG_ 1056 UIS_audioType "Shows which audio amplifier type is currently configured";
CM_ SG_ 1056 UIS_audioState "Shows the state of the audio system";
CM_ SG_ 1056 UIS_audioSource "Shows which internal audio source is currently active";
CM_ SG_ 1056 UIS_audioPWSGain "Reports the pedestrian warning system volume in decibels.";
CM_ SG_ 1056 UIS_audioMediaPlaying "Shows which media source is currently being played";
CM_ SG_ 1056 UIS_audioMediaBrowsing "Shows which media source is currently being viewed";
CM_ SG_ 1056 UIS_audioA2BRediscoveryCount "Shows the count of a2b rediscoveries that have occurred";
CM_ SG_ 1056 UIS_amdSocPkgPower "UIS ECU: amd soc pkg power";
CM_ SG_ 1056 UIS_activeAppView "Shows the currently displayed app";
BA_DEF_ BO_ "GenMsgCycleTime" INT 0 3600000;
BA_DEF_ BO_ "GenMsgSendType" ENUM "Cyclic","NotUsed","NotUsed","NotUsed","NotUsed","NotUsed","NotUsed","IfActive","NoMsgSendType","NotUsed";
BA_DEF_ BO_ "VFrameFormat" ENUM "StandardCAN","ExtendedCAN","reserved","J1939PG","reserved","reserved","reserved","reserved","reserved","reserved","reserved","reserved","reserved","reserved","StandardCAN_FD","ExtendedCAN_FD";
BA_DEF_ BO_ "CANFD_BRS" ENUM "0","1";
BA_DEF_ SG_ "GenSigSNA" STRING;
BA_DEF_ SG_ "SystemSignalLongSymbol" STRING;
BA_DEF_ SG_ "Confidence" ENUM "validated","plausible","layout-only","contradicted";
BA_DEF_DEF_ "GenMsgCycleTime" 0;
BA_DEF_DEF_ "GenMsgSendType" "NoMsgSendType";
BA_DEF_DEF_ "VFrameFormat" "StandardCAN";
BA_DEF_DEF_ "CANFD_BRS" "1";
BA_DEF_DEF_ "GenSigSNA" "";
BA_DEF_DEF_ "SystemSignalLongSymbol" "";
BA_DEF_DEF_ "Confidence" "layout-only";
BA_ "GenMsgCycleTime" BO_ 881 1000;
BA_ "GenMsgSendType" BO_ 881 0;
BA_ "GenMsgCycleTime" BO_ 998 1000;
BA_ "GenMsgSendType" BO_ 998 0;
BA_ "GenMsgCycleTime" BO_ 831 10000;
BA_ "GenMsgSendType" BO_ 831 0;
BA_ "GenMsgCycleTime" BO_ 1472 1000;
BA_ "GenMsgSendType" BO_ 1472 0;
BA_ "GenMsgCycleTime" BO_ 1409 1000;
BA_ "GenMsgSendType" BO_ 1409 0;
BA_ "GenMsgCycleTime" BO_ 1408 1000;
BA_ "GenMsgSendType" BO_ 1408 0;
BA_ "Confidence" SG_ 1297 RCM_a104_eventDriverBrakeApply 1;
BA_ "GenSigSNA" SG_ 1297 RCM_a104_eventDriverBrakeApply "3";
BA_ "Confidence" SG_ 1297 RCM_a104_eventAccelPedalPos 1;
BA_ "GenSigSNA" SG_ 1297 RCM_a104_eventAccelPedalPos "255";
BA_ "Confidence" SG_ 1297 RCM_a105_eventArmStatus 1;
BA_ "Confidence" SG_ 1297 RCM_a105_eventFactoryMode 1;
BA_ "Confidence" SG_ 1297 RCM_a105_eventDiagEnabled 1;
BA_ "Confidence" SG_ 1297 RCM_a105_eventDriveOrientation 1;
BA_ "Confidence" SG_ 1297 RCM_a105_eventIDFsignal 1;
BA_ "Confidence" SG_ 1297 RCM_a105_eventFrontLeftSeatbelt 1;
BA_ "Confidence" SG_ 1297 RCM_a105_eventFrontRightSeatbelt 1;
BA_ "Confidence" SG_ 1297 RCM_a105_eventVehicleSpeed 1;
BA_ "Confidence" SG_ 1297 RCM_a105_eventSteeringAngle 1;
BA_ "Confidence" SG_ 1297 RCM_a105_eventDriverBrakeApply 1;
BA_ "GenSigSNA" SG_ 1297 RCM_a105_eventDriverBrakeApply "3";
BA_ "Confidence" SG_ 1297 RCM_a105_eventAccelPedalPos 1;
BA_ "GenSigSNA" SG_ 1297 RCM_a105_eventAccelPedalPos "255";
BA_ "Confidence" SG_ 1297 RCM_a106_eventArmStatus 1;
BA_ "Confidence" SG_ 1297 RCM_a106_eventFactoryMode 1;
BA_ "Confidence" SG_ 1297 RCM_a106_eventDiagEnabled 1;
BA_ "Confidence" SG_ 1297 RCM_a106_eventDriveOrientation 1;
BA_ "Confidence" SG_ 1297 RCM_a106_eventIDFsignal 1;
BA_ "Confidence" SG_ 1297 RCM_a106_eventFrontLeftSeatbelt 1;
BA_ "Confidence" SG_ 1297 RCM_a106_eventFrontRightSeatbelt 1;
BA_ "Confidence" SG_ 1297 RCM_a106_eventVehicleSpeed 1;
BA_ "Confidence" SG_ 1297 RCM_a106_eventSteeringAngle 1;
BA_ "Confidence" SG_ 1297 RCM_a106_eventDriverBrakeApply 1;
BA_ "GenSigSNA" SG_ 1297 RCM_a106_eventDriverBrakeApply "3";
BA_ "Confidence" SG_ 1297 RCM_a106_eventAccelPedalPos 1;
BA_ "GenSigSNA" SG_ 1297 RCM_a106_eventAccelPedalPos "255";
BA_ "Confidence" SG_ 1297 RCM_a107_eventArmStatus 1;
BA_ "Confidence" SG_ 1297 RCM_a107_eventFactoryMode 1;
BA_ "Confidence" SG_ 1297 RCM_a107_eventDiagEnabled 1;
BA_ "Confidence" SG_ 1297 RCM_a107_eventDriveOrientation 1;
BA_ "Confidence" SG_ 1297 RCM_a107_eventIDFsignal 1;
BA_ "Confidence" SG_ 1297 RCM_a107_eventFrontLeftSeatbelt 1;
BA_ "Confidence" SG_ 1297 RCM_a107_eventFrontRightSeatbelt 1;
BA_ "Confidence" SG_ 1297 RCM_a107_eventVehicleSpeed 1;
BA_ "Confidence" SG_ 1297 RCM_a107_eventSteeringAngle 1;
BA_ "Confidence" SG_ 1297 RCM_a107_eventDriverBrakeApply 1;
BA_ "GenSigSNA" SG_ 1297 RCM_a107_eventDriverBrakeApply "3";
BA_ "Confidence" SG_ 1297 RCM_a107_eventAccelPedalPos 1;
BA_ "GenSigSNA" SG_ 1297 RCM_a107_eventAccelPedalPos "255";
BA_ "Confidence" SG_ 1297 RCM_a108_eventArmStatus 1;
BA_ "Confidence" SG_ 1297 RCM_a108_eventFactoryMode 1;
BA_ "Confidence" SG_ 1297 RCM_a108_eventDiagEnabled 1;
BA_ "Confidence" SG_ 1297 RCM_a108_eventDriveOrientation 1;
BA_ "Confidence" SG_ 1297 RCM_a108_eventIDFsignal 1;
BA_ "Confidence" SG_ 1297 RCM_a108_eventFrontLeftSeatbelt 1;
BA_ "Confidence" SG_ 1297 RCM_a108_eventFrontRightSeatbelt 1;
BA_ "Confidence" SG_ 1297 RCM_a108_eventVehicleSpeed 1;
BA_ "Confidence" SG_ 1297 RCM_a108_eventSteeringAngle 1;
BA_ "Confidence" SG_ 1297 RCM_a108_eventDriverBrakeApply 1;
BA_ "GenSigSNA" SG_ 1297 RCM_a108_eventDriverBrakeApply "3";
BA_ "Confidence" SG_ 1297 RCM_a108_eventAccelPedalPos 1;
BA_ "GenSigSNA" SG_ 1297 RCM_a108_eventAccelPedalPos "255";
BA_ "Confidence" SG_ 1297 RCM_a109_eventArmStatus 1;
BA_ "Confidence" SG_ 1297 RCM_a109_eventFactoryMode 1;
BA_ "Confidence" SG_ 1297 RCM_a109_eventDiagEnabled 1;
BA_ "Confidence" SG_ 1297 RCM_a109_eventDriveOrientation 1;
BA_ "Confidence" SG_ 1297 RCM_a109_eventIDFsignal 1;
BA_ "Confidence" SG_ 1297 RCM_a109_eventFrontLeftSeatbelt 1;
BA_ "Confidence" SG_ 1297 RCM_a109_eventFrontRightSeatbelt 1;
BA_ "Confidence" SG_ 1297 RCM_a109_eventVehicleSpeed 1;
BA_ "Confidence" SG_ 1297 RCM_a109_eventSteeringAngle 1;
BA_ "Confidence" SG_ 1297 RCM_a109_eventDriverBrakeApply 1;
BA_ "GenSigSNA" SG_ 1297 RCM_a109_eventDriverBrakeApply "3";
BA_ "Confidence" SG_ 1297 RCM_a109_eventAccelPedalPos 1;
BA_ "GenSigSNA" SG_ 1297 RCM_a109_eventAccelPedalPos "255";
BA_ "Confidence" SG_ 1297 RCM_a110_eventArmStatus 1;
BA_ "Confidence" SG_ 1297 RCM_a110_eventFactoryMode 1;
BA_ "Confidence" SG_ 1297 RCM_a110_eventDiagEnabled 1;
BA_ "Confidence" SG_ 1297 RCM_a110_eventDriveOrientation 1;
BA_ "Confidence" SG_ 1297 RCM_a110_eventIDFsignal 1;
BA_ "Confidence" SG_ 1297 RCM_a110_eventFrontLeftSeatbelt 1;
BA_ "Confidence" SG_ 1297 RCM_a110_eventFrontRightSeatbelt 1;
BA_ "Confidence" SG_ 1297 RCM_a110_eventVehicleSpeed 1;
BA_ "Confidence" SG_ 1297 RCM_a110_eventSteeringAngle 1;
BA_ "Confidence" SG_ 1297 RCM_a110_eventDriverBrakeApply 1;
BA_ "GenSigSNA" SG_ 1297 RCM_a110_eventDriverBrakeApply "3";
BA_ "Confidence" SG_ 1297 RCM_a110_eventAccelPedalPos 1;
BA_ "GenSigSNA" SG_ 1297 RCM_a110_eventAccelPedalPos "255";
BA_ "Confidence" SG_ 1297 RCM_a112_eventArmStatus 1;
BA_ "Confidence" SG_ 1297 RCM_a112_eventFactoryMode 1;
BA_ "Confidence" SG_ 1297 RCM_a112_eventDiagEnabled 1;
BA_ "Confidence" SG_ 1297 RCM_a112_eventDriveOrientation 1;
BA_ "Confidence" SG_ 1297 RCM_a112_eventIDFsignal 1;
BA_ "Confidence" SG_ 1297 RCM_a112_eventFrontLeftSeatbelt 1;
BA_ "Confidence" SG_ 1297 RCM_a112_eventFrontRightSeatbelt 1;
BA_ "Confidence" SG_ 1297 RCM_a112_eventVehicleSpeed 1;
BA_ "Confidence" SG_ 1297 RCM_a112_eventSteeringAngle 1;
BA_ "Confidence" SG_ 1297 RCM_a112_eventDriverBrakeApply 1;
BA_ "GenSigSNA" SG_ 1297 RCM_a112_eventDriverBrakeApply "3";
BA_ "Confidence" SG_ 1297 RCM_a112_eventAccelPedalPos 1;
BA_ "GenSigSNA" SG_ 1297 RCM_a112_eventAccelPedalPos "255";
BA_ "Confidence" SG_ 1297 RCM_a113_eventArmStatus 1;
BA_ "Confidence" SG_ 1297 RCM_a113_eventFactoryMode 1;
BA_ "Confidence" SG_ 1297 RCM_a113_eventDiagEnabled 1;
BA_ "Confidence" SG_ 1297 RCM_a113_eventDriveOrientation 1;
BA_ "Confidence" SG_ 1297 RCM_a113_eventIDFsignal 1;
BA_ "Confidence" SG_ 1297 RCM_a113_eventFrontLeftSeatbelt 1;
BA_ "Confidence" SG_ 1297 RCM_a113_eventFrontRightSeatbelt 1;
BA_ "Confidence" SG_ 1297 RCM_a113_eventVehicleSpeed 1;
BA_ "Confidence" SG_ 1297 RCM_a113_eventSteeringAngle 1;
BA_ "Confidence" SG_ 1297 RCM_a113_eventDriverBrakeApply 1;
BA_ "GenSigSNA" SG_ 1297 RCM_a113_eventDriverBrakeApply "3";
BA_ "Confidence" SG_ 1297 RCM_a113_eventAccelPedalPos 1;
BA_ "GenSigSNA" SG_ 1297 RCM_a113_eventAccelPedalPos "255";
BA_ "Confidence" SG_ 1297 RCM_a114_eventArmStatus 1;
BA_ "Confidence" SG_ 1297 RCM_a114_eventFactoryMode 1;
BA_ "Confidence" SG_ 1297 RCM_a114_eventDiagEnabled 1;
BA_ "Confidence" SG_ 1297 RCM_a114_eventDriveOrientation 1;
BA_ "Confidence" SG_ 1297 RCM_a114_eventIDFsignal 1;
BA_ "Confidence" SG_ 1297 RCM_a114_eventFrontLeftSeatbelt 1;
BA_ "Confidence" SG_ 1297 RCM_a114_eventFrontRightSeatbelt 1;
BA_ "Confidence" SG_ 1297 RCM_a114_eventVehicleSpeed 1;
BA_ "Confidence" SG_ 1297 RCM_a114_eventSteeringAngle 1;
BA_ "Confidence" SG_ 1297 RCM_a114_eventDriverBrakeApply 1;
BA_ "GenSigSNA" SG_ 1297 RCM_a114_eventDriverBrakeApply "3";
BA_ "Confidence" SG_ 1297 RCM_a114_eventAccelPedalPos 1;
BA_ "GenSigSNA" SG_ 1297 RCM_a114_eventAccelPedalPos "255";
BA_ "Confidence" SG_ 1297 RCM_a115_eventArmStatus 1;
BA_ "Confidence" SG_ 1297 RCM_a115_eventFactoryMode 1;
BA_ "Confidence" SG_ 1297 RCM_a115_eventDiagEnabled 1;
BA_ "Confidence" SG_ 1297 RCM_a115_eventDriveOrientation 1;
BA_ "Confidence" SG_ 1297 RCM_a115_eventIDFsignal 1;
BA_ "Confidence" SG_ 1297 RCM_a115_eventFrontLeftSeatbelt 1;
BA_ "Confidence" SG_ 1297 RCM_a115_eventFrontRightSeatbelt 1;
BA_ "Confidence" SG_ 1297 RCM_a115_eventVehicleSpeed 1;
BA_ "Confidence" SG_ 1297 RCM_a115_eventSteeringAngle 1;
BA_ "Confidence" SG_ 1297 RCM_a115_eventDriverBrakeApply 1;
BA_ "GenSigSNA" SG_ 1297 RCM_a115_eventDriverBrakeApply "3";
BA_ "Confidence" SG_ 1297 RCM_a115_eventAccelPedalPos 1;
BA_ "GenSigSNA" SG_ 1297 RCM_a115_eventAccelPedalPos "255";
BA_ "Confidence" SG_ 1297 RCM_a116_eventArmStatus 1;
BA_ "Confidence" SG_ 1297 RCM_a116_eventFactoryMode 1;
BA_ "Confidence" SG_ 1297 RCM_a116_eventDiagEnabled 1;
BA_ "Confidence" SG_ 1297 RCM_a116_eventDriveOrientation 1;
BA_ "Confidence" SG_ 1297 RCM_a116_eventIDFsignal 1;
BA_ "Confidence" SG_ 1297 RCM_a116_eventFrontLeftSeatbelt 1;
BA_ "Confidence" SG_ 1297 RCM_a116_eventFrontRightSeatbelt 1;
BA_ "Confidence" SG_ 1297 RCM_a116_eventVehicleSpeed 1;
BA_ "Confidence" SG_ 1297 RCM_a116_eventSteeringAngle 1;
BA_ "Confidence" SG_ 1297 RCM_a116_eventDriverBrakeApply 1;
BA_ "GenSigSNA" SG_ 1297 RCM_a116_eventDriverBrakeApply "3";
BA_ "Confidence" SG_ 1297 RCM_a116_eventAccelPedalPos 1;
BA_ "GenSigSNA" SG_ 1297 RCM_a116_eventAccelPedalPos "255";
BA_ "Confidence" SG_ 1297 RCM_a117_eventArmStatus 1;
BA_ "Confidence" SG_ 1297 RCM_a117_eventFactoryMode 1;
BA_ "Confidence" SG_ 1297 RCM_a117_eventDiagEnabled 1;
BA_ "Confidence" SG_ 1297 RCM_a117_eventDriveOrientation 1;
BA_ "Confidence" SG_ 1297 RCM_a117_eventIDFsignal 1;
BA_ "Confidence" SG_ 1297 RCM_a117_eventFrontLeftSeatbelt 1;
BA_ "Confidence" SG_ 1297 RCM_a117_eventFrontRightSeatbelt 1;
BA_ "Confidence" SG_ 1297 RCM_a117_eventVehicleSpeed 1;
BA_ "Confidence" SG_ 1297 RCM_a117_eventSteeringAngle 1;
BA_ "Confidence" SG_ 1297 RCM_a117_eventDriverBrakeApply 1;
BA_ "GenSigSNA" SG_ 1297 RCM_a117_eventDriverBrakeApply "3";
BA_ "Confidence" SG_ 1297 RCM_a117_eventAccelPedalPos 1;
BA_ "GenSigSNA" SG_ 1297 RCM_a117_eventAccelPedalPos "255";
BA_ "Confidence" SG_ 1297 RCM_a118_eventArmStatus 1;
BA_ "Confidence" SG_ 1297 RCM_a118_eventFactoryMode 1;
BA_ "Confidence" SG_ 1297 RCM_a118_eventDiagEnabled 1;
BA_ "Confidence" SG_ 1297 RCM_a118_eventDriveOrientation 1;
BA_ "Confidence" SG_ 1297 RCM_a118_eventIDFsignal 1;
BA_ "Confidence" SG_ 1297 RCM_a118_eventFrontLeftSeatbelt 1;
BA_ "Confidence" SG_ 1297 RCM_a118_eventFrontRightSeatbelt 1;
BA_ "Confidence" SG_ 1297 RCM_a118_eventVehicleSpeed 1;
BA_ "Confidence" SG_ 1297 RCM_a118_eventSteeringAngle 1;
BA_ "Confidence" SG_ 1297 RCM_a118_eventDriverBrakeApply 1;
BA_ "GenSigSNA" SG_ 1297 RCM_a118_eventDriverBrakeApply "3";
BA_ "Confidence" SG_ 1297 RCM_a118_eventAccelPedalPos 1;
BA_ "GenSigSNA" SG_ 1297 RCM_a118_eventAccelPedalPos "255";
BA_ "Confidence" SG_ 881 RCM_matrixIndex 1;
BA_ "Confidence" SG_ 1471 RCU_alertID 1;
BA_ "Confidence" SG_ 1471 RCU_alertState 1;
BA_ "Confidence" SG_ 1471 RCU_a010_sensorPowerSupply 1;
BA_ "Confidence" SG_ 1471 RCU_a010_sensorHardware 1;
BA_ "Confidence" SG_ 1471 RCU_a010_sensorSignal 1;
BA_ "Confidence" SG_ 1471 RCU_a023_validityOnChassisBus 1;
BA_ "Confidence" SG_ 1471 RCU_a023_validityOnPartyBus 1;
BA_ "Confidence" SG_ 1471 RCU_a024_validityOnChassisBus 1;
BA_ "Confidence" SG_ 1471 RCU_a024_validityOnPartyBus 1;
BA_ "Confidence" SG_ 1471 RCU_a025_validityOnChassisBus 1;
BA_ "Confidence" SG_ 1471 RCU_a025_validityOnPartyBus 1;
BA_ "Confidence" SG_ 1471 RCU_a035_validityOnChassisBus 1;
BA_ "Confidence" SG_ 1471 RCU_a035_validityOnPartyBus 1;
BA_ "Confidence" SG_ 1471 RCU_a036_validityOnChassisBus 1;
BA_ "Confidence" SG_ 1471 RCU_a036_validityOnPartyBus 1;
BA_ "Confidence" SG_ 998 RCU_matrixIndex 1;
BA_ "SystemSignalLongSymbol" SG_ 998 RCU_a033_VCFRONTLVPowerStateChec "RCU_a033_VCFRONTLVPowerStateChecksum";
BA_ "SystemSignalLongSymbol" SG_ 998 RCU_a034_VCFRONTLVPowerStateCoun "RCU_a034_VCFRONTLVPowerStateCounter";
BA_ "SystemSignalLongSymbol" SG_ 998 RCU_a037_IDBinputRodStrokeInvali "RCU_a037_IDBinputRodStrokeInvalid";
BA_ "SystemSignalLongSymbol" SG_ 998 RCU_a043_VCFRONTiBoosterLvStateI "RCU_a043_VCFRONTiBoosterLvStateInvalid";
BA_ "SystemSignalLongSymbol" SG_ 998 RCU_a055_IDBsimulatorPressFaulte "RCU_a055_IDBsimulatorPressFaulted";
BA_ "SystemSignalLongSymbol" SG_ 998 RCU_a056_redundantControllerIsMa "RCU_a056_redundantControllerIsMaster";
BA_ "SystemSignalLongSymbol" SG_ 998 RCU_a058_DIbrakeTorqueCommandAnd "RCU_a058_DIbrakeTorqueCommandAndFlagMismatch";
BA_ "Confidence" SG_ 831 RCU_infoIndex 1;
BA_ "Confidence" SG_ 831 RCU_infoPcbaID 0;
BA_ "Confidence" SG_ 831 RCU_infoAssemblyID 0;
BA_ "Confidence" SG_ 831 RCU_infoUsageID 0;
BA_ "Confidence" SG_ 831 RCU_infoSubUsageID 0;
BA_ "Confidence" SG_ 1410 TCU_alertID 1;
BA_ "Confidence" SG_ 1410 TCU_alertState 1;
BA_ "Confidence" SG_ 1409 TCU_logMux 1;
BA_ "Confidence" SG_ 1409 TCU_cpuTemp 0;
BA_ "Confidence" SG_ 1409 TCU_cpuUsage 0;
BA_ "Confidence" SG_ 1409 TCU_mdmCoreTemperature 0;
BA_ "Confidence" SG_ 1409 TCU_availableMemory 0;
BA_ "Confidence" SG_ 1409 TCU_pwm 0;
BA_ "Confidence" SG_ 1409 TCU_pwmcap 0;
BA_ "Confidence" SG_ 1409 TCU_totalResumes 0;
BA_ "Confidence" SG_ 1409 TCU_mdmUplinkQueueSize 0;
BA_ "Confidence" SG_ 1409 TCU_mdmRSRP 0;
BA_ "Confidence" SG_ 1409 TCU_mdmSINR 0;
BA_ "Confidence" SG_ 1409 TCU_mdmUplinkAllowedRate 0;
BA_ "Confidence" SG_ 1409 TCU_mdmServiceState 0;
BA_ "Confidence" SG_ 1409 TCU_mdmIMSStatus 0;
BA_ "Confidence" SG_ 1409 TCU_mdmSIMStatus 0;
BA_ "Confidence" SG_ 1409 TCU_mdmBusyActive 0;
BA_ "GenSigSNA" SG_ 1409 TCU_mdmBusyActive "4294967295";
BA_ "Confidence" SG_ 1408 TCU_statusMux 1;
BA_ "Confidence" SG_ 1408 TCU_wakeUpReason 1;
BA_ "GenSigSNA" SG_ 1408 TCU_wakeUpReason "4294967295";
BA_ "Confidence" SG_ 1408 TCU_goingToSleep 1;
BA_ "GenSigSNA" SG_ 1408 TCU_goingToSleep "4294967295";
BA_ "Confidence" SG_ 1056 UIS_logMux 1;
BA_ "Confidence" SG_ 1056 UIS_wifiTemperature 0;
BA_ "Confidence" SG_ 1056 UIS_wifiStackState 0;
BA_ "Confidence" SG_ 1056 UIS_wifiStackReady 1;
BA_ "Confidence" SG_ 1056 UIS_wifiBars 0;
BA_ "Confidence" SG_ 1056 UIS_wifiAutoJoinLowRSSI 0;
BA_ "Confidence" SG_ 1056 UIS_valetMode 0;
BA_ "Confidence" SG_ 1056 UIS_uiQtCarUptime 0;
BA_ "Confidence" SG_ 1056 UIS_uiMeanFPS 0;
BA_ "Confidence" SG_ 1056 UIS_tunerVoltageOperation 0;
BA_ "Confidence" SG_ 1056 UIS_tunerVoltageAntenna2 0;
BA_ "Confidence" SG_ 1056 UIS_tunerVoltageAntenna1 0;
BA_ "Confidence" SG_ 1056 UIS_tunerCurrentAntenna2 0;
BA_ "Confidence" SG_ 1056 UIS_tunerCurrentAntenna1 0;
BA_ "Confidence" SG_ 1056 UIS_testDriveMode 1;
BA_ "Confidence" SG_ 1056 UIS_tegraModemManState 0;
BA_ "Confidence" SG_ 1056 UIS_systemWakeTime 0;
BA_ "Confidence" SG_ 1056 UIS_systemUptime 0;
BA_ "Confidence" SG_ 1056 UIS_suspensionGeofence 0;
BA_ "Confidence" SG_ 1056 UIS_superchargePaymentNeeded 0;
BA_ "Confidence" SG_ 1056 UIS_sleepType 0;
BA_ "Confidence" SG_ 1056 UIS_sleepTime 0;
BA_ "Confidence" SG_ 1056 UIS_sleepState 0;
BA_ "Confidence" SG_ 1056 UIS_slackerLoginResult 0;
BA_ "Confidence" SG_ 1056 UIS_settingsAutoTurnSignal 1;
BA_ "Confidence" SG_ 1056 UIS_sentryState 0;
BA_ "Confidence" SG_ 1056 UIS_sentryNeedsNap 0;
BA_ "Confidence" SG_ 1056 UIS_sentryIncidentCount 0;
BA_ "Confidence" SG_ 1056 UIS_scheduledChargingMode 0;
BA_ "Confidence" SG_ 1056 UIS_scheduleChargeStartTime 0;
BA_ "Confidence" SG_ 1056 UIS_scheduleChargeEndTime 0;
BA_ "Confidence" SG_ 1056 UIS_remoteRequestType 0;
BA_ "Confidence" SG_ 1056 UIS_rearDisplayUserPresent 0;
BA_ "Confidence" SG_ 1056 UIS_rearDisplayState 0;
BA_ "Confidence" SG_ 1056 UIS_powerManagerState 0;
BA_ "GenSigSNA" SG_ 1056 UIS_powerManagerState "18";
BA_ "Confidence" SG_ 1056 UIS_polytopiax8664MemUsage 0;
BA_ "Confidence" SG_ 1056 UIS_polytopiax8664CPUUsage 0;
BA_ "Confidence" SG_ 1056 UIS_odinStatusCmdResult 1;
BA_ "Confidence" SG_ 1056 UIS_odinProcessState 1;
BA_ "Confidence" SG_ 1056 UIS_odinListTasksCmdResult 1;
BA_ "Confidence" SG_ 1056 UIS_odinHrlUploadLimits 1;
BA_ "Confidence" SG_ 1056 UIS_odinHrlLogUploadState 1;
BA_ "Confidence" SG_ 1056 UIS_odinHermesConnectionState 1;
BA_ "Confidence" SG_ 1056 UIS_odinGatewayConnectionState 1;
BA_ "Confidence" SG_ 1056 UIS_odinFileSystemState 1;
BA_ "Confidence" SG_ 1056 UIS_odinEcuLogUploadState 1;
BA_ "Confidence" SG_ 1056 UIS_odinEcuLogForceTriggerUpload 1;
BA_ "SystemSignalLongSymbol" SG_ 1056 UIS_odinEcuLogForceTriggerUpload "UIS_odinEcuLogForceTriggerUploadState";
BA_ "Confidence" SG_ 1056 UIS_navAudioVolume 0;
BA_ "Confidence" SG_ 1056 UIS_muteNavVolume 0;
BA_ "Confidence" SG_ 1056 UIS_mounterdState 1;
BA_ "Confidence" SG_ 1056 UIS_modemECallppAvail 0;
BA_ "Confidence" SG_ 1056 UIS_modemBusyActive 0;
BA_ "Confidence" SG_ 1056 UIS_mirrorGeofenceActive 0;
BA_ "Confidence" SG_ 1056 UIS_mediaPlaybackStatus 0;
BA_ "Confidence" SG_ 1056 UIS_mediaNeedAuthToken 0;
BA_ "Confidence" SG_ 1056 UIS_inSuperchargerGeofence 0;
BA_ "Confidence" SG_ 1056 UIS_homelinkState 0;
BA_ "Confidence" SG_ 1056 UIS_headsetPairResult 0;
BA_ "Confidence" SG_ 1056 UIS_headsetConnectionState 0;
BA_ "Confidence" SG_ 1056 UIS_gpsmanagerMemUsage 0;
BA_ "Confidence" SG_ 1056 UIS_gpsmanagerCPUUsage 0;
BA_ "Confidence" SG_ 1056 UIS_firmwareReleaseScope 1;
BA_ "Confidence" SG_ 1056 UIS_featureSuperchargingEnabled 0;
BA_ "Confidence" SG_ 1056 UIS_embeddedGameState 1;
BA_ "Confidence" SG_ 1056 UIS_embeddedGameName 1;
BA_ "Confidence" SG_ 1056 UIS_dumTclipUploadState 1;
BA_ "SystemSignalLongSymbol" SG_ 1056 UIS_dumTclipSuccessfulUploadCoun "UIS_dumTclipSuccessfulUploadCount";
BA_ "Confidence" SG_ 1056 UIS_dmRearTouchDeviceExists 0;
BA_ "Confidence" SG_ 1056 UIS_dmRearPowerState 0;
BA_ "Confidence" SG_ 1056 UIS_dmRearLinkCheckOk 0;
BA_ "Confidence" SG_ 1056 UIS_dmRearEnabled 0;
BA_ "Confidence" SG_ 1056 UIS_dmRearConnected 0;
BA_ "Confidence" SG_ 1056 UIS_dmRearBacklightPowerLevel 1;
BA_ "Confidence" SG_ 1056 UIS_dmRearBacklightDutyCycle 0;
BA_ "Confidence" SG_ 1056 UIS_dmRearBacklightDevExists 0;
BA_ "Confidence" SG_ 1056 UIS_dmIcuPowerState 0;
BA_ "Confidence" SG_ 1056 UIS_dmIcuLinkCheckOk 0;
BA_ "Confidence" SG_ 1056 UIS_dmIcuEnabled 0;
BA_ "Confidence" SG_ 1056 UIS_dmIcuConnected 0;
BA_ "Confidence" SG_ 1056 UIS_dmIcuBacklightPowerLevel 1;
BA_ "Confidence" SG_ 1056 UIS_dmIcuBacklightDutyCycle 0;
BA_ "Confidence" SG_ 1056 UIS_dmIcuBacklightDevExists 0;
BA_ "Confidence" SG_ 1056 UIS_dmIcuAsilResumeFlag 1;
BA_ "Confidence" SG_ 1056 UIS_dmIcuAsilFirmwareStatus 1;
BA_ "Confidence" SG_ 1056 UIS_dmGatewayLinkWedged 0;
BA_ "Confidence" SG_ 1056 UIS_dmCenterTouchDeviceExists 0;
BA_ "Confidence" SG_ 1056 UIS_dmCenterSOsdExactCrcCheck 1;
BA_ "Confidence" SG_ 1056 UIS_dmCenterPowerState 0;
BA_ "Confidence" SG_ 1056 UIS_dmCenterOsdDisplayedState 0;
BA_ "Confidence" SG_ 1056 UIS_dmCenterOsdDayNightState 1;
BA_ "Confidence" SG_ 1056 UIS_dmCenterModeSettingStatus 1;
BA_ "Confidence" SG_ 1056 UIS_dmCenterMOsdExactCrcCheck 1;
BA_ "Confidence" SG_ 1056 UIS_dmCenterLinkCheckOk 0;
BA_ "Confidence" SG_ 1056 UIS_dmCenterEnabled 0;
BA_ "Confidence" SG_ 1056 UIS_dmCenterConnected 0;
BA_ "Confidence" SG_ 1056 UIS_dmCenterBacklightPowerLevel 0;
BA_ "Confidence" SG_ 1056 UIS_dmCenterBacklightDutyCycle 0;
BA_ "Confidence" SG_ 1056 UIS_dmCenterBacklightDevExists 0;
BA_ "Confidence" SG_ 1056 UIS_dmCenterAsilResumeFlag 1;
BA_ "Confidence" SG_ 1056 UIS_dmCenterAsilFirmwareStatus 1;
BA_ "Confidence" SG_ 1056 UIS_dgpuTemperature 0;
BA_ "Confidence" SG_ 1056 UIS_dashcamviewerMemUsage 0;
BA_ "Confidence" SG_ 1056 UIS_dashcamviewerCPUUsage 0;
BA_ "Confidence" SG_ 1056 UIS_dashcamStorageState 0;
BA_ "Confidence" SG_ 1056 UIS_dashcamStorageSentryMB 0;
BA_ "Confidence" SG_ 1056 UIS_dashcamStorageSavedMB 0;
BA_ "Confidence" SG_ 1056 UIS_dashcamStorageRecentMB 0;
BA_ "Confidence" SG_ 1056 UIS_dashcamStorageAvailableMB 0;
BA_ "Confidence" SG_ 1056 UIS_dashcamState 0;
BA_ "Confidence" SG_ 1056 UIS_cpuTemperature 0;
BA_ "SystemSignalLongSymbol" SG_ 1056 UIS_compositorRenderMinRenderTim "UIS_compositorRenderMinRenderTime";
BA_ "SystemSignalLongSymbol" SG_ 1056 UIS_compositorRenderMaxRenderTim "UIS_compositorRenderMaxRenderTime";
BA_ "SystemSignalLongSymbol" SG_ 1056 UIS_compositorRenderGpuPercentag "UIS_compositorRenderGpuPercentage";
BA_ "SystemSignalLongSymbol" SG_ 1056 UIS_compositorRenderAvgRenderTim "UIS_compositorRenderAvgRenderTime";
BA_ "Confidence" SG_ 1056 UIS_compositorFrameMonitorState 1;
BA_ "Confidence" SG_ 1056 UIS_clusterMemUsage 0;
BA_ "Confidence" SG_ 1056 UIS_clusterDisplayState 0;
BA_ "Confidence" SG_ 1056 UIS_clusterCPUUsage 0;
BA_ "Confidence" SG_ 1056 UIS_chargeOnSolarNoChargeReason 0;
BA_ "Confidence" SG_ 1056 UIS_centerDisplayState 0;
BA_ "Confidence" SG_ 1056 UIS_centerDisplayEvent 0;
BA_ "Confidence" SG_ 1056 UIS_cellularLinkManagerState 0;
BA_ "Confidence" SG_ 1056 UIS_carAssistState 0;
BA_ "Confidence" SG_ 1056 UIS_carAssistSessionCount 0;
BA_ "Confidence" SG_ 1056 UIS_carAssistErrorCode 0;
BA_ "Confidence" SG_ 1056 UIS_cameraRRepeaterStreamMissing 0;
BA_ "Confidence" SG_ 1056 UIS_cameraRRepeaterStream 1;
BA_ "Confidence" SG_ 1056 UIS_cameraRRepeaterPopup 0;
BA_ "Confidence" SG_ 1056 UIS_cameraRRepeaterPipeline 0;
BA_ "Confidence" SG_ 1056 UIS_cameraLRepeaterStreamMissing 0;
BA_ "Confidence" SG_ 1056 UIS_cameraLRepeaterStream 1;
BA_ "Confidence" SG_ 1056 UIS_cameraLRepeaterPopup 0;
BA_ "Confidence" SG_ 1056 UIS_cameraLRepeaterPipeline 0;
BA_ "Confidence" SG_ 1056 UIS_cameraFrontStreamMissing 1;
BA_ "Confidence" SG_ 1056 UIS_cameraFrontStream 1;
BA_ "Confidence" SG_ 1056 UIS_cameraFrontPopup 1;
BA_ "Confidence" SG_ 1056 UIS_cameraFrontPipeline 1;
BA_ "Confidence" SG_ 1056 UIS_cameraBackupStreamQuality 1;
BA_ "Confidence" SG_ 1056 UIS_cameraBackupStreamMissing 0;
BA_ "Confidence" SG_ 1056 UIS_cameraBackupStream 1;
BA_ "Confidence" SG_ 1056 UIS_cameraBackupPopup 0;
BA_ "Confidence" SG_ 1056 UIS_cameraBackupPipeline 0;
BA_ "Confidence" SG_ 1056 UIS_cameraBackupFramerate 0;
BA_ "Confidence" SG_ 1056 UIS_boardTemperature 0;
BA_ "Confidence" SG_ 1056 UIS_bluetoothStackState 0;
BA_ "Confidence" SG_ 1056 UIS_bluetoothStackRearState 0;
BA_ "Confidence" SG_ 1056 UIS_bluetoothPairResult 0;
BA_ "Confidence" SG_ 1056 UIS_bluetoothMemUsage 0;
BA_ "Confidence" SG_ 1056 UIS_bluetoothConnectionState 0;
BA_ "Confidence" SG_ 1056 UIS_bluetoothCPUUsage 0;
BA_ "Confidence" SG_ 1056 UIS_bluetoothAutoConnectionState 0;
BA_ "Confidence" SG_ 1056 UIS_backlightUserRequest 0;
BA_ "Confidence" SG_ 1056 UIS_audioVolumeLevel 0;
BA_ "Confidence" SG_ 1056 UIS_audioType 0;
BA_ "Confidence" SG_ 1056 UIS_audioState 0;
BA_ "Confidence" SG_ 1056 UIS_audioSource 0;
BA_ "Confidence" SG_ 1056 UIS_audioPWSGain 0;
BA_ "Confidence" SG_ 1056 UIS_audioMediaPlaying 0;
BA_ "Confidence" SG_ 1056 UIS_audioMediaBrowsing 0;
BA_ "Confidence" SG_ 1056 UIS_audioA2BRediscoveryCount 0;
BA_ "Confidence" SG_ 1056 UIS_activeAppView 0;
VAL_ 1297 RCM_a104_eventDriverBrakeApply 3 "Faulty_SNA" 2 "Driver_applying_brakes" 1 "Not_Applied" 0 "NotInit_orOff" ;
VAL_ 1297 RCM_a104_eventAccelPedalPos 255 "SNA" ;
VAL_ 1297 RCM_a105_eventArmStatus 1 "ARMED" 0 "UNARMED" ;
VAL_ 1297 RCM_a105_eventFactoryMode 1 "ENABLED" 0 "DISABLED" ;
VAL_ 1297 RCM_a105_eventDiagEnabled 1 "ENABLED" 0 "DISABLED" ;
VAL_ 1297 RCM_a105_eventDriveOrientation 1 "RIGHT_HAND_DRIVE" 0 "LEFT_HAND_DRIVE" ;
VAL_ 1297 RCM_a105_eventIDFsignal 1 "ACTIVE" 0 "NOT_ACTIVE" ;
VAL_ 1297 RCM_a105_eventFrontLeftSeatbelt 1 "LATCHED" 0 "UNLATCHED" ;
VAL_ 1297 RCM_a105_eventFrontRightSeatbelt 1 "LATCHED" 0 "UNLATCHED" ;
VAL_ 1297 RCM_a105_eventDriverBrakeApply 3 "Faulty_SNA" 2 "Driver_applying_brakes" 1 "Not_Applied" 0 "NotInit_orOff" ;
VAL_ 1297 RCM_a105_eventAccelPedalPos 255 "SNA" ;
VAL_ 1297 RCM_a106_eventArmStatus 1 "ARMED" 0 "UNARMED" ;
VAL_ 1297 RCM_a106_eventFactoryMode 1 "ENABLED" 0 "DISABLED" ;
VAL_ 1297 RCM_a106_eventDiagEnabled 1 "ENABLED" 0 "DISABLED" ;
VAL_ 1297 RCM_a106_eventDriveOrientation 1 "RIGHT_HAND_DRIVE" 0 "LEFT_HAND_DRIVE" ;
VAL_ 1297 RCM_a106_eventIDFsignal 1 "ACTIVE" 0 "NOT_ACTIVE" ;
VAL_ 1297 RCM_a106_eventFrontLeftSeatbelt 1 "LATCHED" 0 "UNLATCHED" ;
VAL_ 1297 RCM_a106_eventFrontRightSeatbelt 1 "LATCHED" 0 "UNLATCHED" ;
VAL_ 1297 RCM_a106_eventDriverBrakeApply 3 "Faulty_SNA" 2 "Driver_applying_brakes" 1 "Not_Applied" 0 "NotInit_orOff" ;
VAL_ 1297 RCM_a106_eventAccelPedalPos 255 "SNA" ;
VAL_ 1297 RCM_a107_eventArmStatus 1 "ARMED" 0 "UNARMED" ;
VAL_ 1297 RCM_a107_eventFactoryMode 1 "ENABLED" 0 "DISABLED" ;
VAL_ 1297 RCM_a107_eventDiagEnabled 1 "ENABLED" 0 "DISABLED" ;
VAL_ 1297 RCM_a107_eventDriveOrientation 1 "RIGHT_HAND_DRIVE" 0 "LEFT_HAND_DRIVE" ;
VAL_ 1297 RCM_a107_eventIDFsignal 1 "ACTIVE" 0 "NOT_ACTIVE" ;
VAL_ 1297 RCM_a107_eventFrontLeftSeatbelt 1 "LATCHED" 0 "UNLATCHED" ;
VAL_ 1297 RCM_a107_eventFrontRightSeatbelt 1 "LATCHED" 0 "UNLATCHED" ;
VAL_ 1297 RCM_a107_eventDriverBrakeApply 3 "Faulty_SNA" 2 "Driver_applying_brakes" 1 "Not_Applied" 0 "NotInit_orOff" ;
VAL_ 1297 RCM_a107_eventAccelPedalPos 255 "SNA" ;
VAL_ 1297 RCM_a108_eventArmStatus 1 "ARMED" 0 "UNARMED" ;
VAL_ 1297 RCM_a108_eventFactoryMode 1 "ENABLED" 0 "DISABLED" ;
VAL_ 1297 RCM_a108_eventDiagEnabled 1 "ENABLED" 0 "DISABLED" ;
VAL_ 1297 RCM_a108_eventDriveOrientation 1 "RIGHT_HAND_DRIVE" 0 "LEFT_HAND_DRIVE" ;
VAL_ 1297 RCM_a108_eventIDFsignal 1 "ACTIVE" 0 "NOT_ACTIVE" ;
VAL_ 1297 RCM_a108_eventFrontLeftSeatbelt 1 "LATCHED" 0 "UNLATCHED" ;
VAL_ 1297 RCM_a108_eventFrontRightSeatbelt 1 "LATCHED" 0 "UNLATCHED" ;
VAL_ 1297 RCM_a108_eventDriverBrakeApply 3 "Faulty_SNA" 2 "Driver_applying_brakes" 1 "Not_Applied" 0 "NotInit_orOff" ;
VAL_ 1297 RCM_a108_eventAccelPedalPos 255 "SNA" ;
VAL_ 1297 RCM_a109_eventArmStatus 1 "ARMED" 0 "UNARMED" ;
VAL_ 1297 RCM_a109_eventFactoryMode 1 "ENABLED" 0 "DISABLED" ;
VAL_ 1297 RCM_a109_eventDiagEnabled 1 "ENABLED" 0 "DISABLED" ;
VAL_ 1297 RCM_a109_eventDriveOrientation 1 "RIGHT_HAND_DRIVE" 0 "LEFT_HAND_DRIVE" ;
VAL_ 1297 RCM_a109_eventIDFsignal 1 "ACTIVE" 0 "NOT_ACTIVE" ;
VAL_ 1297 RCM_a109_eventFrontLeftSeatbelt 1 "LATCHED" 0 "UNLATCHED" ;
VAL_ 1297 RCM_a109_eventFrontRightSeatbelt 1 "LATCHED" 0 "UNLATCHED" ;
VAL_ 1297 RCM_a109_eventDriverBrakeApply 3 "Faulty_SNA" 2 "Driver_applying_brakes" 1 "Not_Applied" 0 "NotInit_orOff" ;
VAL_ 1297 RCM_a109_eventAccelPedalPos 255 "SNA" ;
VAL_ 1297 RCM_a110_eventArmStatus 1 "ARMED" 0 "UNARMED" ;
VAL_ 1297 RCM_a110_eventFactoryMode 1 "ENABLED" 0 "DISABLED" ;
VAL_ 1297 RCM_a110_eventDiagEnabled 1 "ENABLED" 0 "DISABLED" ;
VAL_ 1297 RCM_a110_eventDriveOrientation 1 "RIGHT_HAND_DRIVE" 0 "LEFT_HAND_DRIVE" ;
VAL_ 1297 RCM_a110_eventIDFsignal 1 "ACTIVE" 0 "NOT_ACTIVE" ;
VAL_ 1297 RCM_a110_eventFrontLeftSeatbelt 1 "LATCHED" 0 "UNLATCHED" ;
VAL_ 1297 RCM_a110_eventFrontRightSeatbelt 1 "LATCHED" 0 "UNLATCHED" ;
VAL_ 1297 RCM_a110_eventDriverBrakeApply 3 "Faulty_SNA" 2 "Driver_applying_brakes" 1 "Not_Applied" 0 "NotInit_orOff" ;
VAL_ 1297 RCM_a110_eventAccelPedalPos 255 "SNA" ;
VAL_ 1297 RCM_a112_eventArmStatus 1 "ARMED" 0 "UNARMED" ;
VAL_ 1297 RCM_a112_eventFactoryMode 1 "ENABLED" 0 "DISABLED" ;
VAL_ 1297 RCM_a112_eventDiagEnabled 1 "ENABLED" 0 "DISABLED" ;
VAL_ 1297 RCM_a112_eventDriveOrientation 1 "RIGHT_HAND_DRIVE" 0 "LEFT_HAND_DRIVE" ;
VAL_ 1297 RCM_a112_eventIDFsignal 1 "ACTIVE" 0 "NOT_ACTIVE" ;
VAL_ 1297 RCM_a112_eventFrontLeftSeatbelt 1 "LATCHED" 0 "UNLATCHED" ;
VAL_ 1297 RCM_a112_eventFrontRightSeatbelt 1 "LATCHED" 0 "UNLATCHED" ;
VAL_ 1297 RCM_a112_eventDriverBrakeApply 3 "Faulty_SNA" 2 "Driver_applying_brakes" 1 "Not_Applied" 0 "NotInit_orOff" ;
VAL_ 1297 RCM_a112_eventAccelPedalPos 255 "SNA" ;
VAL_ 1297 RCM_a113_eventArmStatus 1 "ARMED" 0 "UNARMED" ;
VAL_ 1297 RCM_a113_eventFactoryMode 1 "ENABLED" 0 "DISABLED" ;
VAL_ 1297 RCM_a113_eventDiagEnabled 1 "ENABLED" 0 "DISABLED" ;
VAL_ 1297 RCM_a113_eventDriveOrientation 1 "RIGHT_HAND_DRIVE" 0 "LEFT_HAND_DRIVE" ;
VAL_ 1297 RCM_a113_eventIDFsignal 1 "ACTIVE" 0 "NOT_ACTIVE" ;
VAL_ 1297 RCM_a113_eventFrontLeftSeatbelt 1 "LATCHED" 0 "UNLATCHED" ;
VAL_ 1297 RCM_a113_eventFrontRightSeatbelt 1 "LATCHED" 0 "UNLATCHED" ;
VAL_ 1297 RCM_a113_eventDriverBrakeApply 3 "Faulty_SNA" 2 "Driver_applying_brakes" 1 "Not_Applied" 0 "NotInit_orOff" ;
VAL_ 1297 RCM_a113_eventAccelPedalPos 255 "SNA" ;
VAL_ 1297 RCM_a114_eventArmStatus 1 "ARMED" 0 "UNARMED" ;
VAL_ 1297 RCM_a114_eventFactoryMode 1 "ENABLED" 0 "DISABLED" ;
VAL_ 1297 RCM_a114_eventDiagEnabled 1 "ENABLED" 0 "DISABLED" ;
VAL_ 1297 RCM_a114_eventDriveOrientation 1 "RIGHT_HAND_DRIVE" 0 "LEFT_HAND_DRIVE" ;
VAL_ 1297 RCM_a114_eventIDFsignal 1 "ACTIVE" 0 "NOT_ACTIVE" ;
VAL_ 1297 RCM_a114_eventFrontLeftSeatbelt 1 "LATCHED" 0 "UNLATCHED" ;
VAL_ 1297 RCM_a114_eventFrontRightSeatbelt 1 "LATCHED" 0 "UNLATCHED" ;
VAL_ 1297 RCM_a114_eventDriverBrakeApply 3 "Faulty_SNA" 2 "Driver_applying_brakes" 1 "Not_Applied" 0 "NotInit_orOff" ;
VAL_ 1297 RCM_a114_eventAccelPedalPos 255 "SNA" ;
VAL_ 1297 RCM_a115_eventArmStatus 1 "ARMED" 0 "UNARMED" ;
VAL_ 1297 RCM_a115_eventFactoryMode 1 "ENABLED" 0 "DISABLED" ;
VAL_ 1297 RCM_a115_eventDiagEnabled 1 "ENABLED" 0 "DISABLED" ;
VAL_ 1297 RCM_a115_eventDriveOrientation 1 "RIGHT_HAND_DRIVE" 0 "LEFT_HAND_DRIVE" ;
VAL_ 1297 RCM_a115_eventIDFsignal 1 "ACTIVE" 0 "NOT_ACTIVE" ;
VAL_ 1297 RCM_a115_eventFrontLeftSeatbelt 1 "LATCHED" 0 "UNLATCHED" ;
VAL_ 1297 RCM_a115_eventFrontRightSeatbelt 1 "LATCHED" 0 "UNLATCHED" ;
VAL_ 1297 RCM_a115_eventDriverBrakeApply 3 "Faulty_SNA" 2 "Driver_applying_brakes" 1 "Not_Applied" 0 "NotInit_orOff" ;
VAL_ 1297 RCM_a115_eventAccelPedalPos 255 "SNA" ;
VAL_ 1297 RCM_a116_eventArmStatus 1 "ARMED" 0 "UNARMED" ;
VAL_ 1297 RCM_a116_eventFactoryMode 1 "ENABLED" 0 "DISABLED" ;
VAL_ 1297 RCM_a116_eventDiagEnabled 1 "ENABLED" 0 "DISABLED" ;
VAL_ 1297 RCM_a116_eventDriveOrientation 1 "RIGHT_HAND_DRIVE" 0 "LEFT_HAND_DRIVE" ;
VAL_ 1297 RCM_a116_eventIDFsignal 1 "ACTIVE" 0 "NOT_ACTIVE" ;
VAL_ 1297 RCM_a116_eventFrontLeftSeatbelt 1 "LATCHED" 0 "UNLATCHED" ;
VAL_ 1297 RCM_a116_eventFrontRightSeatbelt 1 "LATCHED" 0 "UNLATCHED" ;
VAL_ 1297 RCM_a116_eventDriverBrakeApply 3 "Faulty_SNA" 2 "Driver_applying_brakes" 1 "Not_Applied" 0 "NotInit_orOff" ;
VAL_ 1297 RCM_a116_eventAccelPedalPos 255 "SNA" ;
VAL_ 1297 RCM_a117_eventArmStatus 1 "ARMED" 0 "UNARMED" ;
VAL_ 1297 RCM_a117_eventFactoryMode 1 "ENABLED" 0 "DISABLED" ;
VAL_ 1297 RCM_a117_eventDiagEnabled 1 "ENABLED" 0 "DISABLED" ;
VAL_ 1297 RCM_a117_eventDriveOrientation 1 "RIGHT_HAND_DRIVE" 0 "LEFT_HAND_DRIVE" ;
VAL_ 1297 RCM_a117_eventIDFsignal 1 "ACTIVE" 0 "NOT_ACTIVE" ;
VAL_ 1297 RCM_a117_eventFrontLeftSeatbelt 1 "LATCHED" 0 "UNLATCHED" ;
VAL_ 1297 RCM_a117_eventFrontRightSeatbelt 1 "LATCHED" 0 "UNLATCHED" ;
VAL_ 1297 RCM_a117_eventDriverBrakeApply 3 "Faulty_SNA" 2 "Driver_applying_brakes" 1 "Not_Applied" 0 "NotInit_orOff" ;
VAL_ 1297 RCM_a117_eventAccelPedalPos 255 "SNA" ;
VAL_ 1297 RCM_a118_eventArmStatus 1 "ARMED" 0 "UNARMED" ;
VAL_ 1297 RCM_a118_eventFactoryMode 1 "ENABLED" 0 "DISABLED" ;
VAL_ 1297 RCM_a118_eventDiagEnabled 1 "ENABLED" 0 "DISABLED" ;
VAL_ 1297 RCM_a118_eventDriveOrientation 1 "RIGHT_HAND_DRIVE" 0 "LEFT_HAND_DRIVE" ;
VAL_ 1297 RCM_a118_eventIDFsignal 1 "ACTIVE" 0 "NOT_ACTIVE" ;
VAL_ 1297 RCM_a118_eventFrontLeftSeatbelt 1 "LATCHED" 0 "UNLATCHED" ;
VAL_ 1297 RCM_a118_eventFrontRightSeatbelt 1 "LATCHED" 0 "UNLATCHED" ;
VAL_ 1297 RCM_a118_eventDriverBrakeApply 3 "Faulty_SNA" 2 "Driver_applying_brakes" 1 "Not_Applied" 0 "NotInit_orOff" ;
VAL_ 1297 RCM_a118_eventAccelPedalPos 255 "SNA" ;
VAL_ 881 RCM_matrixIndex 1 "AlertMatrix1" 0 "AlertMatrix0" ;
VAL_ 1471 RCU_alertID 58 "a058_DIbrakeTorqueCommandAndFlagMismatch" 57 "a057_PMebrCmdStateInvalid" 56 "a056_redundantControllerIsMaster" 55 "a055_IDBsimulatorPressFaulted" 54 "a054_IDBcircuitPressFaulted" 53 "a053_ESPwheelSpeedsChecksum" 52 "a052_ESPwheelSpeedsCounter" 51 "a051_ESPReRWSSLInvalid" 50 "a050_ESPReLWSSLInvalid" 49 "a049_ESPFrRWSSLInvalid" 48 "a048_ESPFrLWSSLInvalid" 47 "a047_ESPwheelSpeedsDLC" 46 "a046_brakeFluidLevelSNA" 45 "a045_VCFRONTtempInvalid" 44 "a044_VCFRONTsensorsMIA" 43 "a043_VCFRONTiBoosterLvStateInvalid" 42 "a042_DIsystemStatusChecksum" 41 "a041_DIsystemStatusCounter" 40 "a040_DIgearInvalid" 39 "a039_DIaccelPosInvalid" 38 "a038_DIsystemStatusDLC" 37 "a037_IDBinputRodStrokeInvalid" 36 "a036_IDBpspInvalid" 35 "a035_IDBpcpInvalid" 34 "a034_VCFRONTLVPowerStateCounter" 33 "a033_VCFRONTLVPowerStateChecksum" 32 "a032_VCFRONTLVPowerStateDLC" 31 "a031_PMstate2Counter" 30 "a030_PMstate2Checksum" 29 "a029_PMstate2DLC" 28 "a028_DIchassisControlCounter" 27 "a027_DIchassisCtrlChecksum" 26 "a026_DIchassisControlDLC" 25 "a025_IDBstatusCounter" 24 "a024_IDBstatusChecksum" 23 "a023_IDBstatusDLC" 22 "a022_BBstatusCounter" 21 "a021_BBstatusChecksum" 20 "a020_BBstatusDLC" 19 "a019_DItorquePathActive" 18 "a018_DItorquePathFaulted" 17 "a017_chassisBusOff" 16 "a016_partyBusOff" 15 "a015_fluidLeakDetected" 14 "a014_asicTempHigh" 13 "a013_mcuGenericFault" 12 "a012_pedalSensorNotCal" 11 "a011_idbPedalTravelMismatch" 10 "a010_pedalSensorFault" 9 "a009_brakeFluidLow" 8 "a008_pressureNotCalibrated" 7 "a007_pressureSensorFault" 6 "a006_wakeLineOpen" 5 "a005_supplyUndervoltage" 4 "a004_supplyOvervoltage" 3 "a003_pumpMotorFault" 2 "a002_solenoidValveFault" 1 "a001_valveDriverFault" 0 "ALERT_DO_NOT_USE_ZERO" ;
VAL_ 1471 RCU_alertState 1 "SET" 0 "CLEARED" ;
VAL_ 1471 RCU_a010_sensorPowerSupply 1 "NOT_OK" 0 "OK" ;
VAL_ 1471 RCU_a010_sensorHardware 1 "NOT_OK" 0 "OK" ;
VAL_ 1471 RCU_a010_sensorSignal 1 "NOT_OK" 0 "OK" ;
VAL_ 1471 RCU_a023_validityOnChassisBus 1 "NOT_OK" 0 "OK" ;
VAL_ 1471 RCU_a023_validityOnPartyBus 1 "NOT_OK" 0 "OK" ;
VAL_ 1471 RCU_a024_validityOnChassisBus 1 "NOT_OK" 0 "OK" ;
VAL_ 1471 RCU_a024_validityOnPartyBus 1 "NOT_OK" 0 "OK" ;
VAL_ 1471 RCU_a025_validityOnChassisBus 1 "NOT_OK" 0 "OK" ;
VAL_ 1471 RCU_a025_validityOnPartyBus 1 "NOT_OK" 0 "OK" ;
VAL_ 1471 RCU_a035_validityOnChassisBus 1 "NOT_OK" 0 "OK" ;
VAL_ 1471 RCU_a035_validityOnPartyBus 1 "NOT_OK" 0 "OK" ;
VAL_ 1471 RCU_a036_validityOnChassisBus 1 "NOT_OK" 0 "OK" ;
VAL_ 1471 RCU_a036_validityOnPartyBus 1 "NOT_OK" 0 "OK" ;
VAL_ 998 RCU_matrixIndex 0 "RCU_AlertMatrix0" ;
VAL_ 831 RCU_infoIndex 255 "END" 31 "SUBCOMPONENT_GITHASH" 30 "PACKAGE_SN_8_14" 29 "PACKAGE_SN_1_7" 27 "PACKAGE_PN_15_20" 26 "PACKAGE_PN_8_14" 25 "PACKAGE_PN_1_7" 23 "SUBCOMPONENT2" 22 "VARIANTCRC" 20 "UDS_PROTOCOL_BOOTCRC" 19 "VERSION_DEPRECATED" 18 "BOOTLOADER_GITHASH" 17 "APP_GITHASH" 16 "SUBCOMPONENT" 15 "BOOTLOADER_CRC" 14 "BOOTLOADER_SVN" 13 "APP_CRC" 11 "PCBAID_ASSYID_USAGEID" 10 "BUILD_HWID_COMPONENTID" 9 "DEPRECATED_9" 8 "DEPRECATED_8" 7 "DEPRECATED_7" 6 "DEPRECATED_6" 5 "DEPRECATED_5" 4 "DEPRECATED_4" 3 "DEPRECATED_3" 2 "DEPRECATED_2" 1 "DEPRECATED_1" 0 "DEPRECATED_0" ;
VAL_ 1410 TCU_alertID 6 "w006_MpssUnavailable" 5 "w005_SIMSlotError" 4 "w004_MSDTransmissionFailed" 3 "w003_ECallFailed" 2 "w002_CellRegRejected" 1 "w001_IMSRegistrationFailed" 0 "ALERT_DO_NOT_USE_ZERO" ;
VAL_ 1410 TCU_alertState 1 "SET" 0 "CLEARED" ;
VAL_ 1409 TCU_logMux 15 "mdmBusyActive" 14 "mdmSIMStatus" 13 "mdmIMSStatus" 12 "mdmServiceState" 11 "mdmUplinkAvgRage" 10 "mdmUplinkAllowedRate" 9 "mdmSINR" 8 "mdmRSRP" 7 "mdmUplinkQueueSize" 6 "totalResumes" 5 "pwmcap" 4 "pwm" 3 "availableMemory" 2 "mdmCoreTemperature" 1 "cpuUsage" 0 "cpuTemp" ;
VAL_ 1409 TCU_mdmBusyActive 4294967295 "SNA" ;
VAL_ 1408 TCU_statusMux 2 "goingToSleep" 1 "tcuCmdId" 0 "wakeUpReason" ;
VAL_ 1408 TCU_wakeUpReason 4294967295 "SNA" ;
VAL_ 1408 TCU_goingToSleep 4294967295 "SNA" ;
VAL_ 1056 UIS_logMux 354 "activeAppView" 353 "amdSocPkgPower" 352 "audioA2BRediscoveryCount" 351 "audioMediaBrowsing" 350 "audioMediaPlaying" 349 "audioPWSGain" 348 "audioSource" 347 "audioState" 346 "audioType" 345 "audioVolumeLevel" 344 "backlightUserRequest" 343 "bifrostCPUUsage" 342 "bifrostMemUsage" 341 "bifrostOdinEngineRequests" 340 "bifrostOdinEngineUp" 339 "bluetoothAutoConnectionState" 338 "bluetoothCPUUsage" 337 "bluetoothConnectionState" 336 "bluetoothMemUsage" 335 "bluetoothPairResult" 334 "bluetoothStackRearState" 333 "bluetoothStackState" 332 "boardTemperature" 331 "bootCount" 330 "camBackupDecodeAvgFrametime" 329 "camBackupDecodeFramecount" 328 "camBackupDecodeMaxFrametime" 327 "camBackupDecodeMinFrametime" 326 "cameraBackupFramerate" 325 "cameraBackupLateFrames" 324 "cameraBackupMaxFrametime" 323 "cameraBackupPipeline" 322 "cameraBackupPopup" 321 "cameraBackupStream" 320 "cameraBackupStreamMissing" 319 "cameraBackupStreamQuality" 318 "cameraFrontPipeline" 317 "cameraFrontPopup" 316 "cameraFrontStream" 315 "cameraFrontStreamMissing" 314 "cameraLRepeaterFramerate" 313 "cameraLRepeaterLateFrames" 312 "cameraLRepeaterMaxFrametime" 311 "cameraLRepeaterPipeline" 310 "cameraLRepeaterPopup" 309 "cameraLRepeaterStream" 308 "cameraLRepeaterStreamMissing" 307 "cameraRRepeaterFramerate" 306 "cameraRRepeaterLateFrames" 305 "cameraRRepeaterMaxFrametime" 304 "cameraRRepeaterPipeline" 303 "cameraRRepeaterPopup" 302 "cameraRRepeaterStream" 301 "cameraRRepeaterStreamMissing" 300 "carAssistErrorCode" 299 "carAssistSessionCount" 298 "carAssistState" 297 "cellularLinkManagerState" 296 "centerDispAsilA_lsb" 295 "centerDispAsilA_msb" 294 "centerDispAsilB_lsb" 293 "centerDispAsilB_msb" 292 "centerDisplayEvent" 291 "centerDisplayState" 290 "ceruleanx8664CPUUsage" 289 "ceruleanx8664MemUsage" 288 "chargeOnSolarNoChargeReason" 287 "chromiumadapterCPUUsage" 286 "chromiumadapterMemUsage" 285 "clusterCPUUsage" 284 "clusterDisplayState" 283 "clusterFramesOver100Ms" 282 "clusterFramesOver200Ms" 281 "clusterMaxFrametime" 280 "clusterMeanFPS" 279 "clusterMemUsage" 278 "cobaltlinuxCPUUsage" 277 "cobaltlinuxMemUsage" 276 "compositorFrameMonitorState" 275 "compositorRenderAvgRenderTime" 274 "compositorRenderFrameCount" 273 "compositorRenderFrameRate" 272 "compositorRenderGpuPercentage" 271 "compositorRenderMaxFrameTime" 270 "compositorRenderMaxRenderTime" 269 "compositorRenderMinFrameTime" 268 "compositorRenderMinRenderTime" 267 "cpuTemperature" 266 "dashcamOnboardAvailableMB" 265 "dashcamOnboardMB" 264 "dashcamOnboardSavePressCount" 263 "dashcamOnboardTransferCount" 262 "dashcamSavedToOnboardCount" 261 "dashcamSavedToSavedCount" 260 "dashcamSavedToSentryCount" 259 "dashcamState" 258 "dashcamStorageAvailableMB" 257 "dashcamStorageRecentMB" 256 "dashcamStorageSavedMB" 255 "dashcamStorageSentryMB" 254 "dashcamStorageState" 253 "dashcamTransferCount" 252 "dashcamTransferFileCount" 251 "dashcamTransferRateMBps" 250 "dashcamTransferSizeMB" 249 "dashcamTransferTimeMs" 248 "dashcamviewerCPUUsage" 247 "dashcamviewerMemUsage" 246 "developerMode" 245 "dgpuTemperature" 244 "dmCenterAsilFirmwareStatus" 243 "dmCenterAsilOpenFlag" 242 "dmCenterAsilResumeFlag" 241 "dmCenterAsilShortFlag" 240 "dmCenterBacklightDevExists" 239 "dmCenterBacklightDutyCycle" 238 "dmCenterBacklightFault" 237 "dmCenterBacklightNits" 236 "dmCenterBacklightPowerLevel" 235 "dmCenterConnected" 234 "dmCenterEnabled" 233 "dmCenterLinkCheckOk" 232 "dmCenterMOsdExactCrcCheck" 231 "dmCenterMOsdVideoCrcData" 230 "dmCenterModeSettingStatus" 229 "dmCenterOsdDayNightState" 228 "dmCenterOsdDisplayedState" 227 "dmCenterPowerState" 226 "dmCenterSOsdExactCrcCheck" 225 "dmCenterSOsdVideoCrcData" 224 "dmCenterTouchDeviceExists" 223 "dmCenterTouchIrqCount" 222 "dmGatewayLinkWedged" 221 "dmIcuAsilFirmwareStatus" 220 "dmIcuAsilOpenFlag" 219 "dmIcuAsilResumeFlag" 218 "dmIcuAsilShortFlag" 217 "dmIcuBacklightDevExists" 216 "dmIcuBacklightDutyCycle" 215 "dmIcuBacklightFault" 214 "dmIcuBacklightNits" 213 "dmIcuBacklightPowerLevel" 212 "dmIcuConnected" 211 "dmIcuEnabled" 210 "dmIcuLinkCheckOk" 209 "dmIcuPowerState" 208 "dmIcuTouchIrqCount" 207 "dmRearAsilStatusLsb" 206 "dmRearAsilStatusMsb" 205 "dmRearBacklightDevExists" 204 "dmRearBacklightDutyCycle" 203 "dmRearBacklightFault" 202 "dmRearBacklightNits" 201 "dmRearBacklightPowerLevel" 200 "dmRearConnected" 199 "dmRearEnabled" 198 "dmRearLinkCheckOk" 197 "dmRearPowerState" 196 "dmRearTouchDeviceExists" 195 "dumTclipClipCount" 194 "dumTclipSuccessfulUploadCount" 193 "dumTclipTransferCount" 192 "dumTclipUploadActive" 191 "dumTclipUploadState" 190 "embeddedGameName" 189 "embeddedGameState" 188 "estimatedOccupancyCount" 187 "featureSuperchargingEnabled" 186 "firmwareReleaseScope" 185 "godotCPUUsage" 184 "godotMemUsage" 183 "godot_MEMORY_DYNAMIC" 182 "godot_MEMORY_STATIC" 181 "godot_TIME_FPS" 180 "godot_TIME_PROCESS" 179 "gpsmanagerCPUUsage" 178 "gpsmanagerMemUsage" 177 "gtwSocUartRxStatBadChecksum" 176 "gtwSocUartRxStatBadTooBig" 175 "gtwSocUartRxStatBadTooSmall" 174 "gtwSocUartRxStatHandleErr" 173 "gtwSocUartRxStatHeartbeats" 172 "gtwSocUartRxStatMsgErr" 171 "gtwSocUartRxStatUnhandled" 170 "gtwSocUartRxStatValidPackets" 169 "gtwSocUartTxStatAnsMismatch" 168 "gtwSocUartTxStatBadTooBig" 167 "gtwSocUartTxStatNacks" 166 "gtwSocUartTxStatPackets" 165 "gtwSocUartTxStatTimeouts" 164 "headsetConnectionState" 163 "headsetPairResult" 162 "hermesclientCPUUsage" 161 "hermesclientMemUsage" 160 "hermesdynamicCPUUsage" 159 "hermesdynamicMemUsage" 158 "homelinkState" 157 "igpuTemperature" 156 "inSuperchargerGeofence" 155 "limex8664CPUUsage" 154 "limex8664MemUsage" 153 "mediaImageCacheCost" 152 "mediaImageCacheSize" 151 "mediaNeedAuthToken" 150 "mediaPlaybackStatus" 149 "mediaserveCPUUsage" 148 "mediaserveMemUsage" 147 "mirrorGeofenceActive" 146 "modemBusyActive" 145 "modemECallppAvail" 144 "mounterdDashcamCapacityGB" 143 "mounterdDeviceCount" 142 "mounterdEncryptionCapacityGB" 141 "mounterdFilesystemCountExfat" 140 "mounterdFilesystemCountExt3" 139 "mounterdFilesystemCountExt4" 138 "mounterdFilesystemCountFat32" 137 "mounterdFrontHubConnected" 136 "mounterdFrontHubDisconnected" 135 "mounterdMountCountTotal" 134 "mounterdState" 133 "muteNavVolume" 132 "navAudioVolume" 131 "nuanceserverCPUUsage" 130 "nuanceserverMemUsage" 129 "numCorrMemErrorsECC" 128 "numUncorrMemErrorsECC" 127 "nvmeDataUnitsWritten100mb" 126 "nvmePercentLifetimeUsed" 125 "nvmeTemperature" 124 "odinAuthCount" 123 "odinAuthFailCount" 122 "odinCPUUsage" 121 "odinEcuLogForceTriggerUploadState" 120 "odinEcuLogUploadState" 119 "odinFileSystemState" 118 "odinGatewayConnectionState" 117 "odinHermesConnectionState" 116 "odinHrlLogUploadState" 115 "odinHrlUploadLimits" 114 "odinListTasksCmdDurationMs" 113 "odinListTasksCmdResult" 112 "odinMemUsage" 111 "odinNetworkFailCount" 110 "odinNetworkStartCount" 109 "odinOrchestratorFailCount" 108 "odinOrchestratorStartCount" 107 "odinProcessState" 106 "odinStatusCmdDurationMs" 105 "odinStatusCmdResult" 104 "odincefCPUUsage" 103 "odincefMemUsage" 102 "polytopiax8664CPUUsage" 101 "polytopiax8664MemUsage" 100 "powerManagerState" 99 "psiCpuSome" 98 "psiIOFull" 97 "psiIOSome" 96 "psiMemFull" 95 "psiMemSome" 94 "qtcarCPUUsage" 93 "qtcarMemUsage" 92 "radioserveCPUUsage" 91 "radioserveMemUsage" 90 "rearDisplayState" 89 "rearDisplayUserPresent" 88 "releasenotesCPUUsage" 87 "releasenotesMemUsage" 86 "remoteRequestType" 85 "scheduleChargeEndTime" 84 "scheduleChargeStartTime" 83 "scheduledChargingMode" 82 "sentryIncidentCount" 81 "sentryNeedsNap" 80 "sentryState" 79 "serverCPUUsage" 78 "serverMemUsage" 77 "serviceMode" 76 "serviceModePlus" 75 "settingsAutoTurnSignal" 74 "slackerLoginResult" 73 "sleepCount" 72 "sleepState" 71 "sleepTime" 70 "sleepType" 69 "solitaireCPUUsage" 68 "solitaireMemUsage" 67 "speechrecoCPUUsage" 66 "speechrecoMemUsage" 65 "spotifyserverCPUUsage" 64 "spotifyserverMemUsage" 63 "sudokuCPUUsage" 62 "sudokuMemUsage" 61 "superchargePaymentNeeded" 60 "suspensionGeofence" 59 "systemMemSwapUsage" 58 "systemUptime" 57 "systemWakeTime" 56 "tegraModemManState" 55 "teslaMediaCacheCost" 54 "teslaMediaCacheSize" 53 "teslacefgpuCPUUsage" 52 "teslacefgpuMemUsage" 51 "teslacefzygotCPUUsage" 50 "teslacefzygotMemUsage" 49 "teslachromiumCPUUsage" 48 "teslachromiumMemUsage" 47 "testDriveMode" 46 "tmserverCPUUsage" 45 "tmserverMemUsage" 44 "touchEventsAggCount" 43 "tunerCurrentAntenna1" 42 "tunerCurrentAntenna2" 41 "tunerTemperatureCelsius" 40 "tunerTemperatureFahrenheit" 39 "tunerVoltage1V8" 38 "tunerVoltage3V3" 37 "tunerVoltageAntenna1" 36 "tunerVoltageAntenna2" 35 "tunerVoltageMQS" 34 "tunerVoltageOperation" 33 "tunerVoltageUBatt" 32 "uiFramesOver100Ms" 31 "uiFramesOver200Ms" 30 "uiMaxFrametime" 29 "uiMeanFPS" 28 "uiQtCarSwapUsage" 27 "uiQtCarUptime" 26 "valetMode" 25 "valhallaserverCPUUsage" 24 "valhallaserverMemUsage" 23 "vehicleCPUUsage" 22 "vehicleMemUsage" 21 "videodCPUUsage" 20 "videodMemUsage" 19 "vmtouchCPUUsage" 18 "vmtouchMemUsage" 17 "webbrowserCPUUsage" 16 "webbrowserMemUsage" 15 "wifiAutoJoinLowRSSI" 14 "wifiBars" 13 "wifiStackReady" 12 "wifiStackState" 11 "wifiTemperature" 10 "zramCompressedSize" 9 "zramCompressionRatio" 8 "zramFailedReads" 7 "zramFailedWrites" 6 "zramInvalidIO" 5 "zramNotifyFree" 4 "zramOriginalSize" 3 "zramReadIO" 2 "zramReadTicks" 1 "zramWriteIO" 0 "zramWriteTicks" ;
VAL_ 1056 UIS_wifiStackState 17 "WL_RESET_CONNMAN" 16 "WL_RUNNING_LOCAL" 15 "WL_CAPTIVE" 14 "WL_DISCONNECTING" 13 "WL_RUNNING" 12 "WL_WAITING_ONLINE" 11 "WL_CHECKING" 10 "WL_CONFIGURING" 9 "WL_CONNECTING" 8 "WL_SELECTING_NETWORK" 7 "WL_WAITING_AUTOCONNECT" 6 "WL_SEARCHING" 5 "WL_POWERING_ON" 4 "WL_DISABLED_WAIT" 3 "WL_POWERING_OFF" 2 "WL_WAITING_TECHNOLOGY" 1 "WL_RESETTING" 0 "DEFAULT" ;
VAL_ 1056 UIS_wifiStackReady 1 "TRUE" 0 "FALSE" ;
VAL_ 1056 UIS_wifiAutoJoinLowRSSI 1 "TRUE" 0 "FALSE" ;
VAL_ 1056 UIS_valetMode 1 "TRUE" 0 "FALSE" ;
VAL_ 1056 UIS_testDriveMode 1 "ENABLED" 0 "DISABLED" ;
VAL_ 1056 UIS_tegraModemManState 20 "INVALID" 19 "CHECKINGMODEM" 18 "CHECKINGPORTS" 17 "STOPPINGLINK" 16 "UNCONFIGURINGLINK" 15 "RUNNINGSTATUS" 14 "RUNNING" 13 "CHECKINGLINK" 12 "CONFIGURINGLINK" 11 "RETRYINGLINK" 10 "STARTINLINK" 9 "PRECONDITIONINGLINK" 8 "INITIALIZING2" 7 "CHECKINGANTENNA" 6 "ENABLINGSIM" 5 "INITIALIZING1" 4 "RECOVERING" 3 "WAKING" 2 "SLEEPING" 1 "RESTARTING" 0 "ABORTINGLINK" ;
VAL_ 1056 UIS_suspensionGeofence 1 "REQUESTED" 0 "REMOVED" ;
VAL_ 1056 UIS_sleepType 4 "Unknown" 3 "ModernStandby" 2 "S2Idle" 1 "S3" 0 "Shallow" ;
VAL_ 1056 UIS_sleepState 3 "Wake" 2 "Sleep" 1 "Run" 0 "Boot" ;
VAL_ 1056 UIS_slackerLoginResult 5000 "SLACKER_LOGIN_CREDENTIALS_MISSING" 444 "SLACKER_LOGIN_USER_BUMPED" 412 "SLACKER_LOGIN_TOKEN_INVALID_TIMESTAMP" 409 "SLACKER_LOGIN_TOKEN_REVOKED_KEY" 403 "SLACKER_LOGIN_CAPTCHA_REQUIRED" 401 "SLACKER_LOGIN_INCORRECT_CREDENTIALS" 400 "SLACKER_LOGIN_TOKEN_INVALID_SIGNATURE" 6 "SLACKER_LOGIN_BAD_ACCOUNT_LEVEL" 5 "SLACKER_LOGIN_OTHER_ERROR" 4 "SLACKER_LOGIN_NET_ERROR" 3 "SLACKER_LOGIN_TOKEN_UNKNOWN_ERROR" 2 "SLACKER_LOGIN_SUCCESS" 1 "SLACKER_LOGIN_SERVERTIME_FAILED" ;
VAL_ 1056 UIS_settingsAutoTurnSignal 1 "AUTO_CANCEL" 0 "OFF" ;
VAL_ 1056 UIS_sentryState 5 "QUIET" 4 "PANIC" 3 "AWARE" 2 "ARMED" 1 "IDLE" 0 "OFF" ;
VAL_ 1056 UIS_scheduledChargingMode 3 "TIME_WINDOW" 2 "END_BY" 1 "START_AT" 0 "OFF" ;
VAL_ 1056 UIS_remoteRequestType 106 "NAV_GPS_DESTINATION_REQUEST" 105 "TESLA_AUTH_RESPONSE" 104 "GET_MESSAGE" 103 "SET_LIGHTBAR_DITCH" 102 "SET_LIGHTBAR_MIDDLE" 101 "SET_LIGHTBAR_BRIGHTNESS" 100 "REMOVE_PRECONDITION_SCHEDULE" 99 "ADD_PRECONDITION_SCHEDULE" 98 "REMOVE_CHARGE_SCHEDULE" 97 "ADD_CHARGE_SCHEDULE" 96 "SET_REAR_ZONE_LIGHT_REQUEST" 95 "SET_FRONT_ZONE_LIGHT_REQUEST" 94 "SET_TENT_MODE_REQUEST" 93 "SET_POWERSHARE_REQUEST" 92 "SET_POWERSHARE_DISCHARGE_LIMIT" 91 "SET_POWERSHARE_FEATURE" 90 "NAVIGATION_WAYPOINTS_REQUEST" 89 "VEHICLE_CONTROL_RESET_PIN_TO_DRIVE_ADMIN" 88 "SET_TRUCK_BED_LIGHT_BRIGHTNESS" 87 "SET_TRUCK_BED_LIGHT_AUTO_STATE" 86 "SET_TRAILER_LIGHT_TEST_START_STOP" 85 "SET_POWER_FEED_SOC_LIMIT" 84 "SET_POWER_FEED_TIMER" 83 "SET_POWER_FEED_ON_OFF" 82 "SET_OUTLET_SOC_LIMIT" 81 "SET_OUTLET_TIMER" 80 "SET_OUTLETS_ON_OFF" 79 "DRIVING_CLEAR_SPEED_LIMIT_PIN_ADMIN" 78 "VEHICLE_CONTROL_RESET_PIN_TO_DRIVE" 77 "VEHICLE_CONTROL_SET_PIN_TO_DRIVE" 76 "RESERVED_SEVENTY_SIX" 75 "GET_CHARGE_ON_SOLAR_FEATURE" 74 "UPDATE_CHARGE_ON_SOLAR_FEATURE" 73 "GET_MANAGED_CHARGING_SITES" 72 "ERASE_USER_DATA" 71 "STW_HEAT_LEVEL" 70 "AUTO_STW_HEAT" 69 "NAVIGATION_ROUTE" 68 "REMOVE_MANAGED_CHARGING_SITE" 67 "ADD_MANAGED_CHARGING_SITE" 66 "SET_COP_TEMP" 65 "GUEST_MODE" 64 "BOOMBOX" 63 "BLUETOOTH_CLASSIC_PAIRING_REQUEST" 62 "CHARGE_PORT_DOOR_OPEN" 61 "CHARGE_PORT_DOOR_CLOSE" 60 "RESERVED_SIXTY" 59 "RESERVED_FIFTY_NINE" 58 "TAKE_DRIVENOTE" 57 "VIDEO_REQUEST" 56 "GET_RATE_TARIFF" 55 "RESERVED_FIFTY_FIVE" 54 "SET_VEHICLE_NAME" 53 "NAVIGATION_GPS_REQUEST" 52 "PSEUDONYM_SYNC_REQUEST" 51 "PII_KEY_REQUEST" 50 "SET_CABIN_OVERHEAT_PROTECTION" 49 "HVAC_SEAT_COOLER_ACTIONS" 48 "AUTO_SEAT_CLIMATE" 47 "DASHCAM_SAVE_CLIP" 46 "PING" 45 "HVAC_RECIRCULATION" 44 "HVAC_CLIMATE_KEEPER" 43 "SET_CHARGING_AMPS" 42 "SCHEDULED_DEPARTURE" 41 "SCHEDULED_CHARGING" 40 "VITALS_ACK" 39 "VITALS_SUBSCRIPTION" 38 "VEHICLE_DATA_ACK" 37 "VEHICLE_DATA_SUBSCRIPTION" 36 "HVAC_SEAT_HEATER_ACTIONS" 35 "HVAC_BIO_WEAPON_MODE" 34 "VEHICLE_CONTROL_WINDOW" 33 "VEHICLE_CONTROL_TRIGGER_HOMELINK" 32 "VEHICLE_CONTROL_SUNROOF_OPEN_CLOSE" 31 "VEHICLE_CONTROL_SET_VALET_MODE" 30 "VEHICLE_CONTROL_SET_SENTRY_MODE" 29 "VEHICLE_CONTROL_SCHEDULE_SOFTWARE_UPDATE" 28 "VEHICLE_CONTROL_RESET_VALET_PIN" 27 "VEHICLE_CONTROL_HONK_HORN" 26 "VEHICLE_CONTROL_FLASH_LIGHTS" 25 "VEHICLE_CONTROL_CANCEL_SOFTWARE_UPDATE" 24 "UI_SET_UPCOMING_CALENDAR_ENTRIES" 23 "GET_NEARBY_CHARGING_SITES" 22 "NAVIGATION_SUPERCHARGER_REQUEST" 21 "NAVIGATION_REQUEST" 20 "MEDIA_PREVIOUS_TRACK" 19 "MEDIA_NEXT_TRACK" 18 "MEDIA_PREVIOUS_FAVORITE" 17 "MEDIA_NEXT_FAVORITE" 16 "MEDIA_UPDATE_VOLUME" 15 "MEDIA_PLAY" 14 "HVAC_TEMPERATURE_ADJUSTMENT" 13 "HVAC_STEERING_WHEEL_HEATER" 12 "HVAC_SET_PRECONDITIONING_MAX" 11 "RESERVED_ELEVEN" 10 "HVAC_AUTO" 9 "DRIVING_SPEED_LIMIT" 8 "DRIVING_SET_SPEED_LIMIT" 7 "DRIVING_CLEAR_SPEED_LIMIT_PIN" 6 "CHARGING_START_STOP" 5 "CHARGING_SET_LIMIT" 4 "STREAM_MESSAGE" 3 "CREATE_STREAM_SESSION" 2 "REMOTE_START_DRIVE" 1 "GET_VEHICLE_DATA" 0 "UNKNOWN" ;
VAL_ 1056 UIS_rearDisplayUserPresent 1 "TRUE" 0 "FALSE" ;
VAL_ 1056 UIS_rearDisplayState 9 "ENTERTAINMENT" 8 "DOG" 7 "SENTRY" 6 "LOCK" 5 "CHARGING" 4 "DRIVING" 3 "ON" 2 "ACCESSORY" 1 "DIM" 0 "OFF" ;
VAL_ 1056 UIS_powerManagerState 31 "PMS_ENTERINGROBOTAXILOADSHED" 30 "PMS_ROBOTAXILOADSHEDDING" 29 "PMS_UPLOADDATA" 28 "PMS_EXTREMELOADSHEDDING" 27 "PMS_ENTERINGEXTREMELOADSHED" 26 "PMS_PREPARINGSLEEP" 25 "PMS_ENTERINGLOADSHED" 24 "PMS_SENTRYACTIVE" 23 "PMS_EXITINGLOADSHED" 22 "PMS_LOADSHEDDING" 21 "PMS_EXITINGSENTRY" 20 "PMS_SENTRYARMED" 19 "PMS_ENTERINGSENTRY" 18 "PMS_UNKNOWN_SNA" 17 "PMS_EXITINGSLEEP" 16 "PMS_READYFORSLEEP" 15 "PMS_WAITINGONRAILS" 14 "PMS_PERFORMANCE" 13 "PMS_HIGHPOWERSTARTED" 12 "PMS_HIGHPOWERSTOPPING" 11 "PMS_HIGHPOWERSTARTING" 10 "PMS_REBOOT" 9 "PMS_ENTERINGSLEEP" 8 "PMS_ALLTUCKEDIN" 7 "PMS_CHARGING" 6 "PMS_AUDIOSTOPPED" 5 "PMS_AUDIOSTOPPING" 4 "PMS_POWERBROWNOUT" 3 "PMS_AUDIOSTARTING" 2 "PMS_ACCDELAY" 1 "PMS_FULLPOWER" 0 "PMS_CHECKING" ;
VAL_ 1056 UIS_odinStatusCmdResult 2 "EXCEPTION" 1 "FAIL" 0 "PASS" ;
VAL_ 1056 UIS_odinProcessState 4 "UNKNOWN" 3 "RUNNING_NETWORK_AND_ORCHESTRATOR" 2 "RUNNING_ORCHESTRATOR" 1 "RUNNING_NETWORK" 0 "IDLE" ;
VAL_ 1056 UIS_odinListTasksCmdResult 2 "EXCEPTION" 1 "FAIL" 0 "PASS" ;
VAL_ 1056 UIS_odinHrlUploadLimits 1 "CELL_DAILY_UPLOAD_LIMIT_REACHED" 0 "DAILY_UPLOAD_LIMIT_REACHED" ;
VAL_ 1056 UIS_odinHrlLogUploadState 4 "HRL_FILE_UPLOADED" 3 "HRL_FILE_UPLOAD_FAILED" 2 "HRL_FILE_TRANSFER_FAILED" 1 "HRL_FILE_TRANSFERRED" 0 "SERVICE_STARTED" ;
VAL_ 1056 UIS_odinHermesConnectionState 3 "CONNECTION_ERROR" 2 "CONNECTING" 1 "CONNECTED" 0 "DISCONNECTED" ;
VAL_ 1056 UIS_odinGatewayConnectionState 2 "CONNECTION_ERROR" 1 "CONNECTED" 0 "DISCONNECTED" ;
VAL_ 1056 UIS_odinFileSystemState 4 "DIR_SIZE_LIMIT_SURPASSED" 3 "OVERSIZED_FILE" 2 "DIR_DELETED" 1 "FILE_DELETED" 0 "IDLE" ;
VAL_ 1056 UIS_odinEcuLogUploadState 5 "FAILURE" 4 "COMPLETE" 3 "UPLOADING" 2 "GET_DATA" 1 "POLLING" 0 "IDLE" ;
VAL_ 1056 UIS_odinEcuLogForceTriggerUpload 1 "REQUESTED" 0 "IDLE" ;
VAL_ 1056 UIS_mounterdState 9 "MOUNTING_STEAM" 8 "MOUNTING_LIGHTSHOW" 7 "MOUNTING_UPDATE" 6 "MOUNTING_MEDIA" 5 "MOUNTING_ENCRYPTION" 4 "MOUNTING_DASHCAM" 3 "UNMOUNTING" 2 "IDLE" 1 "TERMINATED" 0 "INVALID" ;
VAL_ 1056 UIS_modemECallppAvail 1 "ENABLED" 0 "DISABLED" ;
VAL_ 1056 UIS_modemBusyActive 1 "RUNNING" 0 "OFF" ;
VAL_ 1056 UIS_mirrorGeofenceActive 1 "TRUE" 0 "FALSE" ;
VAL_ 1056 UIS_mediaPlaybackStatus 2 "PAUSED" 1 "PLAYING" 0 "STOPPED" ;
VAL_ 1056 UIS_mediaNeedAuthToken 1 "TRUE" 0 "FALSE" ;
VAL_ 1056 UIS_inSuperchargerGeofence 1 "TRUE" 0 "FALSE" ;
VAL_ 1056 UIS_homelinkState 23 "HW_ERROR" 22 "UNIVERSAL_RECEIVER_ERROR" 21 "UNIVERSAL_RECEIVER_SUCCESS" 20 "UNIVERSAL_RECEIVER_WAIT" 19 "DEFAULT_FAIL" 18 "DEFAULT_SUCCESS" 17 "DEFAULT_WAIT" 16 "STANDARD_FAIL" 15 "STANDARD_SUCCESS" 14 "STANDARD_WAIT" 13 "CLEAR_FAIL" 12 "CLEAR_SUCCESS" 11 "CLEAR_WAIT" 10 "TIMEOUT" 9 "LEARN_FAIL" 8 "LEARN_CANCLE" 7 "LEARN_SUCCESS_NOT_ROLLING" 6 "LEARN_SUCCESS_ROLLING" 5 "LEARN_TEST" 4 "LEARN_SUCCESS" 3 "LEARN_WAIT" 2 "PROGRAM_WAIT" 1 "TRANSMITTING" 0 "IDLE" ;
VAL_ 1056 UIS_headsetPairResult 23 "HID_PAIRED" 22 "HID_MAX_NR_OF_CONNS" 21 "HID_PAGE_TIMEOUT" 20 "HID_OETC_USER" 19 "HID_REJ_BY_REMOTE_NO_RES" 18 "HID_LMP_RESPONSE_TIMEOUT" 17 "HID_AUTH_FAILURE" 16 "HID_KEY_MISSING" 15 "HID_NO_RESPONSE" 14 "HID_ALREADY_REQUESTED_BY_REMOTE" 13 "HID_UNKNOWN" 12 "HID_UNPAIRED" 11 "PAIRED" 10 "MAX_NR_OF_CONNS" 9 "PAGE_TIMEOUT" 8 "OETC_USER" 7 "REJ_BY_REMOTE_NO_RES" 6 "LMP_RESPONSE_TIMEOUT" 5 "AUTH_FAILURE" 4 "KEY_MISSING" 3 "NO_RESPONSE" 2 "ALREADY_REQUESTED_BY_REMOTE" 1 "UNKNOWN" 0 "UNPAIRED" ;
VAL_ 1056 UIS_headsetConnectionState 77 "HID_ERROR_UNKNOWN" 76 "HID_ERROR_ANTENNA_DISCONNECTED" 75 "HID_CONNECTED" 74 "HID_CONNECT_CANCELLED" 73 "HID_CONNECT_PROFILE_UNAVAILABLE" 72 "HID_CONNECT_INVALID_ARGUMENT" 71 "HID_CONNECT_ADAPTER_OFF" 70 "HID_CONNECT_NOT_SUPPORTED" 69 "HID_CONNECT_ALREADY_CONN" 68 "HID_CONNECT_DEVICE_NOT_FOUND_NO_RESOURCES" 67 "HID_CONNECT_DEVICE_NOT_FOUND_PAGE_TIMEOUT" 66 "HID_CONNECT_DEVICE_NOT_FOUND" 65 "HID_CONNECT_FAILED_REMOTE_TERMINATED" 64 "HID_CONNECT_FAILED_NO_RESOURCES" 63 "HID_CONNECT_FAILED_CONNECTION_TIMEOUT" 62 "HID_CONNECT_FAILED" 61 "HID_CONNECT_SDP_FAILURE" 60 "HID_CONNECT_PIN_MISSING" 59 "HID_CONNECT_PAGE_TIMEOUT" 58 "HID_CONNECT_REJ_BY_REMOTE_NO_RES" 57 "HID_CONNECT_MAX_NR_OF_CONNS" 56 "HID_CONNECT_CONTROLLER_BUSY" 55 "HID_CONNECT_CONN_TIMEOUT" 54 "HID_CONNECT_MAX_NR_OF_ACL" 53 "HID_CONNECT_LMP_RESPONSE_TIMEOUT" 52 "HID_CONNECT_HOST_TIMEOUT" 51 "HID_CONNECT_UNKNOWN_FAILURE" 50 "HID_DISCONNECT_UNKNOWN" 49 "HID_DISCONNECT_OETC_POWERING_OFF" 48 "HID_DISCONNECT_OETC_LOW_RESOURCE" 47 "HID_DISCONNECT_REJ_BY_REMOTE_SEC" 46 "HID_DISCONNECT_AUTH_FAIL" 45 "HID_DISCONNECT_LMP_RESPONSE_TIMEOUT" 44 "HID_DISCONNECT_OETC_USER" 43 "HID_DISCONNECT_CONN_TIMEOUT" 42 "HID_DISCONNECT_CONN_TERM_LOCAL_HOST" 41 "HID_DISCONNECT_LINKLOSS" 40 "HID_DISCONNECT_FROM_REMOTE" 39 "HID_DISCONNECTED" 38 "ERROR_UNKNOWN" 37 "ERROR_ANTENNA_DISCONNECTED" 36 "CONNECTED" 35 "CONNECT_CANCELLED" 34 "CONNECT_PROFILE_UNAVAILABLE" 33 "CONNECT_INVALID_ARGUMENT" 32 "CONNECT_ADAPTER_OFF" 31 "CONNECT_NOT_SUPPORTED" 30 "CONNECT_ALREADY_CONN" 29 "CONNECT_DEVICE_NOT_FOUND_NO_RESOURCES" 28 "CONNECT_DEVICE_NOT_FOUND_PAGE_TIMEOUT" 27 "CONNECT_DEVICE_NOT_FOUND" 26 "CONNECT_FAILED_REMOTE_TERMINATED" 25 "CONNECT_FAILED_NO_RESOURCES" 24 "CONNECT_FAILED_CONNECTION_TIMEOUT" 23 "CONNECT_FAILED" 22 "CONNECT_SDP_FAILURE" 21 "CONNECT_PIN_MISSING" 20 "CONNECT_PAGE_TIMEOUT" 19 "CONNECT_REJ_BY_REMOTE_NO_RES" 18 "CONNECT_MAX_NR_OF_CONNS" 17 "CONNECT_CONTROLLER_BUSY" 16 "CONNECT_CONN_TIMEOUT" 15 "CONNECT_MAX_NR_OF_ACL" 14 "CONNECT_LMP_RESPONSE_TIMEOUT" 13 "CONNECT_HOST_TIMEOUT" 12 "CONNECT_UNKNOWN_FAILURE" 11 "DISCONNECT_UNKNOWN" 10 "DISCONNECT_OETC_POWERING_OFF" 9 "DISCONNECT_OETC_LOW_RESOURCE" 8 "DISCONNECT_REJ_BY_REMOTE_SEC" 7 "DISCONNECT_AUTH_FAIL" 6 "DISCONNECT_LMP_RESPONSE_TIMEOUT" 5 "DISCONNECT_OETC_USER" 4 "DISCONNECT_CONN_TIMEOUT" 3 "DISCONNECT_CONN_TERM_LOCAL_HOST" 2 "DISCONNECT_LINKLOSS" 1 "DISCONNECT_FROM_REMOTE" 0 "DISCONNECTED" ;
VAL_ 1056 UIS_firmwareReleaseScope 2 "PROD" 1 "DEV" 0 "UNKNOWN" ;
VAL_ 1056 UIS_embeddedGameState 2 "FROZEN" 1 "PLAYING" 0 "STOPPED" ;
VAL_ 1056 UIS_embeddedGameName 2 "POLYTOPIA" 1 "SOLITAIRE" 0 "NONE" ;
VAL_ 1056 UIS_dumTclipUploadState 7 "TclipStateDone" 6 "TclipStateUploading" 5 "TclipStateWaiting" 4 "TclipStateTransferring" 3 "TclipStatePolling" 2 "TclipStateChecking" 1 "TclipStateIdle" 0 "TclipStateSNA" ;
VAL_ 1056 UIS_dmRearPowerState 1 "ON" 0 "OFF" ;
VAL_ 1056 UIS_dmRearLinkCheckOk 1 "PASSED" 0 "FAILED" ;
VAL_ 1056 UIS_dmRearBacklightPowerLevel 2 "HIGH_POWER" 1 "LOW_POWER" 0 "OFF" ;
VAL_ 1056 UIS_dmRearBacklightDevExists 1 "PASSED" 0 "FAILED" ;
VAL_ 1056 UIS_dmIcuPowerState 1 "ON" 0 "OFF" ;
VAL_ 1056 UIS_dmIcuLinkCheckOk 1 "PASSED" 0 "FAILED" ;
VAL_ 1056 UIS_dmIcuBacklightPowerLevel 2 "HIGH_POWER" 1 "LOW_POWER" 0 "OFF" ;
VAL_ 1056 UIS_dmIcuBacklightDevExists 1 "PASSED" 0 "FAILED" ;
VAL_ 1056 UIS_dmIcuAsilResumeFlag 4 "ACI_ERROR_RESET" 3 "SOFTWARE_RESET" 2 "REBOOT_RESET" 1 "WATCHDOG_RESET" 0 "GLOBAL_RESET" ;
VAL_ 1056 UIS_dmIcuAsilFirmwareStatus 3 "NORMAL_RUN" 2 "CALIBRATION_DONE" 1 "CALIBRATION" 0 "INITIAL_STAGE" ;
VAL_ 1056 UIS_dmCenterSOsdExactCrcCheck 2 "PASS" 1 "EXPECT_MATCH_FAIL" 0 "EXPECT_MISMATCH_FAIL" ;
VAL_ 1056 UIS_dmCenterPowerState 1 "ON" 0 "OFF" ;
VAL_ 1056 UIS_dmCenterOsdDisplayedState 1 "SHOWING" 0 "HIDDEN" ;
VAL_ 1056 UIS_dmCenterOsdDayNightState 1 "DAY" 0 "NIGHT" ;
VAL_ 1056 UIS_dmCenterModeSettingStatus 1 "PASSED" 0 "FAILED" ;
VAL_ 1056 UIS_dmCenterMOsdExactCrcCheck 2 "PASS" 1 "EXPECT_MATCH_FAIL" 0 "EXPECT_MISMATCH_FAIL" ;
VAL_ 1056 UIS_dmCenterLinkCheckOk 1 "PASSED" 0 "FAILED" ;
VAL_ 1056 UIS_dmCenterBacklightPowerLevel 2 "HIGH_POWER" 1 "LOW_POWER" 0 "OFF" ;
VAL_ 1056 UIS_dmCenterBacklightDevExists 1 "PASSED" 0 "FAILED" ;
VAL_ 1056 UIS_dmCenterAsilResumeFlag 4 "ACI_ERROR_RESET" 3 "SOFTWARE_RESET" 2 "REBOOT_RESET" 1 "WATCHDOG_RESET" 0 "GLOBAL_RESET" ;
VAL_ 1056 UIS_dmCenterAsilFirmwareStatus 3 "NORMAL_RUN" 2 "CALIBRATION_DONE" 1 "CALIBRATION" 0 "INITIAL_STAGE" ;
VAL_ 1056 UIS_dashcamStorageState 8 "RECENT_BUFFER_DURATION_REDUCED" 7 "SLOW" 6 "READ_ONLY" 5 "FULL" 4 "GETTING_FULL" 3 "ERROR" 2 "READY" 1 "REMOVED" 0 "INVALID" ;
VAL_ 1056 UIS_dashcamState 7 "STREAMING" 6 "SAVING" 5 "PAUSED" 4 "RECORDING" 3 "STOPPED" 2 "ERROR" 1 "TERMINATED" 0 "INVALID" ;
VAL_ 1056 UIS_compositorFrameMonitorState 6 "DISCONNECTED" 5 "OK" 4 "STALLED" 3 "STALLING" 2 "CORRUPT_TIMECODE" 1 "UNKNOWN_FAILURE" 0 "UNKNOWN" ;
VAL_ 1056 UIS_clusterDisplayState 9 "ENTERTAINMENT" 8 "DOG" 7 "SENTRY" 6 "LOCK" 5 "CHARGING" 4 "DRIVING" 3 "ON" 2 "ACCESSORY" 1 "DIM" 0 "OFF" ;
VAL_ 1056 UIS_chargeOnSolarNoChargeReason 3 "ALTERNATIVE_VEHICLE_CHARGE_PRIORITY" 2 "GRID_EXPORT_PRIORITY" 1 "POWERWALL_CHRAGE_PRIORITY" 0 "INSUFFICIENT_SOLAR" ;
VAL_ 1056 UIS_centerDisplayState 9 "ENTERTAINMENT" 8 "DOG" 7 "SENTRY" 6 "LOCK" 5 "CHARGING" 4 "DRIVING" 3 "ON" 2 "ACCESSORY" 1 "DIM" 0 "OFF" ;
VAL_ 1056 UIS_centerDisplayEvent 21 "CPD_TRIGGERED" 20 "CAR_LOCKED" 19 "ENTERTAINMENT_OFF" 18 "ALL_STATES_EXCEPT_ENTERTAINMENT_TURNED_ON" 17 "IC_HAZARDS_OFF_DOOR_CLOSED_NO_OCCUPANTS" 16 "IC_HAZARDS_ON" 15 "ALL_DOORS_CLOSED_NO_OCCUPANTS_CHARGE_ACTIVE" 14 "TIMEOUT" 13 "DOOR_HANDLE_PULLED" 12 "ALL_STATES_EXCEPT_SENTRY" 11 "SENTRY_PANIC_ENDED" 10 "POWER_OFF_REQUEST" 9 "DRIVE_RAIL_OFF_NO_DRIVER_PRESENT" 8 "DRIVE_RAIL_OFF_DOOR_OPEN" 7 "DRIVE_RAIL_OFF_DRIVE_PRESENT" 6 "POWER_ON_REQUEST" 5 "DOOR_OPENED" 4 "ALL_STATES_EXCEPT_ENTERTAINMENT_DRIVE_RAIL_TURNED_ON" 3 "ALL_DOORS_CLOSED_NO_OCCUPANTS" 2 "PASSED_SPEED_THRESHOLD" 1 "SHIFTED_P_TO_N" 0 "OTHER" ;
VAL_ 1056 UIS_cellularLinkManagerState 16 "INVALID" 15 "RUNNING" 14 "DISCONNECTING" 13 "ROAMINGDISALLOWED" 12 "ENTERINGAIRPLANEMODE" 11 "CHECKING" 10 "RETRYING" 9 "CONFIGURING" 8 "CONNECTING" 7 "OFONOMODEMRELOADING" 6 "SEARCHING" 5 "CONFIGURINGAPN" 4 "QUERYDIAGNOSTIC" 3 "STARTING" 2 "UPDATING" 1 "RESETTING" 0 "RECOVERING" ;
VAL_ 1056 UIS_carAssistState 5 "GROK" 4 "DICTATION" 3 "COMMAND" 2 "ERROR" 1 "IDLE" 0 "DISABLED" ;
VAL_ 1056 UIS_carAssistErrorCode 17 "CLIENT_LOGGED_OUT_TOKEN_EXPIRED" 16 "CLIENT_PROVIDER_RATE_LIMTED" 15 "CLIENT_PROVIDER_AT_CAPACITY" 14 "CLIENT_ANON_USAGE_LIMITED" 13 "CLIENT_PREM_CONN" 12 "CLIENT_SPEECH" 11 "CLIENT_REMOTE" 10 "CLIENT_DBUS" 9 "CLIENT_DISCONNECTED" 8 "CLIENT_CONNECTIVITY" 7 "CLIENT_AUDIO" 6 "CLIENT_ERROR" 5 "COMMAND_NOT_IMPLEMENTED" 4 "COMMAND_NOT_AVAILABLE" 3 "COMMAND_NOT_UNDERSTOOD" 2 "REMOTE_ERROR" 1 "REMOTE_UNKNOWN" 0 "NONE" ;
VAL_ 1056 UIS_cameraRRepeaterStreamMissing 1 "MISSING" 0 "ACTIVE" ;
VAL_ 1056 UIS_cameraRRepeaterStream 2 "ACTIVE" 1 "REQUESTED" 0 "INACTIVE" ;
VAL_ 1056 UIS_cameraRRepeaterPopup 1 "OPEN" 0 "CLOSED" ;
VAL_ 1056 UIS_cameraRRepeaterPipeline 4 "PLAYING" 3 "PAUSED" 2 "READY" 1 "NULL" 0 "SLEEP" ;
VAL_ 1056 UIS_cameraLRepeaterStreamMissing 1 "MISSING" 0 "ACTIVE" ;
VAL_ 1056 UIS_cameraLRepeaterStream 2 "ACTIVE" 1 "REQUESTED" 0 "INACTIVE" ;
VAL_ 1056 UIS_cameraLRepeaterPopup 1 "OPEN" 0 "CLOSED" ;
VAL_ 1056 UIS_cameraLRepeaterPipeline 4 "PLAYING" 3 "PAUSED" 2 "READY" 1 "NULL" 0 "SLEEP" ;
VAL_ 1056 UIS_cameraFrontStreamMissing 1 "MISSING" 0 "ACTIVE" ;
VAL_ 1056 UIS_cameraFrontStream 2 "ACTIVE" 1 "REQUESTED" 0 "INACTIVE" ;
VAL_ 1056 UIS_cameraFrontPopup 1 "OPEN" 0 "CLOSED" ;
VAL_ 1056 UIS_cameraFrontPipeline 4 "PLAYING" 3 "PAUSED" 2 "READY" 1 "NULL" 0 "SLEEP" ;
VAL_ 1056 UIS_cameraBackupStreamQuality 4 "EXCELLENT" 3 "GOOD" 2 "FAIR" 1 "POOR" 0 "UNKNOWN" ;
VAL_ 1056 UIS_cameraBackupStreamMissing 1 "MISSING" 0 "ACTIVE" ;
VAL_ 1056 UIS_cameraBackupStream 2 "ACTIVE" 1 "REQUESTED" 0 "INACTIVE" ;
VAL_ 1056 UIS_cameraBackupPopup 1 "OPEN" 0 "CLOSED" ;
VAL_ 1056 UIS_cameraBackupPipeline 4 "PLAYING" 3 "PAUSED" 2 "READY" 1 "NULL" 0 "SLEEP" ;
VAL_ 1056 UIS_bluetoothStackState 4 "ON_BLUEZ" 3 "ON_SYNERGY" 2 "ON_LGIT" 1 "ON" 0 "OFF" ;
VAL_ 1056 UIS_bluetoothStackRearState 4 "ON_BLUEZ" 3 "ON_SYNERGY" 2 "ON_LGIT" 1 "ON" 0 "OFF" ;
VAL_ 1056 UIS_bluetoothPairResult 23 "HID_PAIRED" 22 "HID_MAX_NR_OF_CONNS" 21 "HID_PAGE_TIMEOUT" 20 "HID_OETC_USER" 19 "HID_REJ_BY_REMOTE_NO_RES" 18 "HID_LMP_RESPONSE_TIMEOUT" 17 "HID_AUTH_FAILURE" 16 "HID_KEY_MISSING" 15 "HID_NO_RESPONSE" 14 "HID_ALREADY_REQUESTED_BY_REMOTE" 13 "HID_UNKNOWN" 12 "HID_UNPAIRED" 11 "PAIRED" 10 "MAX_NR_OF_CONNS" 9 "PAGE_TIMEOUT" 8 "OETC_USER" 7 "REJ_BY_REMOTE_NO_RES" 6 "LMP_RESPONSE_TIMEOUT" 5 "AUTH_FAILURE" 4 "KEY_MISSING" 3 "NO_RESPONSE" 2 "ALREADY_REQUESTED_BY_REMOTE" 1 "UNKNOWN" 0 "UNPAIRED" ;
VAL_ 1056 UIS_bluetoothConnectionState 77 "HID_ERROR_UNKNOWN" 76 "HID_ERROR_ANTENNA_DISCONNECTED" 75 "HID_CONNECTED" 74 "HID_CONNECT_CANCELLED" 73 "HID_CONNECT_PROFILE_UNAVAILABLE" 72 "HID_CONNECT_INVALID_ARGUMENT" 71 "HID_CONNECT_ADAPTER_OFF" 70 "HID_CONNECT_NOT_SUPPORTED" 69 "HID_CONNECT_ALREADY_CONN" 68 "HID_CONNECT_DEVICE_NOT_FOUND_NO_RESOURCES" 67 "HID_CONNECT_DEVICE_NOT_FOUND_PAGE_TIMEOUT" 66 "HID_CONNECT_DEVICE_NOT_FOUND" 65 "HID_CONNECT_FAILED_REMOTE_TERMINATED" 64 "HID_CONNECT_FAILED_NO_RESOURCES" 63 "HID_CONNECT_FAILED_CONNECTION_TIMEOUT" 62 "HID_CONNECT_FAILED" 61 "HID_CONNECT_SDP_FAILURE" 60 "HID_CONNECT_PIN_MISSING" 59 "HID_CONNECT_PAGE_TIMEOUT" 58 "HID_CONNECT_REJ_BY_REMOTE_NO_RES" 57 "HID_CONNECT_MAX_NR_OF_CONNS" 56 "HID_CONNECT_CONTROLLER_BUSY" 55 "HID_CONNECT_CONN_TIMEOUT" 54 "HID_CONNECT_MAX_NR_OF_ACL" 53 "HID_CONNECT_LMP_RESPONSE_TIMEOUT" 52 "HID_CONNECT_HOST_TIMEOUT" 51 "HID_CONNECT_UNKNOWN_FAILURE" 50 "HID_DISCONNECT_UNKNOWN" 49 "HID_DISCONNECT_OETC_POWERING_OFF" 48 "HID_DISCONNECT_OETC_LOW_RESOURCE" 47 "HID_DISCONNECT_REJ_BY_REMOTE_SEC" 46 "HID_DISCONNECT_AUTH_FAIL" 45 "HID_DISCONNECT_LMP_RESPONSE_TIMEOUT" 44 "HID_DISCONNECT_OETC_USER" 43 "HID_DISCONNECT_CONN_TIMEOUT" 42 "HID_DISCONNECT_CONN_TERM_LOCAL_HOST" 41 "HID_DISCONNECT_LINKLOSS" 40 "HID_DISCONNECT_FROM_REMOTE" 39 "HID_DISCONNECTED" 38 "ERROR_UNKNOWN" 37 "ERROR_ANTENNA_DISCONNECTED" 36 "CONNECTED" 35 "CONNECT_CANCELLED" 34 "CONNECT_PROFILE_UNAVAILABLE" 33 "CONNECT_INVALID_ARGUMENT" 32 "CONNECT_ADAPTER_OFF" 31 "CONNECT_NOT_SUPPORTED" 30 "CONNECT_ALREADY_CONN" 29 "CONNECT_DEVICE_NOT_FOUND_NO_RESOURCES" 28 "CONNECT_DEVICE_NOT_FOUND_PAGE_TIMEOUT" 27 "CONNECT_DEVICE_NOT_FOUND" 26 "CONNECT_FAILED_REMOTE_TERMINATED" 25 "CONNECT_FAILED_NO_RESOURCES" 24 "CONNECT_FAILED_CONNECTION_TIMEOUT" 23 "CONNECT_FAILED" 22 "CONNECT_SDP_FAILURE" 21 "CONNECT_PIN_MISSING" 20 "CONNECT_PAGE_TIMEOUT" 19 "CONNECT_REJ_BY_REMOTE_NO_RES" 18 "CONNECT_MAX_NR_OF_CONNS" 17 "CONNECT_CONTROLLER_BUSY" 16 "CONNECT_CONN_TIMEOUT" 15 "CONNECT_MAX_NR_OF_ACL" 14 "CONNECT_LMP_RESPONSE_TIMEOUT" 13 "CONNECT_HOST_TIMEOUT" 12 "CONNECT_UNKNOWN_FAILURE" 11 "DISCONNECT_UNKNOWN" 10 "DISCONNECT_OETC_POWERING_OFF" 9 "DISCONNECT_OETC_LOW_RESOURCE" 8 "DISCONNECT_REJ_BY_REMOTE_SEC" 7 "DISCONNECT_AUTH_FAIL" 6 "DISCONNECT_LMP_RESPONSE_TIMEOUT" 5 "DISCONNECT_OETC_USER" 4 "DISCONNECT_CONN_TIMEOUT" 3 "DISCONNECT_CONN_TERM_LOCAL_HOST" 2 "DISCONNECT_LINKLOSS" 1 "DISCONNECT_FROM_REMOTE" 0 "DISCONNECTED" ;
VAL_ 1056 UIS_bluetoothAutoConnectionState 3 "MANUAL_CONNECT_REQUESTED" 2 "GAVE_UP" 1 "CONNECTED" 0 "IDLE" ;
VAL_ 1056 UIS_audioType 4 "BASE_WITH_PREMIUM200" 3 "PREMIUM" 2 "BASE" 1 "NO_A2B" 0 "INVALID" ;
VAL_ 1056 UIS_audioState 7 "SLEEPING" 6 "AUDIO_NOT_PUMPING" 5 "A2B_REDISCOVERY" 4 "HFP_PUMPING" 3 "AUDIO_PUMPING" 2 "UNINITIALIZING" 1 "INITIALIZING" 0 "TERMINATED" ;
VAL_ 1056 UIS_audioSource 5 "NONE" 4 "PHONE_RX" 3 "BLUETOOTH" 2 "MICROPHONE" 1 "TUNER" 0 "MEDIA" ;
VAL_ 1056 UIS_audioMediaPlaying 39 "SODA_MUSIC" 38 "CARAOKE" 37 "KUGOU" 36 "YOUTUBE_MUSIC" 35 "YUNTING" 34 "AMAZON_MUSIC" 33 "AUDIBLE" 32 "APPLE_PODCASTS" 31 "APPLE_MUSIC" 30 "MINI_PROGRAMS" 29 "SEARCH" 28 "HOME_APPS" 27 "RECENTS_FAVORITES" 26 "TOYBOX" 25 "TUTORIAL" 24 "THEATER" 23 "BROWSER" 22 "GAME" 21 "NET_EASE_MUSIC" 20 "ONLINE_RADIO" 19 "XIMALAYA" 18 "QQ_MUSIC2" 17 "QQ_MUSIC1" 16 "TIDAL" 15 "SIRIUS_XM" 14 "STINGRAY" 13 "TUNE_IN" 12 "EU_RADIO" 11 "US_RADIO" 10 "SPOTIFY" 9 "SLACKER" 8 "BLUETOOTH" 7 "USB" 6 "DAB" 5 "XM" 4 "FM" 3 "AM" 2 "UNKNOWN" 1 "DEPRECATED" 0 "NONE" ;
VAL_ 1056 UIS_audioMediaBrowsing 39 "SODA_MUSIC" 38 "CARAOKE" 37 "KUGOU" 36 "YOUTUBE_MUSIC" 35 "YUNTING" 34 "AMAZON_MUSIC" 33 "AUDIBLE" 32 "APPLE_PODCASTS" 31 "APPLE_MUSIC" 30 "MINI_PROGRAMS" 29 "SEARCH" 28 "HOME_APPS" 27 "RECENTS_FAVORITES" 26 "TOYBOX" 25 "TUTORIAL" 24 "THEATER" 23 "BROWSER" 22 "GAME" 21 "NET_EASE_MUSIC" 20 "ONLINE_RADIO" 19 "XIMALAYA" 18 "QQ_MUSIC2" 17 "QQ_MUSIC1" 16 "TIDAL" 15 "SIRIUS_XM" 14 "STINGRAY" 13 "TUNE_IN" 12 "EU_RADIO" 11 "US_RADIO" 10 "SPOTIFY" 9 "SLACKER" 8 "BLUETOOTH" 7 "USB" 6 "DAB" 5 "XM" 4 "FM" 3 "AM" 2 "UNKNOWN" 1 "DEPRECATED" 0 "NONE" ;
VAL_ 1056 UIS_activeAppView 67 "SODA_MUSIC" 66 "HICAR" 65 "CARAOKE_WEB" 64 "KUGOU" 63 "YOUTUBE_MUSIC" 62 "YUNTING" 61 "ONLINE_RADIO" 60 "AMAZON_MUSIC" 59 "AUDIBLE" 58 "APPLE_PODCASTS" 57 "ONBOARDING_MANUAL" 56 "APPLE_MUSIC" 55 "ZOOM" 54 "MINI_PROGRAMS" 53 "CADMIUM" 52 "MESSAGES" 51 "NAV_MEDIA" 50 "BACKGAMMON" 49 "SKETCH_PAD" 48 "ARCADE" 47 "XIMALAYA" 46 "BLUETOOTH" 45 "CHESS" 44 "NETEASE" 43 "OWNERS_MANUAL" 42 "QQMUSIC" 41 "RELEASE_NOTES" 40 "SONIC" 39 "USB" 38 "THEATER" 37 "TIDAL" 36 "TUNEIN" 35 "CARAOKE" 34 "STREAMING" 33 "RADIO" 32 "SPOTIFY" 31 "CAMERA" 30 "CHARGE" 29 "MEDIA" 28 "ENTERTAINMENT" 27 "WEB" 26 "CALENDAR" 25 "TOYBOX" 24 "PHONE" 23 "ENERGY" 22 "TUTORIAL" 21 "CERULEAN" 20 "TOPAZ" 19 "DASHCAM" 18 "CARBONADO" 17 "THEATERVIEW" 16 "MAMBU" 15 "COBALT" 14 "TESLATARI" 13 "SERVICE_APPS" 12 "LIME" 11 "TEARDROP" 10 "NAV" 9 "PURPLE" 8 "CALICO" 7 "CARWASH" 6 "2048" 5 "CONTROLS" 4 "COLORIZER" 3 "XM" 2 "DEVELOPMENT" 1 "NONE" 0 "UNKNOWN" ;
